VERSION ""

NS_ :

BS_:

BU_: TM

BO_ 475 HU_IC_Event_WarningAlert_Ack: 8 Vector__XXX
 SG_ HuIcAlertFeatureTypeAck : 5|2@0+ (1,0) [0|3] ""  TM
 SG_ HuIcAlertFeaturePresenceAck : 7|1@0+ (1,0) [0|1] ""  TM

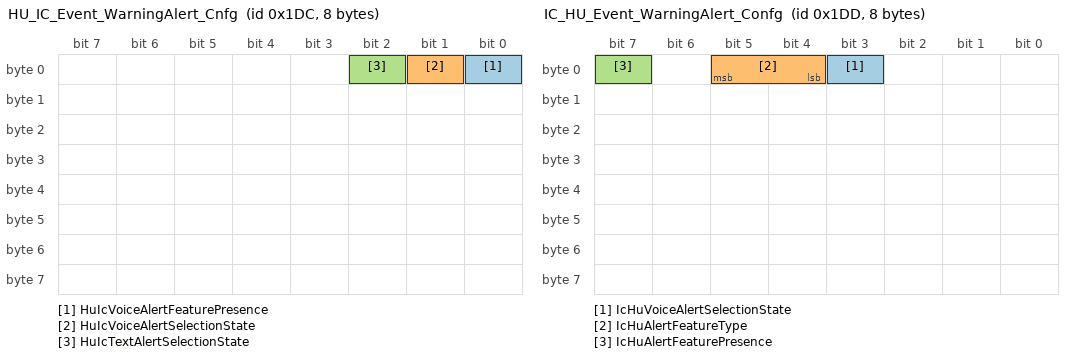
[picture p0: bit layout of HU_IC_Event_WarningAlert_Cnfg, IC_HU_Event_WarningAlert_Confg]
BO_ 476 HU_IC_Event_WarningAlert_Cnfg: 8 Vector__XXX
 SG_ HuIcVoiceAlertFeaturePresence : 0|1@0+ (1,0) [0|1] ""  TM
 SG_ HuIcVoiceAlertSelectionState : 1|1@0+ (1,0) [0|1] ""  TM
 SG_ HuIcTextAlertSelectionState : 2|1@0+ (1,0) [0|1] ""  TM

BO_ 477 IC_HU_Event_WarningAlert_Confg: 8 Vector__XXX
 SG_ IcHuVoiceAlertSelectionState : 3|1@0+ (1,0) [0|1] ""  TM
 SG_ IcHuAlertFeatureType : 5|2@0+ (1,0) [0|3] ""  TM
 SG_ IcHuAlertFeaturePresence : 7|1@0+ (1,0) [0|1] ""  TM

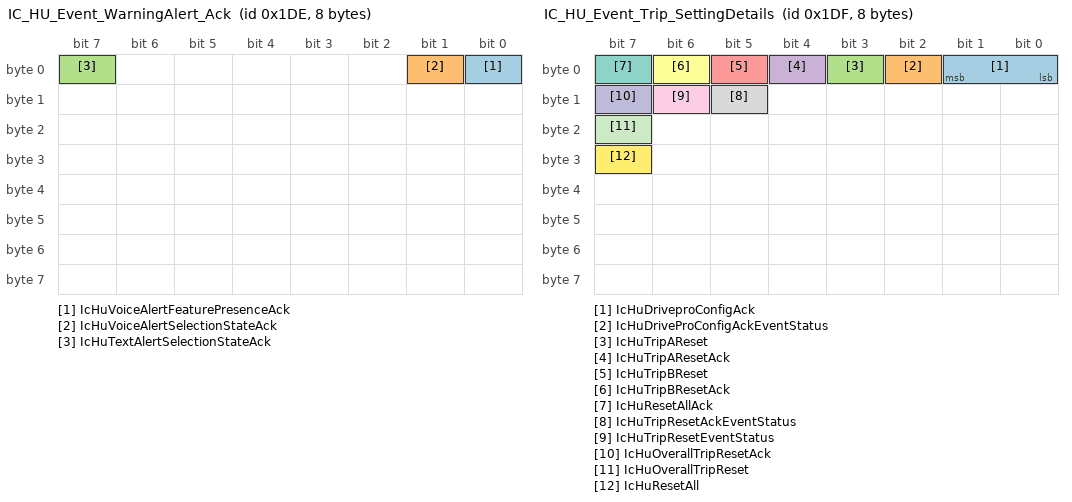
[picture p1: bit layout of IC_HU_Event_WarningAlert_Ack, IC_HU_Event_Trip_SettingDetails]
BO_ 478 IC_HU_Event_WarningAlert_Ack: 8 Vector__XXX
 SG_ IcHuVoiceAlertFeaturePresenceAck : 0|1@0+ (1,0) [0|1] ""  TM
 SG_ IcHuVoiceAlertSelectionStateAck : 1|1@0+ (1,0) [0|1] ""  TM
 SG_ IcHuTextAlertSelectionStateAck : 7|1@0+ (1,0) [0|1] ""  TM

BO_ 479 IC_HU_Event_Trip_SettingDetails: 8 Vector__XXX
 SG_ IcHuDriveproConfigAck : 1|2@0+ (1,0) [0|3] ""  TM
 SG_ IcHuDriveProConfigAckEventStatus : 2|1@0+ (1,0) [0|1] ""  TM
 SG_ IcHuTripAReset : 3|1@0+ (1,0) [0|1] ""  TM
 SG_ IcHuTripAResetAck : 4|1@0+ (1,0) [0|1] ""  TM
 SG_ IcHuTripBReset : 5|1@0+ (1,0) [0|1] ""  TM
 SG_ IcHuTripBResetAck : 6|1@0+ (1,0) [0|1] ""  TM
 SG_ IcHuResetAllAck : 7|1@0+ (1,0) [0|1] ""  TM
 SG_ IcHuTripResetAckEventStatus : 13|1@0+ (1,0) [0|1] ""  TM
 SG_ IcHuTripResetEventStatus : 14|1@0+ (1,0) [0|1] ""  TM
 SG_ IcHuOverallTripResetAck : 15|1@0+ (1,0) [0|1] ""  TM
 SG_ IcHuOverallTripReset : 23|1@0+ (1,0) [0|1] ""  TM
 SG_ IcHuResetAll : 31|1@0+ (1,0) [0|1] ""  TM

BO_ 480 BCM_PEPS_Event_UIDAuthState: 8 Vector__XXX
 SG_ UIDAuthState : 1|2@0+ (1,0) [0|3] ""  TM

BO_ 484 PEPSBCMEventMsg_RC: 8 Vector__XXX
 SG_ UnLockTailgageCommand : 0|1@0+ (1,0) [0|1] ""  TM
 SG_ UnLockAllDoorCommand : 1|1@0+ (1,0) [0|1] ""  TM
 SG_ UnLockDrDoorCommandStatus : 3|2@0+ (1,0) [0|3] ""  TM
 SG_ UnLockDrDoorCommand : 4|1@0+ (1,0) [0|1] ""  TM
 SG_ VehicleLockCommandStatus : 6|2@0+ (1,0) [0|3] ""  TM
 SG_ VehicleLockCommand : 7|1@0+ (1,0) [0|1] ""  TM
 SG_ ForcePanicCommand : 8|1@0+ (1,0) [0|1] ""  TM
 SG_ ApproachLighCommandStatus : 10|2@0+ (1,0) [0|3] ""  TM
 SG_ ApproachLighCommand : 11|1@0+ (1,0) [0|1] ""  TM
 SG_ UnLockTailgageCommandStatus : 13|2@0+ (1,0) [0|3] ""  TM
 SG_ UnLockAllDoorCommandStatus : 15|2@0+ (1,0) [0|3] ""  TM
 SG_ WindowUpCommandStatus : 17|2@0+ (1,0) [0|3] ""  TM
 SG_ WindowUpCommand : 18|1@0+ (1,0) [0|1] ""  TM
 SG_ WindowDownCommandStatus : 20|2@0+ (1,0) [0|3] ""  TM
 SG_ WindowDownCommand : 21|1@0+ (1,0) [0|1] ""  TM
 SG_ ForcePanicCommandStatus : 23|2@0+ (1,0) [0|3] ""  TM
 SG_ Reserved : 28|5@0+ (1,0) [0|31] ""  TM
 SG_ VehicleSeekCommandStatus : 30|2@0+ (1,0) [0|3] ""  TM
 SG_ VehicleSeekCommand : 31|1@0+ (1,0) [0|1] ""  TM
 SG_ RandomNumber0 : 39|8@0+ (1,0) [0|255] ""  TM
 SG_ RandomNumber1 : 47|8@0+ (1,0) [0|255] ""  TM
 SG_ RandomNumber2 : 55|8@0+ (1,0) [0|255] ""  TM
 SG_ RandomNumber3 : 63|8@0+ (1,0) [0|255] ""  TM

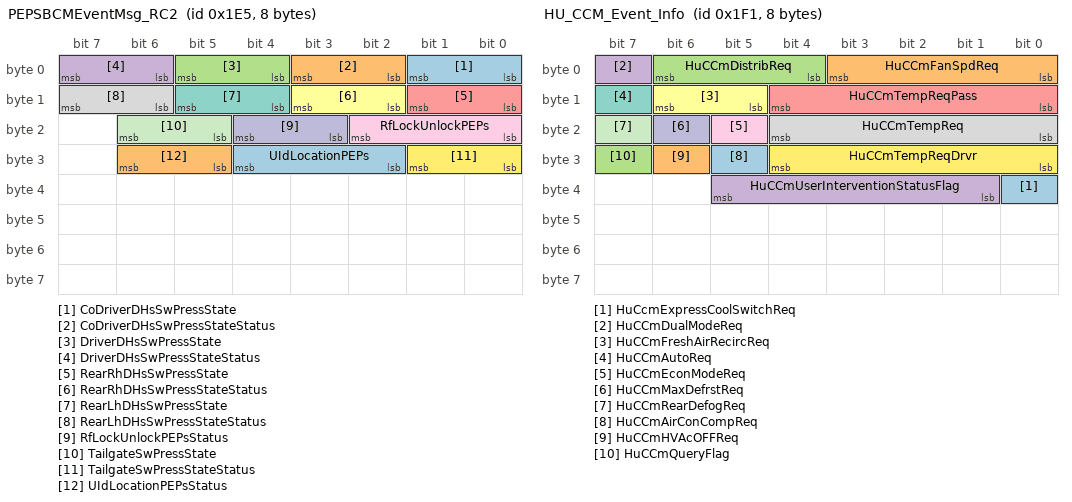
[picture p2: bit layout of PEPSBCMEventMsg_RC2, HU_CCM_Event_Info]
BO_ 485 PEPSBCMEventMsg_RC2: 8 Vector__XXX
 SG_ CoDriverDHsSwPressState : 1|2@0+ (1,0) [0|3] ""  TM
 SG_ CoDriverDHsSwPressStateStatus : 3|2@0+ (1,0) [0|3] ""  TM
 SG_ DriverDHsSwPressState : 5|2@0+ (1,0) [0|3] ""  TM
 SG_ DriverDHsSwPressStateStatus : 7|2@0+ (1,0) [0|3] ""  TM
 SG_ RearRhDHsSwPressState : 9|2@0+ (1,0) [0|3] ""  TM
 SG_ RearRhDHsSwPressStateStatus : 11|2@0+ (1,0) [0|3] ""  TM
 SG_ RearLhDHsSwPressState : 13|2@0+ (1,0) [0|3] ""  TM
 SG_ RearLhDHsSwPressStateStatus : 15|2@0+ (1,0) [0|3] ""  TM
 SG_ RfLockUnlockPEPs : 18|3@0+ (1,0) [0|7] ""  TM
 SG_ RfLockUnlockPEPsStatus : 20|2@0+ (1,0) [0|3] ""  TM
 SG_ TailgateSwPressState : 22|2@0+ (1,0) [0|3] ""  TM
 SG_ TailgateSwPressStateStatus : 25|2@0+ (1,0) [0|3] ""  TM
 SG_ UIdLocationPEPs : 28|3@0+ (1,0) [0|7] ""  TM
 SG_ UIdLocationPEPsStatus : 30|2@0+ (1,0) [0|3] ""  TM

BO_ 486 PEPSESCLAuthReq_RC: 8 Vector__XXX
 SG_ PEPsESClAuthReq : 7|64@0+ (1,0) [0|0] ""  TM

BO_ 488 ESCLPEPSAuthReq_RC: 8 Vector__XXX
 SG_ ESClPEPsAuthReq : 7|64@0+ (1,0) [0|0] ""  TM

BO_ 490 PEPSVIdeninfoEvent: 8 Vector__XXX
 SG_ VInInfoToIPC : 7|40@0+ (1,0) [0|0] ""  TM

BO_ 492 VehIdetNumIPCEvent: 8 Vector__XXX
 SG_ VehIdetNumIPC : 7|40@0+ (1,0) [0|0] ""  TM

BO_ 494 PEPSBCMEventMsgEncypt_RC: 8 Vector__XXX
 SG_ PEPsBCmAuthMsg2 : 7|64@0+ (1,0) [0|0] "ASCII"  TM

BO_ 497 HU_CCM_Event_Info: 8 Vector__XXX
 SG_ HuCcmExpressCoolSwitchReq : 32|1@0+ (1,0) [0|1] ""  TM
 SG_ HuCCmFanSpdReq : 3|4@0+ (1,0) [0|15] ""  TM
 SG_ HuCCmDistribReq : 6|3@0+ (1,0) [0|7] ""  TM
 SG_ HuCCmDualModeReq : 7|1@0+ (1,0) [0|1] ""  TM
 SG_ HuCCmTempReqPass : 12|5@0+ (0.5,0) [0|31] "Deg "  TM
 SG_ HuCCmFreshAirRecircReq : 14|2@0+ (1,0) [0|3] ""  TM
 SG_ HuCCmAutoReq : 15|1@0+ (1,0) [0|1] ""  TM
 SG_ HuCCmTempReq : 20|5@0+ (0.5,0) [0|31] "Deg "  TM
 SG_ HuCCmEconModeReq : 21|1@0+ (1,0) [0|1] ""  TM
 SG_ HuCCmMaxDefrstReq : 22|1@0+ (1,0) [0|1] ""  TM
 SG_ HuCCmRearDefogReq : 23|1@0+ (1,0) [0|1] ""  TM
 SG_ HuCCmTempReqDrvr : 28|5@0+ (0.5,0) [0|31] "Deg "  TM
 SG_ HuCCmAirConCompReq : 29|1@0+ (1,0) [0|1] ""  TM
 SG_ HuCCmHVAcOFFReq : 30|1@0+ (1,0) [0|1] ""  TM
 SG_ HuCCmQueryFlag : 31|1@0+ (1,0) [0|1] ""  TM
 SG_ HuCCmUserInterventionStatusFlag : 37|5@0+ (1,0) [0|31] ""  TM

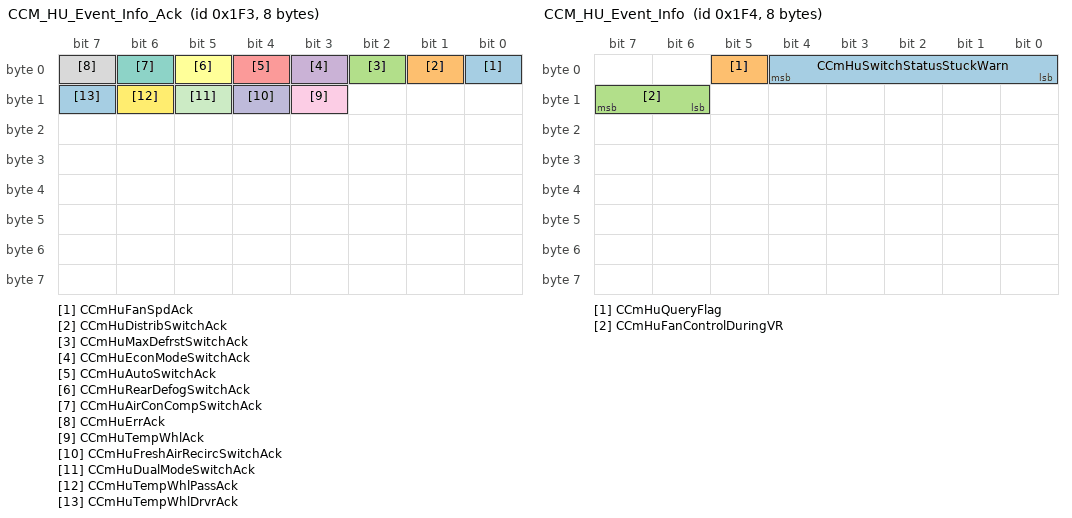
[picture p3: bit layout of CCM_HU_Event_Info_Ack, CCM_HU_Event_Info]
BO_ 499 CCM_HU_Event_Info_Ack: 8 Vector__XXX
 SG_ CCmHuFanSpdAck : 0|1@0+ (1,0) [0|1] ""  TM
 SG_ CCmHuDistribSwitchAck : 1|1@0+ (1,0) [0|1] ""  TM
 SG_ CCmHuMaxDefrstSwitchAck : 2|1@0+ (1,0) [0|1] ""  TM
 SG_ CCmHuEconModeSwitchAck : 3|1@0+ (1,0) [0|1] ""  TM
 SG_ CCmHuAutoSwitchAck : 4|1@0+ (1,0) [0|1] ""  TM
 SG_ CCmHuRearDefogSwitchAck : 5|1@0+ (1,0) [0|1] ""  TM
 SG_ CCmHuAirConCompSwitchAck : 6|1@0+ (1,0) [0|1] ""  TM
 SG_ CCmHuErrAck : 7|1@0+ (1,0) [0|1] ""  TM
 SG_ CCmHuTempWhlAck : 11|1@0+ (1,0) [0|1] ""  TM
 SG_ CCmHuFreshAirRecircSwitchAck : 12|1@0+ (1,0) [0|1] ""  TM
 SG_ CCmHuDualModeSwitchAck : 13|1@0+ (1,0) [0|1] ""  TM
 SG_ CCmHuTempWhlPassAck : 14|1@0+ (1,0) [0|1] ""  TM
 SG_ CCmHuTempWhlDrvrAck : 15|1@0+ (1,0) [0|1] ""  TM

BO_ 500 CCM_HU_Event_Info: 8 Vector__XXX
 SG_ CCmHuSwitchStatusStuckWarn : 4|5@0+ (1,0) [0|31] ""  TM
 SG_ CCmHuQueryFlag : 5|1@0+ (1,0) [0|1] ""  TM
 SG_ CCmHuFanControlDuringVR : 15|2@0+ (1,0) [0|3] ""  TM

BO_ 504 BCM_HU_Event_UCS_Feature: 8 Vector__XXX
 SG_ BCmAutoRelockActiveSignalVal : 0|1@0+ (1,0) [0|1] ""  TM
 SG_ BCmFMhActiveSignalVal : 2|2@0+ (1,0) [0|3] ""  TM
 SG_ BCmFMhSignalVal1 : 7|5@0+ (10,0) [0|310] "Sec"  TM
 SG_ BCmVehLockHornReqActiveSignalVal : 8|1@0+ (1,0) [0|1] ""  TM
 SG_ BCmApproachLampActiveSignalVal : 10|2@0+ (1,0) [0|3] ""  TM
 SG_ BCmFMhSignalVal2 : 15|5@0+ (10,0) [0|310] "Sec"  TM
 SG_ BCmDriveAwayLockingActiveSignalV : 16|1@0+ (1,0) [0|1] ""  TM
 SG_ BCmRKeUnlockState : 17|1@0+ (1,0) [0|1] ""  TM
 SG_ BCmPKeUnlockState : 18|1@0+ (1,0) [0|1] ""  TM
 SG_ BCmFMhSignalVal3 : 23|5@0+ (10,0) [0|310] "Sec"  TM
 SG_ BCmAutoRelockState : 24|1@0+ (1,0) [0|1] ""  TM
 SG_ BCmFMhState : 25|1@0+ (1,0) [0|1] ""  TM
 SG_ BCmUCsState : 26|1@0+ (1,0) [0|1] ""  TM
 SG_ BCmApproachLampSignalVal1 : 31|5@0+ (10,0) [0|310] "Sec"  TM
 SG_ BCmPKeUnlockActiveSignalVal : 32|1@0+ (1,0) [0|1] ""  TM
 SG_ BCmRKeUnlockActiveSignalVal : 33|1@0+ (1,0) [0|1] ""  TM
 SG_ BCmDriveAwayLockingState : 34|1@0+ (1,0) [0|1] ""  TM
 SG_ BCmApproachLampSignalVal2 : 39|5@0+ (10,0) [0|310] "Sec"  TM
 SG_ AmbLightModeIllumOnHu : 40|1@0+ (1,0) [0|1] ""  TM
 SG_ BCmApproachLampState : 41|1@0+ (1,0) [0|1] ""  TM
 SG_ BCmVehLockHornReqState : 42|1@0+ (1,0) [0|1] ""  TM
 SG_ BCmApproachLampSignalVal3 : 47|5@0+ (10,0) [0|310] "Sec"  TM
 SG_ BCmDRLActiveSignalVal : 51|1@0+ (1,0) [0|1] ""  TM
 SG_ BCmDRLState : 52|1@0+ (1,0) [0|1] ""  TM
 SG_ BCmMoodLightState : 53|1@0+ (1,0) [0|1] ""  TM
 SG_ BCmUcsData : 55|2@0+ (1,0) [0|3] ""  TM

BO_ 505 BCM_HU_Event_Mood_Light_Feature: 8 Vector__XXX
 SG_ BCmMoodLightAllAreaActiveValue : 0|1@0+ (1,0) [0|1] ""  TM
 SG_ BCmMoodLightIllumSelActiveVal : 3|3@0+ (1,0) [0|7] ""  TM
 SG_ BCmMoodLightActiveColour : 7|4@0+ (1,0) [0|15] ""  TM
 SG_ BCmMoodLightRearAreaActiveValue : 8|1@0+ (1,0) [0|1] ""  TM
 SG_ BCmMoodLightFrontRHAreaActiveVal : 9|1@0+ (1,0) [0|1] ""  TM
 SG_ BCmMoodLightFloorConsoleAreaActi : 10|1@0+ (1,0) [0|1] ""  TM
 SG_ BCmMoodLightData : 12|2@0+ (1,0) [0|3] ""  TM
 SG_ BCmMoodLightIllumPossibleLevels : 15|3@0+ (1,0) [0|7] ""  TM
 SG_ BCmMoodLightHotMagentaColorSelOn : 16|1@0+ (1,0) [0|1] ""  TM
 SG_ BCmMoodLightGoldYellowColorSelOn : 17|1@0+ (1,0) [0|1] ""  TM
 SG_ BCmMoodLightFrenchLimeColorSelOn : 18|1@0+ (1,0) [0|1] ""  TM
 SG_ BCmMoodLightFrontLHAreaActiveVal : 19|1@0+ (1,0) [0|1] ""  TM
 SG_ BCmMoodLightPossibleModes : 21|2@0+ (1,0) [0|3] ""  TM
 SG_ BCmMoodLightActiveModeValue : 23|2@0+ (1,0) [0|3] ""  TM
 SG_ BCmMoodLightPolarBrightWhiteColo : 24|1@0+ (1,0) [0|1] ""  TM
 SG_ BCmMoodLightAeroBlueColorSelOnHU : 25|1@0+ (1,0) [0|1] ""  TM
 SG_ BCmMoodLightPurpleColorSelOnHU : 26|1@0+ (1,0) [0|1] ""  TM
 SG_ BCmMoodLightFluorescentGreenColo : 27|1@0+ (1,0) [0|1] ""  TM
 SG_ BCmMoodLightCyanBlueColorSelOnHU : 28|1@0+ (1,0) [0|1] ""  TM
 SG_ BCmMoodLightCoolBlueColorSelOnHU : 29|1@0+ (1,0) [0|1] ""  TM
 SG_ BCmMoodLightIvoryOFFWhiteColorSe : 30|1@0+ (1,0) [0|1] ""  TM
 SG_ BCmMoodLightIceBlueColorSelOnHU : 31|1@0+ (1,0) [0|1] ""  TM
 SG_ BCmMoodLightTuscanRedColorSelOnH : 32|1@0+ (1,0) [0|1] ""  TM
 SG_ BCmMoodLightTealGreenColorSelOnH : 33|1@0+ (1,0) [0|1] ""  TM
 SG_ BCmMoodLightRubyRedColorSelOnHU : 34|1@0+ (1,0) [0|1] ""  TM
 SG_ BCmMoodLightOrangeColorSelOnHU : 35|1@0+ (1,0) [0|1] ""  TM
 SG_ BCmMoodLightPurpleTaupeColorSelO : 36|1@0+ (1,0) [0|1] ""  TM
 SG_ BCmMoodLightLocationSel : 37|1@0+ (1,0) [0|1] ""  TM
 SG_ BCmMoodLightAllAreaSelOnHU : 38|1@0+ (1,0) [0|1] ""  TM
 SG_ BCmMoodLightFrontLHAreaSelOnHU : 39|1@0+ (1,0) [0|1] ""  TM
 SG_ BCmMoodLightRearAreaSelOnHU : 40|1@0+ (1,0) [0|1] ""  TM
 SG_ BCmMoodLightFloorConsoleAreaSelO : 41|1@0+ (1,0) [0|1] ""  TM
 SG_ BCmMoodLightState : 42|1@0+ (1,0) [0|1] ""  TM
 SG_ BCmMoodLightFrontRHAreaSelOnHU : 43|1@0+ (1,0) [0|1] ""  TM

CM_ SG_ 475 HuIcAlertFeatureTypeAck "This signal is transmitted to IC to acknowledge after HMI settings";
CM_ SG_ 475 HuIcAlertFeaturePresenceAck "Ack from HU for Alert feature presence";
CM_ SG_ 476 HuIcVoiceAlertFeaturePresence "This signal is transmitted to IC to know voice alert feature presence in vehicle.";
CM_ SG_ 476 HuIcVoiceAlertSelectionState "This signal is transmitted to IC to know selection state of voice alert feature..";
CM_ SG_ 476 HuIcTextAlertSelectionState "Informs Text alert selection state";
CM_ SG_ 477 IcHuVoiceAlertSelectionState "HU shall update the Voice Alert HMI selection state";
CM_ SG_ 477 IcHuAlertFeatureType "Informs the type of alert configured in cluster";
CM_ SG_ 477 IcHuAlertFeaturePresence "Informes whether Alert feature is enabled or not";
CM_ SG_ 478 IcHuVoiceAlertFeaturePresenceAck "This signal is transmitted to HU to know voice alert feature presence in vehicle";
CM_ SG_ 478 IcHuVoiceAlertSelectionStateAck "This signal is transmitted to HU to know selection state of voice alert feature.";
CM_ SG_ 478 IcHuTextAlertSelectionStateAck "Informes ack state of Text alert selection state";
CM_ SG_ 479 IcHuDriveproConfigAck "IC shall send drive pro config Ack to HU";
CM_ SG_ 479 IcHuDriveProConfigAckEventStatus "IC shall send Trip Config Ack Event Status to HU";
CM_ SG_ 479 IcHuTripAReset "IC shall send Trip A Reset to HU";
CM_ SG_ 479 IcHuTripAResetAck "IC shall send Trip A Reset Ack to HU";
CM_ SG_ 479 IcHuTripBReset "IC shall send Trip B Reset to HU";
CM_ SG_ 479 IcHuTripBResetAck "IC shall send Trip B Reset Ack to HU";
CM_ SG_ 479 IcHuResetAllAck "IC shall send Reset All Ack to HU";
CM_ SG_ 479 IcHuTripResetAckEventStatus "IC shall send Trip Reset Ack Event Status to HU";
CM_ SG_ 479 IcHuTripResetEventStatus "IC shall send Trip Reset Event Status to HU";
CM_ SG_ 479 IcHuOverallTripResetAck "IC shall send Overall trip Reset Ack to HU";
CM_ SG_ 479 IcHuOverallTripReset "IC shall send overall Trip Reset to HU";
CM_ SG_ 479 IcHuResetAll "IC shall send Trip A, B and Overall Reset to HU";
CM_ SG_ 480 UIDAuthState "UID authentication  response to PEPS ECU from BCM";
CM_ SG_ 484 UnLockTailgageCommand "Unlock Tailgate Command signal";
CM_ SG_ 484 UnLockAllDoorCommand "Unlock All Door Command signal";
CM_ SG_ 484 UnLockDrDoorCommandStatus "Status of the UnLockDrDoorCommand signal";
CM_ SG_ 484 UnLockDrDoorCommand "Unlock Driver Door Command signa";
CM_ SG_ 484 VehicleLockCommandStatus "Status of the 'VehicleLockCommand' signal";
CM_ SG_ 484 VehicleLockCommand "Vehicle lock command signal";
CM_ SG_ 484 ForcePanicCommand "Force panic command signal";
CM_ SG_ 484 ApproachLighCommandStatus "Status of the UnLockTailgageCommand signal";
CM_ SG_ 484 ApproachLighCommand "Apporoach Light Command signal";
CM_ SG_ 484 UnLockTailgageCommandStatus "Status of the UnLockTailgageCommand signal";
CM_ SG_ 484 UnLockAllDoorCommandStatus "Status of the UnLockAllDoorCommand signal";
CM_ SG_ 484 WindowUpCommandStatus "Status of the WindowUpCommand signal";
CM_ SG_ 484 WindowUpCommand "Window Up Command signal";
CM_ SG_ 484 WindowDownCommandStatus "Status of the WindowDownCommand signal";
CM_ SG_ 484 WindowDownCommand "Window Down Command signal";
CM_ SG_ 484 ForcePanicCommandStatus "Status of the ForcePanicCommand signal";
CM_ SG_ 484 Reserved "Reserved Bits";
CM_ SG_ 484 VehicleSeekCommandStatus "Status of the VehicleSeekCommand signal";
CM_ SG_ 484 VehicleSeekCommand "Vehicle Seek Command signal";
CM_ SG_ 484 RandomNumber0 "Random Number0";
CM_ SG_ 484 RandomNumber1 "RandomNumber1";
CM_ SG_ 484 RandomNumber2 "RandomNumber2";
CM_ SG_ 484 RandomNumber3 "RandomNumber3";
CM_ SG_ 485 CoDriverDHsSwPressState "CAN Signals From PEPS to BCM for Individual Door Lock / Unlock - Co-Driver DHS Switch Press Status";
CM_ SG_ 485 CoDriverDHsSwPressStateStatus "Status of 'CoDriverDHsSwPressState' signal";
CM_ SG_ 485 DriverDHsSwPressState "CAN Signals From PEPS to BCM for Individual Door Lock / Unlock - Driver DHS Switch Press Status";
CM_ SG_ 485 DriverDHsSwPressStateStatus "Status of 'DriverDHsSwPressState' signal";
CM_ SG_ 485 RearRhDHsSwPressState "CAN Signals From PEPS to BCM for Individual Door Lock / Unlock - Rear RH DHs Switch Press Status";
CM_ SG_ 485 RearRhDHsSwPressStateStatus "Status of 'RearRhDHsSwPressState' signal";
CM_ SG_ 485 RearLhDHsSwPressState "CAN Signals From PEPS to BCM for Individual Door Lock / Unlock - Rear LH DHs Switch Press Status";
CM_ SG_ 485 RearLhDHsSwPressStateStatus "Status of 'RearLhDHsSwPressState' signal";
CM_ SG_ 485 RfLockUnlockPEPs "CAN Signals From PEPS to BCM for Individual Door Lock / Unlock - RF Lock Unlock Command From PEPS";
CM_ SG_ 485 RfLockUnlockPEPsStatus "Status of 'RfLockUnlockPEPs' signal";
CM_ SG_ 485 TailgateSwPressState "CAN Signals From PEPS to BCM for Individual Door Lock / Unlock - Tailgate Switch Press Status";
CM_ SG_ 485 TailgateSwPressStateStatus "Status of 'TailgateSwPressState' signal";
CM_ SG_ 485 UIdLocationPEPs "CAN Signals From PEPS to BCM for Individual Door Lock / Unlock - UID Location From PEPS";
CM_ SG_ 485 UIdLocationPEPsStatus "Status of 'UIdLocationPEPs' signal";
CM_ SG_ 486 PEPsESClAuthReq "ESCL. Immobilization signals from PEPS to ESCL while learning";
CM_ SG_ 488 ESClPEPsAuthReq " ESCL Immobilize to PEPS. Immobilization signals from ESCL to PEPS while learning";
CM_ SG_ 497 HuCcmExpressCoolSwitchReq "Request/Acknowledgement for Express Cooling feature ON or OFF";
CM_ SG_ 497 HuCCmFanSpdReq "Indicates the speed of the fan";
CM_ SG_ 497 HuCCmDistribReq "Indicates different value of distribution mode";
CM_ SG_ 497 HuCCmDualModeReq "Indicates whether the dual mode is ON or OFF";
CM_ SG_ 497 HuCCmTempReqPass "Indicates the left temperature value in Deg";
CM_ SG_ 497 HuCCmFreshAirRecircReq "Indicates the different values of fresh air recirculation mode";
CM_ SG_ 497 HuCCmAutoReq "Request for Auto mode ON or OFF";
CM_ SG_ 497 HuCCmTempReq "Indicates the temperature value in OC";
CM_ SG_ 497 HuCCmEconModeReq "Request to set the Economy mode to ON or OFF";
CM_ SG_ 497 HuCCmMaxDefrstReq "Request for maximum defrost control ON or OFF";
CM_ SG_ 497 HuCCmRearDefogReq "Request to change the  defog control to ON or OFF";
CM_ SG_ 497 HuCCmTempReqDrvr "Indicates the right temperature value OC";
CM_ SG_ 497 HuCCmAirConCompReq "request to set the AC to ON or OFF";
CM_ SG_ 497 HuCCmHVAcOFFReq "Request to turn ON or OFF the HVAC control panel";
CM_ SG_ 497 HuCCmQueryFlag "Query the CCM to send the missing Ack frame";
CM_ SG_ 497 HuCCmUserInterventionStatusFlag "Indicates which HVAC control user has operated";
CM_ SG_ 499 CCmHuFanSpdAck "Acknowledges the display update";
CM_ SG_ 499 CCmHuDistribSwitchAck "Acknowledges the display update";
CM_ SG_ 499 CCmHuMaxDefrstSwitchAck "Acknowledges the display update";
CM_ SG_ 499 CCmHuEconModeSwitchAck "Acknowledges the display update";
CM_ SG_ 499 CCmHuAutoSwitchAck "Acknowledges the display update";
CM_ SG_ 499 CCmHuRearDefogSwitchAck "Acknowledges the display update";
CM_ SG_ 499 CCmHuAirConCompSwitchAck "Acknowledges the display update";
CM_ SG_ 499 CCmHuErrAck "Acknowledges the display update";
CM_ SG_ 499 CCmHuTempWhlAck "Acknowledges the display update";
CM_ SG_ 499 CCmHuFreshAirRecircSwitchAck "Acknowledges the display update";
CM_ SG_ 499 CCmHuDualModeSwitchAck "Acknowledges the display update";
CM_ SG_ 499 CCmHuTempWhlPassAck "Acknowledges the display update";
CM_ SG_ 499 CCmHuTempWhlDrvrAck "Acknowledges the display update";
CM_ SG_ 500 CCmHuSwitchStatusStuckWarn "Indicates the button/s stuck status";
CM_ SG_ 500 CCmHuQueryFlag "Query the HU to send the missing frame";
CM_ SG_ 500 CCmHuFanControlDuringVR "To Control FAN speed during VR session";
CM_ SG_ 504 BCmAutoRelockActiveSignalVal "Active Value for Vehicle Auto Relock Feature";
CM_ SG_ 504 BCmFMhActiveSignalVal "Active value for Follow Me Home feature";
CM_ SG_ 504 BCmFMhSignalVal1 "1st Possible value for Follow Me Home Feature";
CM_ SG_ 504 BCmVehLockHornReqActiveSignalVal "Active Value for Vehicle Lock Horn Request feature";
CM_ SG_ 504 BCmApproachLampActiveSignalVal "Active value for Approach Lamp Active feature";
CM_ SG_ 504 BCmFMhSignalVal2 "2nd Possible value for Follow Me Home Feature";
CM_ SG_ 504 BCmDriveAwayLockingActiveSignalV "Active Value for Vehicle Drive Away Feature";
CM_ SG_ 504 BCmRKeUnlockState "Vehicle unlock with RKE Feature - Enable / Disable";
CM_ SG_ 504 BCmPKeUnlockState "Vehicle unlock with PKE Feature - Enable / Disable";
CM_ SG_ 504 BCmFMhSignalVal3 "3rd Possible value for Follow Me Home Feature";
CM_ SG_ 504 BCmAutoRelockState "Auto relock function Feature - Enable / Disable";
CM_ SG_ 504 BCmFMhState "Follow Me Home Feature - Enable / Disable";
CM_ SG_ 504 BCmUCsState "User customisation settings feature enable/disable parameter published by BCM";
CM_ SG_ 504 BCmApproachLampSignalVal1 "1st Possible value for Approach Lamp Feature";
CM_ SG_ 504 BCmPKeUnlockActiveSignalVal "Active Value for Vehicle Unlock with PKE Feature";
CM_ SG_ 504 BCmRKeUnlockActiveSignalVal "Active Value for Vehicle Unlock with RKE Feature";
CM_ SG_ 504 BCmDriveAwayLockingState "Drive away locking Feature - Enable / Disable";
CM_ SG_ 504 BCmApproachLampSignalVal2 "2nd Possible value for Approach Lamp Feature";
CM_ SG_ 504 AmbLightModeIllumOnHu "Mode and Illumination Display on HU send by BCM";
CM_ SG_ 504 BCmApproachLampState "Approach lamp Feature - Enable / Disable";
CM_ SG_ 504 BCmVehLockHornReqState "Horn request on vehicle lock Feature - Enable / Disable";
CM_ SG_ 504 BCmApproachLampSignalVal3 "3rd Possible value for Approach Lamp Feature";
CM_ SG_ 504 BCmDRLActiveSignalVal "Active Value for DRL Feature";
CM_ SG_ 504 BCmDRLState "DRL Feature - Enable / Disable";
CM_ SG_ 504 BCmMoodLightState "Current state of Mood Lighting from BCM to HU.";
CM_ SG_ 504 BCmUcsData "BCM sends UCS config data or give acknowledgement to HU.";
CM_ SG_ 505 BCmMoodLightAllAreaActiveValue "Current status of All area location selection from BCM to HU";
CM_ SG_ 505 BCmMoodLightIllumSelActiveVal "Current mood light illumination from BCM to HU";
CM_ SG_ 505 BCmMoodLightActiveColour "Mood light Active Colour from BCM to HU";
CM_ SG_ 505 BCmMoodLightRearAreaActiveValue "Current status of Rear area location selection from BCM to HU";
CM_ SG_ 505 BCmMoodLightFrontRHAreaActiveVal "Current status of driver area location selection from BCM to HU";
CM_ SG_ 505 BCmMoodLightFloorConsoleAreaActi "Current status of Floor area location selection from BCM to HU";
CM_ SG_ 505 BCmMoodLightData "BCM sends Mood light data frame or give acknowledgement to HU.";
CM_ SG_ 505 BCmMoodLightIllumPossibleLevels "Mood Light Number of illumination levels  to be displayed on HU send by BCM";
CM_ SG_ 505 BCmMoodLightHotMagentaColorSelOn "Mood light Hot Magenta colour selection on HU sent by BCM";
CM_ SG_ 505 BCmMoodLightGoldYellowColorSelOn "Mood light Gold Yellow colour selection on HU sent by BCM";
CM_ SG_ 505 BCmMoodLightFrenchLimeColorSelOn "Mood light French Lime colour selection on HU sent by BCM";
CM_ SG_ 505 BCmMoodLightFrontLHAreaActiveVal "Current status of co-driver area location selection from BCM to HU";
CM_ SG_ 505 BCmMoodLightPossibleModes "Mood light Possible Modes from BCM to HU";
CM_ SG_ 505 BCmMoodLightActiveModeValue "Mood light active mode from BCM to HU
";
CM_ SG_ 505 BCmMoodLightPolarBrightWhiteColo "Mood light polar colour selection on HU sent by BCM";
CM_ SG_ 505 BCmMoodLightAeroBlueColorSelOnHU "Mood light Aero Blue colour selection on HU sent by BCM";
CM_ SG_ 505 BCmMoodLightPurpleColorSelOnHU "Mood light purple colour selection on HU sent by BCM";
CM_ SG_ 505 BCmMoodLightFluorescentGreenColo "Mood lightFluroscent Green colour selection on HU sent by BCM";
CM_ SG_ 505 BCmMoodLightCyanBlueColorSelOnHU "Mood light Cyan Blue colour selection on HU sent by BCM";
CM_ SG_ 505 BCmMoodLightCoolBlueColorSelOnHU "Mood light Cool Blue color selection on HU sent by BCM";
CM_ SG_ 505 BCmMoodLightIvoryOFFWhiteColorSe "Mood light Ivory colour selection on HU sent by BCM";
CM_ SG_ 505 BCmMoodLightIceBlueColorSelOnHU "Mood light Ice Blue color selection on HU sent by BCM";
CM_ SG_ 505 BCmMoodLightTuscanRedColorSelOnH "Mood light Tuscan Red colour selection on HU sent by BCM";
CM_ SG_ 505 BCmMoodLightTealGreenColorSelOnH "Mood light Teal Green colour selection on HU sent by BCM";
CM_ SG_ 505 BCmMoodLightRubyRedColorSelOnHU "Mood light Ruby Red colour selection on HU sent by BCM";
CM_ SG_ 505 BCmMoodLightOrangeColorSelOnHU "Mood light Orange colour selection on HU sent by BCM";
CM_ SG_ 505 BCmMoodLightPurpleTaupeColorSelO "Mood light Purple Taupe colour selection on HU sent by BCM";
CM_ SG_ 505 BCmMoodLightLocationSel "Mood Lighting Location selection on HU";
CM_ SG_ 505 BCmMoodLightAllAreaSelOnHU "Mood Light All area location selection on HU send by BCM";
CM_ SG_ 505 BCmMoodLightFrontLHAreaSelOnHU "Mood Light co-driver area location selection on HU send by BCM";
CM_ SG_ 505 BCmMoodLightRearAreaSelOnHU "Mood Light Rear area location selection on HU send by BCM";
CM_ SG_ 505 BCmMoodLightFloorConsoleAreaSelO "Mood Light Floor Console area location selection on HU send by BCM";
CM_ SG_ 505 BCmMoodLightState "Current state of Mood Lighting from BCM to HU.";
CM_ SG_ 505 BCmMoodLightFrontRHAreaSelOnHU "Mood Light driver area location selection on HU send by BCM";
BA_DEF_ SG_  "Remarks" STRING ;
BA_DEF_ SG_  "NWM_WakeupAllowed" ENUM  "No","Yes";
BA_DEF_ SG_  "GenSigTimeoutTime_HU_Mid_X451" INT 0 65535;
BA_DEF_ SG_  "GenSigTimeoutTime_HU_High_X451" INT 0 65535;
BA_DEF_ SG_  "GenSigTimeoutTime_HU_B" INT 0 65535;
BA_DEF_ SG_  "GenSigTimeoutTime_HU_A" INT 0 65535;
BA_DEF_ SG_  "GenSigTimeoutTime_BCM_Mid" INT 0 65535;
BA_DEF_ SG_  "GenSigTimeoutMsg_HU_Mid_X451" INT 0 65535;
BA_DEF_ SG_  "GenSigTimeoutMsg_HU_High_X451" INT 0 65535;
BA_DEF_ SG_  "GenSigTimeoutMsg_HU_B" INT 0 65535;
BA_DEF_ SG_  "GenSigTimeoutMsg_HU_A" INT 0 65535;
BA_DEF_ SG_  "GenSigStartValue" INT 0 0;
BA_DEF_ SG_  "GenSigSendType" ENUM  "Cyclic","OnWrite","OnWriteWithRepetition","OnChange","OnChangeWithRepetition","IfActive","IfActiveWithRepetition","NoSigSendType","NotUsed","NotUsed","NotUsed","NotUsed","NotUsed";
BA_DEF_ SG_  "GenSigInactiveValue" INT 0 0;
BA_DEF_ SG_  "GenSigEnvVarType" ENUM  "int","float","undef";
BA_DEF_ SG_  "GenSigCycleTimeActive" INT 0 0;
BA_DEF_ SG_  "GenSigCycleTime" INT 0 0;
BA_DEF_ SG_  "GenSigTimeoutMsg_HU_High_X445" INT 0 65535;
BA_DEF_ SG_  "GenSigTimeoutMsg_HU_Mid_X445" INT 0 65535;
BA_DEF_ SG_  "GenSigTimeoutTime_HU_High_X445" INT 0 65535;
BA_DEF_ SG_  "GenSigTimeoutTime_HU_Mid_X445" INT 0 65535;
BA_DEF_ SG_  "GenSigTimeoutMsg_IVI" INT 0 65535;
BA_DEF_ SG_  "GenSigTimeoutTime_IVI" INT 0 65535;
BA_DEF_ BO_  "NmMessage" ENUM  "no","yes";
BA_DEF_ BO_  "NmAsrMessage" ENUM  "<n.a.>","No","Yes";
BA_DEF_ BO_  "MessageTimeout" INT 0 65535;
BA_DEF_ BO_  "Me" INT 0 0;
BA_DEF_ BO_  "GenMsgStartDelayTime" INT 0 0;
BA_DEF_ BO_  "GenMsgSendType" ENUM  "Cyclic","NotUsed","NotUsed","NotUsed","NotUsed","NotUsed","NotUsed","IfActive","NoMsgSendType","NotUsed";
BA_DEF_ BO_  "GenMsgNrOfRepetition" INT 0 0;
BA_DEF_ BO_  "GenMsgILSupport" ENUM  "No","Yes";
BA_DEF_ BO_  "GenMsgDelayTime" INT 0 0;
BA_DEF_ BO_  "GenMsgCycleTimeFast" INT 0 0;
BA_DEF_ BO_  "GenMsgCycleTime" INT 0 0;
BA_DEF_ BO_  "DiagUudtResponse" ENUM  "false","true";
BA_DEF_ BO_  "DiagUsdtResponse" ENUM  "false","true";
BA_DEF_ BO_  "DiagState" ENUM  "No","Yes";
BA_DEF_ BO_  "DiagResponse" ENUM  "No","Yes";
BA_DEF_ BO_  "DiagRequest" ENUM  "No","Yes";
BA_DEF_ BO_  "MsgType" ENUM  "Application","NM","NMH";
BA_DEF_ SG_  "SystemSignalLongSymbol" STRING ;
BA_DEF_DEF_  "Remarks" "null";
BA_DEF_DEF_  "NWM_WakeupAllowed" "No";
BA_DEF_DEF_  "GenSigTimeoutTime_HU_Mid_X451" 500;
BA_DEF_DEF_  "GenSigTimeoutTime_HU_High_X451" 500;
BA_DEF_DEF_  "GenSigTimeoutTime_HU_B" 500;
BA_DEF_DEF_  "GenSigTimeoutTime_HU_A" 500;
BA_DEF_DEF_  "GenSigTimeoutTime_BCM_Mid" 0;
BA_DEF_DEF_  "GenSigTimeoutMsg_HU_Mid_X451" 500;
BA_DEF_DEF_  "GenSigTimeoutMsg_HU_High_X451" 500;
BA_DEF_DEF_  "GenSigTimeoutMsg_HU_B" 500;
BA_DEF_DEF_  "GenSigTimeoutMsg_HU_A" 500;
BA_DEF_DEF_  "GenSigStartValue" 0;
BA_DEF_DEF_  "GenSigSendType" "Cyclic";
BA_DEF_DEF_  "GenSigInactiveValue" 0;
BA_DEF_DEF_  "GenSigEnvVarType" "undef";
BA_DEF_DEF_  "GenSigCycleTimeActive" 0;
BA_DEF_DEF_  "GenSigCycleTime" 0;
BA_DEF_DEF_  "GenSigTimeoutMsg_HU_High_X445" 500;
BA_DEF_DEF_  "GenSigTimeoutMsg_HU_Mid_X445" 500;
BA_DEF_DEF_  "GenSigTimeoutTime_HU_High_X445" 500;
BA_DEF_DEF_  "GenSigTimeoutTime_HU_Mid_X445" 500;
BA_DEF_DEF_  "GenSigTimeoutMsg_IVI" 500;
BA_DEF_DEF_  "GenSigTimeoutTime_IVI" 500;
BA_DEF_DEF_  "NmMessage" "no";
BA_DEF_DEF_  "NmAsrMessage" "<n.a.>";
BA_DEF_DEF_  "MessageTimeout" 500;
BA_DEF_DEF_  "Me" 0;
BA_DEF_DEF_  "GenMsgStartDelayTime" 0;
BA_DEF_DEF_  "GenMsgSendType" "Cyclic";
BA_DEF_DEF_  "GenMsgNrOfRepetition" 0;
BA_DEF_DEF_  "GenMsgILSupport" "Yes";
BA_DEF_DEF_  "GenMsgDelayTime" 0;
BA_DEF_DEF_  "GenMsgCycleTimeFast" 0;
BA_DEF_DEF_  "GenMsgCycleTime" 0;
BA_DEF_DEF_  "DiagUudtResponse" "false";
BA_DEF_DEF_  "DiagUsdtResponse" "false";
BA_DEF_DEF_  "DiagState" "No";
BA_DEF_DEF_  "DiagResponse" "No";
BA_DEF_DEF_  "DiagRequest" "No";
BA_DEF_DEF_  "MsgType" "Application";
BA_DEF_DEF_  "SystemSignalLongSymbol" "";
BA_ "MessageTimeout" BO_ 475 0;
BA_ "GenMsgSendType" BO_ 475 8;
BA_ "MessageTimeout" BO_ 476 0;
BA_ "GenMsgSendType" BO_ 476 8;
BA_ "MessageTimeout" BO_ 477 0;
BA_ "GenMsgSendType" BO_ 477 8;
BA_ "MessageTimeout" BO_ 478 0;
BA_ "GenMsgSendType" BO_ 478 8;
BA_ "MessageTimeout" BO_ 479 0;
BA_ "GenMsgSendType" BO_ 479 8;
BA_ "MessageTimeout" BO_ 480 0;
BA_ "MessageTimeout" BO_ 484 0;
BA_ "GenMsgSendType" BO_ 484 8;
BA_ "GenMsgNrOfRepetition" BO_ 484 3;
BA_ "GenMsgDelayTime" BO_ 484 100;
BA_ "GenMsgCycleTimeFast" BO_ 484 100;
BA_ "MessageTimeout" BO_ 485 0;
BA_ "GenMsgSendType" BO_ 485 8;
BA_ "GenMsgNrOfRepetition" BO_ 485 2;
BA_ "GenMsgDelayTime" BO_ 485 20;
BA_ "GenMsgCycleTimeFast" BO_ 485 20;
BA_ "MessageTimeout" BO_ 486 0;
BA_ "GenMsgSendType" BO_ 486 8;
BA_ "GenMsgNrOfRepetition" BO_ 486 1;
BA_ "MessageTimeout" BO_ 488 0;
BA_ "GenMsgSendType" BO_ 488 8;
BA_ "GenMsgNrOfRepetition" BO_ 488 1;
BA_ "MessageTimeout" BO_ 490 0;
BA_ "GenMsgSendType" BO_ 490 8;
BA_ "GenMsgNrOfRepetition" BO_ 490 1;
BA_ "MessageTimeout" BO_ 492 0;
BA_ "GenMsgSendType" BO_ 492 8;
BA_ "GenMsgNrOfRepetition" BO_ 492 3;
BA_ "GenMsgDelayTime" BO_ 492 100;
BA_ "MessageTimeout" BO_ 494 0;
BA_ "GenMsgSendType" BO_ 494 8;
BA_ "GenMsgNrOfRepetition" BO_ 494 3;
BA_ "GenMsgDelayTime" BO_ 494 100;
BA_ "GenMsgCycleTimeFast" BO_ 494 100;
BA_ "MessageTimeout" BO_ 497 0;
BA_ "GenMsgSendType" BO_ 497 8;
BA_ "MessageTimeout" BO_ 499 0;
BA_ "GenMsgSendType" BO_ 499 8;
BA_ "MessageTimeout" BO_ 500 0;
BA_ "GenMsgSendType" BO_ 500 8;
BA_ "MessageTimeout" BO_ 504 0;
BA_ "GenMsgSendType" BO_ 504 8;
BA_ "MessageTimeout" BO_ 505 0;
BA_ "GenMsgSendType" BO_ 505 8;
BA_ "GenSigTimeoutTime_HU_Mid_X451" SG_ 475 HuIcAlertFeatureTypeAck 0;
BA_ "GenSigTimeoutTime_HU_High_X451" SG_ 475 HuIcAlertFeatureTypeAck 0;
BA_ "GenSigTimeoutTime_HU_B" SG_ 475 HuIcAlertFeatureTypeAck 0;
BA_ "GenSigTimeoutTime_HU_A" SG_ 475 HuIcAlertFeatureTypeAck 0;
BA_ "GenSigTimeoutMsg_HU_Mid_X451" SG_ 475 HuIcAlertFeatureTypeAck 0;
BA_ "GenSigTimeoutMsg_HU_High_X451" SG_ 475 HuIcAlertFeatureTypeAck 0;
BA_ "GenSigTimeoutMsg_HU_B" SG_ 475 HuIcAlertFeatureTypeAck 0;
BA_ "GenSigTimeoutMsg_HU_A" SG_ 475 HuIcAlertFeatureTypeAck 0;
BA_ "GenSigSendType" SG_ 475 HuIcAlertFeatureTypeAck 1;
BA_ "GenSigTimeoutMsg_HU_High_X445" SG_ 475 HuIcAlertFeatureTypeAck 0;
BA_ "GenSigTimeoutMsg_HU_Mid_X445" SG_ 475 HuIcAlertFeatureTypeAck 0;
BA_ "GenSigTimeoutTime_HU_High_X445" SG_ 475 HuIcAlertFeatureTypeAck 0;
BA_ "GenSigTimeoutTime_HU_Mid_X445" SG_ 475 HuIcAlertFeatureTypeAck 0;
BA_ "GenSigTimeoutMsg_IVI" SG_ 475 HuIcAlertFeatureTypeAck 0;
BA_ "GenSigTimeoutTime_IVI" SG_ 475 HuIcAlertFeatureTypeAck 0;
BA_ "GenSigTimeoutTime_HU_Mid_X451" SG_ 475 HuIcAlertFeaturePresenceAck 0;
BA_ "GenSigTimeoutTime_HU_High_X451" SG_ 475 HuIcAlertFeaturePresenceAck 0;
BA_ "GenSigTimeoutTime_HU_B" SG_ 475 HuIcAlertFeaturePresenceAck 0;
BA_ "GenSigTimeoutTime_HU_A" SG_ 475 HuIcAlertFeaturePresenceAck 0;
BA_ "GenSigTimeoutMsg_HU_Mid_X451" SG_ 475 HuIcAlertFeaturePresenceAck 0;
BA_ "GenSigTimeoutMsg_HU_High_X451" SG_ 475 HuIcAlertFeaturePresenceAck 0;
BA_ "GenSigTimeoutMsg_HU_B" SG_ 475 HuIcAlertFeaturePresenceAck 0;
BA_ "GenSigTimeoutMsg_HU_A" SG_ 475 HuIcAlertFeaturePresenceAck 0;
BA_ "GenSigSendType" SG_ 475 HuIcAlertFeaturePresenceAck 1;
BA_ "GenSigTimeoutMsg_HU_High_X445" SG_ 475 HuIcAlertFeaturePresenceAck 0;
BA_ "GenSigTimeoutMsg_HU_Mid_X445" SG_ 475 HuIcAlertFeaturePresenceAck 0;
BA_ "GenSigTimeoutTime_HU_High_X445" SG_ 475 HuIcAlertFeaturePresenceAck 0;
BA_ "GenSigTimeoutTime_HU_Mid_X445" SG_ 475 HuIcAlertFeaturePresenceAck 0;
BA_ "GenSigTimeoutMsg_IVI" SG_ 475 HuIcAlertFeaturePresenceAck 0;
BA_ "GenSigTimeoutTime_IVI" SG_ 475 HuIcAlertFeaturePresenceAck 0;
BA_ "GenSigTimeoutTime_HU_Mid_X451" SG_ 476 HuIcVoiceAlertFeaturePresence 0;
BA_ "GenSigTimeoutTime_HU_High_X451" SG_ 476 HuIcVoiceAlertFeaturePresence 0;
BA_ "GenSigTimeoutTime_HU_B" SG_ 476 HuIcVoiceAlertFeaturePresence 0;
BA_ "GenSigTimeoutTime_HU_A" SG_ 476 HuIcVoiceAlertFeaturePresence 0;
BA_ "GenSigTimeoutMsg_HU_Mid_X451" SG_ 476 HuIcVoiceAlertFeaturePresence 0;
BA_ "GenSigTimeoutMsg_HU_High_X451" SG_ 476 HuIcVoiceAlertFeaturePresence 0;
BA_ "GenSigTimeoutMsg_HU_B" SG_ 476 HuIcVoiceAlertFeaturePresence 0;
BA_ "GenSigTimeoutMsg_HU_A" SG_ 476 HuIcVoiceAlertFeaturePresence 0;
BA_ "GenSigSendType" SG_ 476 HuIcVoiceAlertFeaturePresence 1;
BA_ "GenSigTimeoutMsg_HU_High_X445" SG_ 476 HuIcVoiceAlertFeaturePresence 0;
BA_ "GenSigTimeoutMsg_HU_Mid_X445" SG_ 476 HuIcVoiceAlertFeaturePresence 0;
BA_ "GenSigTimeoutTime_HU_High_X445" SG_ 476 HuIcVoiceAlertFeaturePresence 0;
BA_ "GenSigTimeoutTime_HU_Mid_X445" SG_ 476 HuIcVoiceAlertFeaturePresence 0;
BA_ "GenSigTimeoutMsg_IVI" SG_ 476 HuIcVoiceAlertFeaturePresence 0;
BA_ "GenSigTimeoutTime_IVI" SG_ 476 HuIcVoiceAlertFeaturePresence 0;
BA_ "GenSigTimeoutTime_HU_Mid_X451" SG_ 476 HuIcVoiceAlertSelectionState 0;
BA_ "GenSigTimeoutTime_HU_High_X451" SG_ 476 HuIcVoiceAlertSelectionState 0;
BA_ "GenSigTimeoutTime_HU_B" SG_ 476 HuIcVoiceAlertSelectionState 0;
BA_ "GenSigTimeoutTime_HU_A" SG_ 476 HuIcVoiceAlertSelectionState 0;
BA_ "GenSigTimeoutMsg_HU_Mid_X451" SG_ 476 HuIcVoiceAlertSelectionState 0;
BA_ "GenSigTimeoutMsg_HU_High_X451" SG_ 476 HuIcVoiceAlertSelectionState 0;
BA_ "GenSigTimeoutMsg_HU_B" SG_ 476 HuIcVoiceAlertSelectionState 0;
BA_ "GenSigTimeoutMsg_HU_A" SG_ 476 HuIcVoiceAlertSelectionState 0;
BA_ "GenSigSendType" SG_ 476 HuIcVoiceAlertSelectionState 1;
BA_ "GenSigTimeoutMsg_HU_High_X445" SG_ 476 HuIcVoiceAlertSelectionState 0;
BA_ "GenSigTimeoutMsg_HU_Mid_X445" SG_ 476 HuIcVoiceAlertSelectionState 0;
BA_ "GenSigTimeoutTime_HU_High_X445" SG_ 476 HuIcVoiceAlertSelectionState 0;
BA_ "GenSigTimeoutTime_HU_Mid_X445" SG_ 476 HuIcVoiceAlertSelectionState 0;
BA_ "GenSigTimeoutMsg_IVI" SG_ 476 HuIcVoiceAlertSelectionState 0;
BA_ "GenSigTimeoutTime_IVI" SG_ 476 HuIcVoiceAlertSelectionState 0;
BA_ "GenSigTimeoutTime_HU_Mid_X451" SG_ 476 HuIcTextAlertSelectionState 0;
BA_ "GenSigTimeoutTime_HU_High_X451" SG_ 476 HuIcTextAlertSelectionState 0;
BA_ "GenSigTimeoutTime_HU_B" SG_ 476 HuIcTextAlertSelectionState 0;
BA_ "GenSigTimeoutTime_HU_A" SG_ 476 HuIcTextAlertSelectionState 0;
BA_ "GenSigTimeoutMsg_HU_Mid_X451" SG_ 476 HuIcTextAlertSelectionState 0;
BA_ "GenSigTimeoutMsg_HU_High_X451" SG_ 476 HuIcTextAlertSelectionState 0;
BA_ "GenSigTimeoutMsg_HU_B" SG_ 476 HuIcTextAlertSelectionState 0;
BA_ "GenSigTimeoutMsg_HU_A" SG_ 476 HuIcTextAlertSelectionState 0;
BA_ "GenSigSendType" SG_ 476 HuIcTextAlertSelectionState 1;
BA_ "GenSigTimeoutMsg_HU_High_X445" SG_ 476 HuIcTextAlertSelectionState 0;
BA_ "GenSigTimeoutMsg_HU_Mid_X445" SG_ 476 HuIcTextAlertSelectionState 0;
BA_ "GenSigTimeoutTime_HU_High_X445" SG_ 476 HuIcTextAlertSelectionState 0;
BA_ "GenSigTimeoutTime_HU_Mid_X445" SG_ 476 HuIcTextAlertSelectionState 0;
BA_ "GenSigTimeoutMsg_IVI" SG_ 476 HuIcTextAlertSelectionState 0;
BA_ "GenSigTimeoutTime_IVI" SG_ 476 HuIcTextAlertSelectionState 0;
BA_ "GenSigTimeoutTime_HU_Mid_X451" SG_ 477 IcHuVoiceAlertSelectionState 0;
BA_ "GenSigTimeoutTime_HU_High_X451" SG_ 477 IcHuVoiceAlertSelectionState 0;
BA_ "GenSigTimeoutTime_HU_B" SG_ 477 IcHuVoiceAlertSelectionState 0;
BA_ "GenSigTimeoutTime_HU_A" SG_ 477 IcHuVoiceAlertSelectionState 0;
BA_ "GenSigTimeoutMsg_HU_Mid_X451" SG_ 477 IcHuVoiceAlertSelectionState 0;
BA_ "GenSigTimeoutMsg_HU_High_X451" SG_ 477 IcHuVoiceAlertSelectionState 0;
BA_ "GenSigTimeoutMsg_HU_B" SG_ 477 IcHuVoiceAlertSelectionState 0;
BA_ "GenSigTimeoutMsg_HU_A" SG_ 477 IcHuVoiceAlertSelectionState 0;
BA_ "GenSigSendType" SG_ 477 IcHuVoiceAlertSelectionState 1;
BA_ "GenSigTimeoutMsg_HU_High_X445" SG_ 477 IcHuVoiceAlertSelectionState 0;
BA_ "GenSigTimeoutMsg_HU_Mid_X445" SG_ 477 IcHuVoiceAlertSelectionState 0;
BA_ "GenSigTimeoutTime_HU_High_X445" SG_ 477 IcHuVoiceAlertSelectionState 0;
BA_ "GenSigTimeoutTime_HU_Mid_X445" SG_ 477 IcHuVoiceAlertSelectionState 0;
BA_ "GenSigTimeoutMsg_IVI" SG_ 477 IcHuVoiceAlertSelectionState 0;
BA_ "GenSigTimeoutTime_IVI" SG_ 477 IcHuVoiceAlertSelectionState 0;
BA_ "GenSigTimeoutTime_HU_Mid_X451" SG_ 477 IcHuAlertFeatureType 0;
BA_ "GenSigTimeoutTime_HU_High_X451" SG_ 477 IcHuAlertFeatureType 0;
BA_ "GenSigTimeoutTime_HU_B" SG_ 477 IcHuAlertFeatureType 0;
BA_ "GenSigTimeoutTime_HU_A" SG_ 477 IcHuAlertFeatureType 0;
BA_ "GenSigTimeoutMsg_HU_Mid_X451" SG_ 477 IcHuAlertFeatureType 0;
BA_ "GenSigTimeoutMsg_HU_High_X451" SG_ 477 IcHuAlertFeatureType 0;
BA_ "GenSigTimeoutMsg_HU_B" SG_ 477 IcHuAlertFeatureType 0;
BA_ "GenSigTimeoutMsg_HU_A" SG_ 477 IcHuAlertFeatureType 0;
BA_ "GenSigSendType" SG_ 477 IcHuAlertFeatureType 1;
BA_ "GenSigTimeoutMsg_HU_High_X445" SG_ 477 IcHuAlertFeatureType 0;
BA_ "GenSigTimeoutMsg_HU_Mid_X445" SG_ 477 IcHuAlertFeatureType 0;
BA_ "GenSigTimeoutTime_HU_High_X445" SG_ 477 IcHuAlertFeatureType 0;
BA_ "GenSigTimeoutTime_HU_Mid_X445" SG_ 477 IcHuAlertFeatureType 0;
BA_ "GenSigTimeoutMsg_IVI" SG_ 477 IcHuAlertFeatureType 0;
BA_ "GenSigTimeoutTime_IVI" SG_ 477 IcHuAlertFeatureType 0;
BA_ "GenSigTimeoutTime_HU_Mid_X451" SG_ 477 IcHuAlertFeaturePresence 0;
BA_ "GenSigTimeoutTime_HU_High_X451" SG_ 477 IcHuAlertFeaturePresence 0;
BA_ "GenSigTimeoutTime_HU_B" SG_ 477 IcHuAlertFeaturePresence 0;
BA_ "GenSigTimeoutTime_HU_A" SG_ 477 IcHuAlertFeaturePresence 0;
BA_ "GenSigTimeoutMsg_HU_Mid_X451" SG_ 477 IcHuAlertFeaturePresence 0;
BA_ "GenSigTimeoutMsg_HU_High_X451" SG_ 477 IcHuAlertFeaturePresence 0;
BA_ "GenSigTimeoutMsg_HU_B" SG_ 477 IcHuAlertFeaturePresence 0;
BA_ "GenSigTimeoutMsg_HU_A" SG_ 477 IcHuAlertFeaturePresence 0;
BA_ "GenSigSendType" SG_ 477 IcHuAlertFeaturePresence 1;
BA_ "GenSigTimeoutMsg_HU_High_X445" SG_ 477 IcHuAlertFeaturePresence 0;
BA_ "GenSigTimeoutMsg_HU_Mid_X445" SG_ 477 IcHuAlertFeaturePresence 0;
BA_ "GenSigTimeoutTime_HU_High_X445" SG_ 477 IcHuAlertFeaturePresence 0;
BA_ "GenSigTimeoutTime_HU_Mid_X445" SG_ 477 IcHuAlertFeaturePresence 0;
BA_ "GenSigTimeoutMsg_IVI" SG_ 477 IcHuAlertFeaturePresence 0;
BA_ "GenSigTimeoutTime_IVI" SG_ 477 IcHuAlertFeaturePresence 0;
BA_ "GenSigTimeoutTime_HU_Mid_X451" SG_ 478 IcHuVoiceAlertFeaturePresenceAck 0;
BA_ "GenSigTimeoutTime_HU_High_X451" SG_ 478 IcHuVoiceAlertFeaturePresenceAck 0;
BA_ "GenSigTimeoutTime_HU_B" SG_ 478 IcHuVoiceAlertFeaturePresenceAck 0;
BA_ "GenSigTimeoutTime_HU_A" SG_ 478 IcHuVoiceAlertFeaturePresenceAck 0;
BA_ "GenSigTimeoutMsg_HU_Mid_X451" SG_ 478 IcHuVoiceAlertFeaturePresenceAck 0;
BA_ "GenSigTimeoutMsg_HU_High_X451" SG_ 478 IcHuVoiceAlertFeaturePresenceAck 0;
BA_ "GenSigTimeoutMsg_HU_B" SG_ 478 IcHuVoiceAlertFeaturePresenceAck 0;
BA_ "GenSigTimeoutMsg_HU_A" SG_ 478 IcHuVoiceAlertFeaturePresenceAck 0;
BA_ "GenSigSendType" SG_ 478 IcHuVoiceAlertFeaturePresenceAck 1;
BA_ "GenSigTimeoutMsg_HU_High_X445" SG_ 478 IcHuVoiceAlertFeaturePresenceAck 0;
BA_ "GenSigTimeoutMsg_HU_Mid_X445" SG_ 478 IcHuVoiceAlertFeaturePresenceAck 0;
BA_ "GenSigTimeoutTime_HU_High_X445" SG_ 478 IcHuVoiceAlertFeaturePresenceAck 0;
BA_ "GenSigTimeoutTime_HU_Mid_X445" SG_ 478 IcHuVoiceAlertFeaturePresenceAck 0;
BA_ "GenSigTimeoutMsg_IVI" SG_ 478 IcHuVoiceAlertFeaturePresenceAck 0;
BA_ "GenSigTimeoutTime_IVI" SG_ 478 IcHuVoiceAlertFeaturePresenceAck 0;
BA_ "GenSigTimeoutTime_HU_Mid_X451" SG_ 478 IcHuVoiceAlertSelectionStateAck 0;
BA_ "GenSigTimeoutTime_HU_High_X451" SG_ 478 IcHuVoiceAlertSelectionStateAck 0;
BA_ "GenSigTimeoutTime_HU_B" SG_ 478 IcHuVoiceAlertSelectionStateAck 0;
BA_ "GenSigTimeoutTime_HU_A" SG_ 478 IcHuVoiceAlertSelectionStateAck 0;
BA_ "GenSigTimeoutMsg_HU_Mid_X451" SG_ 478 IcHuVoiceAlertSelectionStateAck 0;
BA_ "GenSigTimeoutMsg_HU_High_X451" SG_ 478 IcHuVoiceAlertSelectionStateAck 0;
BA_ "GenSigTimeoutMsg_HU_B" SG_ 478 IcHuVoiceAlertSelectionStateAck 0;
BA_ "GenSigTimeoutMsg_HU_A" SG_ 478 IcHuVoiceAlertSelectionStateAck 0;
BA_ "GenSigSendType" SG_ 478 IcHuVoiceAlertSelectionStateAck 1;
BA_ "GenSigTimeoutMsg_HU_High_X445" SG_ 478 IcHuVoiceAlertSelectionStateAck 0;
BA_ "GenSigTimeoutMsg_HU_Mid_X445" SG_ 478 IcHuVoiceAlertSelectionStateAck 0;
BA_ "GenSigTimeoutTime_HU_High_X445" SG_ 478 IcHuVoiceAlertSelectionStateAck 0;
BA_ "GenSigTimeoutTime_HU_Mid_X445" SG_ 478 IcHuVoiceAlertSelectionStateAck 0;
BA_ "GenSigTimeoutMsg_IVI" SG_ 478 IcHuVoiceAlertSelectionStateAck 0;
BA_ "GenSigTimeoutTime_IVI" SG_ 478 IcHuVoiceAlertSelectionStateAck 0;
BA_ "GenSigTimeoutTime_HU_Mid_X451" SG_ 478 IcHuTextAlertSelectionStateAck 0;
BA_ "GenSigTimeoutTime_HU_High_X451" SG_ 478 IcHuTextAlertSelectionStateAck 0;
BA_ "GenSigTimeoutTime_HU_B" SG_ 478 IcHuTextAlertSelectionStateAck 0;
BA_ "GenSigTimeoutTime_HU_A" SG_ 478 IcHuTextAlertSelectionStateAck 0;
BA_ "GenSigTimeoutMsg_HU_Mid_X451" SG_ 478 IcHuTextAlertSelectionStateAck 0;
BA_ "GenSigTimeoutMsg_HU_High_X451" SG_ 478 IcHuTextAlertSelectionStateAck 0;
BA_ "GenSigTimeoutMsg_HU_B" SG_ 478 IcHuTextAlertSelectionStateAck 0;
BA_ "GenSigTimeoutMsg_HU_A" SG_ 478 IcHuTextAlertSelectionStateAck 0;
BA_ "GenSigSendType" SG_ 478 IcHuTextAlertSelectionStateAck 1;
BA_ "GenSigTimeoutMsg_HU_High_X445" SG_ 478 IcHuTextAlertSelectionStateAck 0;
BA_ "GenSigTimeoutMsg_HU_Mid_X445" SG_ 478 IcHuTextAlertSelectionStateAck 0;
BA_ "GenSigTimeoutTime_HU_High_X445" SG_ 478 IcHuTextAlertSelectionStateAck 0;
BA_ "GenSigTimeoutTime_HU_Mid_X445" SG_ 478 IcHuTextAlertSelectionStateAck 0;
BA_ "GenSigTimeoutMsg_IVI" SG_ 478 IcHuTextAlertSelectionStateAck 0;
BA_ "GenSigTimeoutTime_IVI" SG_ 478 IcHuTextAlertSelectionStateAck 0;
BA_ "GenSigTimeoutTime_HU_Mid_X451" SG_ 479 IcHuDriveproConfigAck 0;
BA_ "GenSigTimeoutTime_HU_High_X451" SG_ 479 IcHuDriveproConfigAck 0;
BA_ "GenSigTimeoutTime_HU_B" SG_ 479 IcHuDriveproConfigAck 0;
BA_ "GenSigTimeoutTime_HU_A" SG_ 479 IcHuDriveproConfigAck 0;
BA_ "GenSigTimeoutMsg_HU_Mid_X451" SG_ 479 IcHuDriveproConfigAck 0;
BA_ "GenSigTimeoutMsg_HU_High_X451" SG_ 479 IcHuDriveproConfigAck 0;
BA_ "GenSigTimeoutMsg_HU_B" SG_ 479 IcHuDriveproConfigAck 0;
BA_ "GenSigTimeoutMsg_HU_A" SG_ 479 IcHuDriveproConfigAck 0;
BA_ "GenSigSendType" SG_ 479 IcHuDriveproConfigAck 1;
BA_ "GenSigTimeoutMsg_HU_High_X445" SG_ 479 IcHuDriveproConfigAck 0;
BA_ "GenSigTimeoutMsg_HU_Mid_X445" SG_ 479 IcHuDriveproConfigAck 0;
BA_ "GenSigTimeoutTime_HU_High_X445" SG_ 479 IcHuDriveproConfigAck 0;
BA_ "GenSigTimeoutTime_HU_Mid_X445" SG_ 479 IcHuDriveproConfigAck 0;
BA_ "GenSigTimeoutMsg_IVI" SG_ 479 IcHuDriveproConfigAck 0;
BA_ "GenSigTimeoutTime_IVI" SG_ 479 IcHuDriveproConfigAck 0;
BA_ "GenSigTimeoutTime_HU_Mid_X451" SG_ 479 IcHuDriveProConfigAckEventStatus 0;
BA_ "GenSigTimeoutTime_HU_High_X451" SG_ 479 IcHuDriveProConfigAckEventStatus 0;
BA_ "GenSigTimeoutTime_HU_B" SG_ 479 IcHuDriveProConfigAckEventStatus 0;
BA_ "GenSigTimeoutTime_HU_A" SG_ 479 IcHuDriveProConfigAckEventStatus 0;
BA_ "GenSigTimeoutMsg_HU_Mid_X451" SG_ 479 IcHuDriveProConfigAckEventStatus 0;
BA_ "GenSigTimeoutMsg_HU_High_X451" SG_ 479 IcHuDriveProConfigAckEventStatus 0;
BA_ "GenSigTimeoutMsg_HU_B" SG_ 479 IcHuDriveProConfigAckEventStatus 0;
BA_ "GenSigTimeoutMsg_HU_A" SG_ 479 IcHuDriveProConfigAckEventStatus 0;
BA_ "GenSigSendType" SG_ 479 IcHuDriveProConfigAckEventStatus 1;
BA_ "GenSigTimeoutMsg_HU_High_X445" SG_ 479 IcHuDriveProConfigAckEventStatus 0;
BA_ "GenSigTimeoutMsg_HU_Mid_X445" SG_ 479 IcHuDriveProConfigAckEventStatus 0;
BA_ "GenSigTimeoutTime_HU_High_X445" SG_ 479 IcHuDriveProConfigAckEventStatus 0;
BA_ "GenSigTimeoutTime_HU_Mid_X445" SG_ 479 IcHuDriveProConfigAckEventStatus 0;
BA_ "GenSigTimeoutMsg_IVI" SG_ 479 IcHuDriveProConfigAckEventStatus 0;
BA_ "GenSigTimeoutTime_IVI" SG_ 479 IcHuDriveProConfigAckEventStatus 0;
BA_ "GenSigTimeoutTime_HU_Mid_X451" SG_ 479 IcHuTripAReset 0;
BA_ "GenSigTimeoutTime_HU_High_X451" SG_ 479 IcHuTripAReset 0;
BA_ "GenSigTimeoutTime_HU_B" SG_ 479 IcHuTripAReset 0;
BA_ "GenSigTimeoutTime_HU_A" SG_ 479 IcHuTripAReset 0;
BA_ "GenSigTimeoutMsg_HU_Mid_X451" SG_ 479 IcHuTripAReset 0;
BA_ "GenSigTimeoutMsg_HU_High_X451" SG_ 479 IcHuTripAReset 0;
BA_ "GenSigTimeoutMsg_HU_B" SG_ 479 IcHuTripAReset 0;
BA_ "GenSigTimeoutMsg_HU_A" SG_ 479 IcHuTripAReset 0;
BA_ "GenSigSendType" SG_ 479 IcHuTripAReset 1;
BA_ "GenSigTimeoutMsg_HU_High_X445" SG_ 479 IcHuTripAReset 0;
BA_ "GenSigTimeoutMsg_HU_Mid_X445" SG_ 479 IcHuTripAReset 0;
BA_ "GenSigTimeoutTime_HU_High_X445" SG_ 479 IcHuTripAReset 0;
BA_ "GenSigTimeoutTime_HU_Mid_X445" SG_ 479 IcHuTripAReset 0;
BA_ "GenSigTimeoutMsg_IVI" SG_ 479 IcHuTripAReset 0;
BA_ "GenSigTimeoutTime_IVI" SG_ 479 IcHuTripAReset 0;
BA_ "GenSigTimeoutTime_HU_Mid_X451" SG_ 479 IcHuTripAResetAck 0;
BA_ "GenSigTimeoutTime_HU_High_X451" SG_ 479 IcHuTripAResetAck 0;
BA_ "GenSigTimeoutTime_HU_B" SG_ 479 IcHuTripAResetAck 0;
BA_ "GenSigTimeoutTime_HU_A" SG_ 479 IcHuTripAResetAck 0;
BA_ "GenSigTimeoutMsg_HU_Mid_X451" SG_ 479 IcHuTripAResetAck 0;
BA_ "GenSigTimeoutMsg_HU_High_X451" SG_ 479 IcHuTripAResetAck 0;
BA_ "GenSigTimeoutMsg_HU_B" SG_ 479 IcHuTripAResetAck 0;
BA_ "GenSigTimeoutMsg_HU_A" SG_ 479 IcHuTripAResetAck 0;
BA_ "GenSigSendType" SG_ 479 IcHuTripAResetAck 1;
BA_ "GenSigTimeoutMsg_HU_High_X445" SG_ 479 IcHuTripAResetAck 0;
BA_ "GenSigTimeoutMsg_HU_Mid_X445" SG_ 479 IcHuTripAResetAck 0;
BA_ "GenSigTimeoutTime_HU_High_X445" SG_ 479 IcHuTripAResetAck 0;
BA_ "GenSigTimeoutTime_HU_Mid_X445" SG_ 479 IcHuTripAResetAck 0;
BA_ "GenSigTimeoutMsg_IVI" SG_ 479 IcHuTripAResetAck 0;
BA_ "GenSigTimeoutTime_IVI" SG_ 479 IcHuTripAResetAck 0;
BA_ "GenSigTimeoutTime_HU_Mid_X451" SG_ 479 IcHuTripBReset 0;
BA_ "GenSigTimeoutTime_HU_High_X451" SG_ 479 IcHuTripBReset 0;
BA_ "GenSigTimeoutTime_HU_B" SG_ 479 IcHuTripBReset 0;
BA_ "GenSigTimeoutTime_HU_A" SG_ 479 IcHuTripBReset 0;
BA_ "GenSigTimeoutMsg_HU_Mid_X451" SG_ 479 IcHuTripBReset 0;
BA_ "GenSigTimeoutMsg_HU_High_X451" SG_ 479 IcHuTripBReset 0;
BA_ "GenSigTimeoutMsg_HU_B" SG_ 479 IcHuTripBReset 0;
BA_ "GenSigTimeoutMsg_HU_A" SG_ 479 IcHuTripBReset 0;
BA_ "GenSigSendType" SG_ 479 IcHuTripBReset 1;
BA_ "GenSigTimeoutMsg_HU_High_X445" SG_ 479 IcHuTripBReset 0;
BA_ "GenSigTimeoutMsg_HU_Mid_X445" SG_ 479 IcHuTripBReset 0;
BA_ "GenSigTimeoutTime_HU_High_X445" SG_ 479 IcHuTripBReset 0;
BA_ "GenSigTimeoutTime_HU_Mid_X445" SG_ 479 IcHuTripBReset 0;
BA_ "GenSigTimeoutMsg_IVI" SG_ 479 IcHuTripBReset 0;
BA_ "GenSigTimeoutTime_IVI" SG_ 479 IcHuTripBReset 0;
BA_ "GenSigTimeoutTime_HU_Mid_X451" SG_ 479 IcHuTripBResetAck 0;
BA_ "GenSigTimeoutTime_HU_High_X451" SG_ 479 IcHuTripBResetAck 0;
BA_ "GenSigTimeoutTime_HU_B" SG_ 479 IcHuTripBResetAck 0;
BA_ "GenSigTimeoutTime_HU_A" SG_ 479 IcHuTripBResetAck 0;
BA_ "GenSigTimeoutMsg_HU_Mid_X451" SG_ 479 IcHuTripBResetAck 0;
BA_ "GenSigTimeoutMsg_HU_High_X451" SG_ 479 IcHuTripBResetAck 0;
BA_ "GenSigTimeoutMsg_HU_B" SG_ 479 IcHuTripBResetAck 0;
BA_ "GenSigTimeoutMsg_HU_A" SG_ 479 IcHuTripBResetAck 0;
BA_ "GenSigSendType" SG_ 479 IcHuTripBResetAck 1;
BA_ "GenSigTimeoutMsg_HU_High_X445" SG_ 479 IcHuTripBResetAck 0;
BA_ "GenSigTimeoutMsg_HU_Mid_X445" SG_ 479 IcHuTripBResetAck 0;
BA_ "GenSigTimeoutTime_HU_High_X445" SG_ 479 IcHuTripBResetAck 0;
BA_ "GenSigTimeoutTime_HU_Mid_X445" SG_ 479 IcHuTripBResetAck 0;
BA_ "GenSigTimeoutMsg_IVI" SG_ 479 IcHuTripBResetAck 0;
BA_ "GenSigTimeoutTime_IVI" SG_ 479 IcHuTripBResetAck 0;
BA_ "GenSigTimeoutTime_HU_Mid_X451" SG_ 479 IcHuResetAllAck 0;
BA_ "GenSigTimeoutTime_HU_High_X451" SG_ 479 IcHuResetAllAck 0;
BA_ "GenSigTimeoutTime_HU_B" SG_ 479 IcHuResetAllAck 0;
BA_ "GenSigTimeoutTime_HU_A" SG_ 479 IcHuResetAllAck 0;
BA_ "GenSigTimeoutMsg_HU_Mid_X451" SG_ 479 IcHuResetAllAck 0;
BA_ "GenSigTimeoutMsg_HU_High_X451" SG_ 479 IcHuResetAllAck 0;
BA_ "GenSigTimeoutMsg_HU_B" SG_ 479 IcHuResetAllAck 0;
BA_ "GenSigTimeoutMsg_HU_A" SG_ 479 IcHuResetAllAck 0;
BA_ "GenSigSendType" SG_ 479 IcHuResetAllAck 1;
BA_ "GenSigTimeoutMsg_HU_High_X445" SG_ 479 IcHuResetAllAck 0;
BA_ "GenSigTimeoutMsg_HU_Mid_X445" SG_ 479 IcHuResetAllAck 0;
BA_ "GenSigTimeoutTime_HU_High_X445" SG_ 479 IcHuResetAllAck 0;
BA_ "GenSigTimeoutTime_HU_Mid_X445" SG_ 479 IcHuResetAllAck 0;
BA_ "GenSigTimeoutMsg_IVI" SG_ 479 IcHuResetAllAck 0;
BA_ "GenSigTimeoutTime_IVI" SG_ 479 IcHuResetAllAck 0;
BA_ "GenSigTimeoutTime_HU_Mid_X451" SG_ 479 IcHuTripResetAckEventStatus 0;
BA_ "GenSigTimeoutTime_HU_High_X451" SG_ 479 IcHuTripResetAckEventStatus 0;
BA_ "GenSigTimeoutTime_HU_B" SG_ 479 IcHuTripResetAckEventStatus 0;
BA_ "GenSigTimeoutTime_HU_A" SG_ 479 IcHuTripResetAckEventStatus 0;
BA_ "GenSigTimeoutMsg_HU_Mid_X451" SG_ 479 IcHuTripResetAckEventStatus 0;
BA_ "GenSigTimeoutMsg_HU_High_X451" SG_ 479 IcHuTripResetAckEventStatus 0;
BA_ "GenSigTimeoutMsg_HU_B" SG_ 479 IcHuTripResetAckEventStatus 0;
BA_ "GenSigTimeoutMsg_HU_A" SG_ 479 IcHuTripResetAckEventStatus 0;
BA_ "GenSigSendType" SG_ 479 IcHuTripResetAckEventStatus 1;
BA_ "GenSigTimeoutMsg_HU_High_X445" SG_ 479 IcHuTripResetAckEventStatus 0;
BA_ "GenSigTimeoutMsg_HU_Mid_X445" SG_ 479 IcHuTripResetAckEventStatus 0;
BA_ "GenSigTimeoutTime_HU_High_X445" SG_ 479 IcHuTripResetAckEventStatus 0;
BA_ "GenSigTimeoutTime_HU_Mid_X445" SG_ 479 IcHuTripResetAckEventStatus 0;
BA_ "GenSigTimeoutMsg_IVI" SG_ 479 IcHuTripResetAckEventStatus 0;
BA_ "GenSigTimeoutTime_IVI" SG_ 479 IcHuTripResetAckEventStatus 0;
BA_ "GenSigTimeoutTime_HU_Mid_X451" SG_ 479 IcHuTripResetEventStatus 0;
BA_ "GenSigTimeoutTime_HU_High_X451" SG_ 479 IcHuTripResetEventStatus 0;
BA_ "GenSigTimeoutTime_HU_B" SG_ 479 IcHuTripResetEventStatus 0;
BA_ "GenSigTimeoutTime_HU_A" SG_ 479 IcHuTripResetEventStatus 0;
BA_ "GenSigTimeoutMsg_HU_Mid_X451" SG_ 479 IcHuTripResetEventStatus 0;
BA_ "GenSigTimeoutMsg_HU_High_X451" SG_ 479 IcHuTripResetEventStatus 0;
BA_ "GenSigTimeoutMsg_HU_B" SG_ 479 IcHuTripResetEventStatus 0;
BA_ "GenSigTimeoutMsg_HU_A" SG_ 479 IcHuTripResetEventStatus 0;
BA_ "GenSigSendType" SG_ 479 IcHuTripResetEventStatus 1;
BA_ "GenSigTimeoutMsg_HU_High_X445" SG_ 479 IcHuTripResetEventStatus 0;
BA_ "GenSigTimeoutMsg_HU_Mid_X445" SG_ 479 IcHuTripResetEventStatus 0;
BA_ "GenSigTimeoutTime_HU_High_X445" SG_ 479 IcHuTripResetEventStatus 0;
BA_ "GenSigTimeoutTime_HU_Mid_X445" SG_ 479 IcHuTripResetEventStatus 0;
BA_ "GenSigTimeoutMsg_IVI" SG_ 479 IcHuTripResetEventStatus 0;
BA_ "GenSigTimeoutTime_IVI" SG_ 479 IcHuTripResetEventStatus 0;
BA_ "GenSigTimeoutTime_HU_Mid_X451" SG_ 479 IcHuOverallTripResetAck 0;
BA_ "GenSigTimeoutTime_HU_High_X451" SG_ 479 IcHuOverallTripResetAck 0;
BA_ "GenSigTimeoutTime_HU_B" SG_ 479 IcHuOverallTripResetAck 0;
BA_ "GenSigTimeoutTime_HU_A" SG_ 479 IcHuOverallTripResetAck 0;
BA_ "GenSigTimeoutMsg_HU_Mid_X451" SG_ 479 IcHuOverallTripResetAck 0;
BA_ "GenSigTimeoutMsg_HU_High_X451" SG_ 479 IcHuOverallTripResetAck 0;
BA_ "GenSigTimeoutMsg_HU_B" SG_ 479 IcHuOverallTripResetAck 0;
BA_ "GenSigTimeoutMsg_HU_A" SG_ 479 IcHuOverallTripResetAck 0;
BA_ "GenSigSendType" SG_ 479 IcHuOverallTripResetAck 1;
BA_ "GenSigTimeoutMsg_HU_High_X445" SG_ 479 IcHuOverallTripResetAck 0;
BA_ "GenSigTimeoutMsg_HU_Mid_X445" SG_ 479 IcHuOverallTripResetAck 0;
BA_ "GenSigTimeoutTime_HU_High_X445" SG_ 479 IcHuOverallTripResetAck 0;
BA_ "GenSigTimeoutTime_HU_Mid_X445" SG_ 479 IcHuOverallTripResetAck 0;
BA_ "GenSigTimeoutMsg_IVI" SG_ 479 IcHuOverallTripResetAck 0;
BA_ "GenSigTimeoutTime_IVI" SG_ 479 IcHuOverallTripResetAck 0;
BA_ "GenSigTimeoutTime_HU_Mid_X451" SG_ 479 IcHuOverallTripReset 0;
BA_ "GenSigTimeoutTime_HU_High_X451" SG_ 479 IcHuOverallTripReset 0;
BA_ "GenSigTimeoutTime_HU_B" SG_ 479 IcHuOverallTripReset 0;
BA_ "GenSigTimeoutTime_HU_A" SG_ 479 IcHuOverallTripReset 0;
BA_ "GenSigTimeoutMsg_HU_Mid_X451" SG_ 479 IcHuOverallTripReset 0;
BA_ "GenSigTimeoutMsg_HU_High_X451" SG_ 479 IcHuOverallTripReset 0;
BA_ "GenSigTimeoutMsg_HU_B" SG_ 479 IcHuOverallTripReset 0;
BA_ "GenSigTimeoutMsg_HU_A" SG_ 479 IcHuOverallTripReset 0;
BA_ "GenSigSendType" SG_ 479 IcHuOverallTripReset 1;
BA_ "GenSigTimeoutMsg_HU_High_X445" SG_ 479 IcHuOverallTripReset 0;
BA_ "GenSigTimeoutMsg_HU_Mid_X445" SG_ 479 IcHuOverallTripReset 0;
BA_ "GenSigTimeoutTime_HU_High_X445" SG_ 479 IcHuOverallTripReset 0;
BA_ "GenSigTimeoutTime_HU_Mid_X445" SG_ 479 IcHuOverallTripReset 0;
BA_ "GenSigTimeoutMsg_IVI" SG_ 479 IcHuOverallTripReset 0;
BA_ "GenSigTimeoutTime_IVI" SG_ 479 IcHuOverallTripReset 0;
BA_ "GenSigTimeoutTime_HU_Mid_X451" SG_ 479 IcHuResetAll 0;
BA_ "GenSigTimeoutTime_HU_High_X451" SG_ 479 IcHuResetAll 0;
BA_ "GenSigTimeoutTime_HU_B" SG_ 479 IcHuResetAll 0;
BA_ "GenSigTimeoutTime_HU_A" SG_ 479 IcHuResetAll 0;
BA_ "GenSigTimeoutMsg_HU_Mid_X451" SG_ 479 IcHuResetAll 0;
BA_ "GenSigTimeoutMsg_HU_High_X451" SG_ 479 IcHuResetAll 0;
BA_ "GenSigTimeoutMsg_HU_B" SG_ 479 IcHuResetAll 0;
BA_ "GenSigTimeoutMsg_HU_A" SG_ 479 IcHuResetAll 0;
BA_ "GenSigSendType" SG_ 479 IcHuResetAll 1;
BA_ "GenSigTimeoutMsg_HU_High_X445" SG_ 479 IcHuResetAll 0;
BA_ "GenSigTimeoutMsg_HU_Mid_X445" SG_ 479 IcHuResetAll 0;
BA_ "GenSigTimeoutTime_HU_High_X445" SG_ 479 IcHuResetAll 0;
BA_ "GenSigTimeoutTime_HU_Mid_X445" SG_ 479 IcHuResetAll 0;
BA_ "GenSigTimeoutMsg_IVI" SG_ 479 IcHuResetAll 0;
BA_ "GenSigTimeoutTime_IVI" SG_ 479 IcHuResetAll 0;
BA_ "GenSigTimeoutTime_HU_B" SG_ 480 UIDAuthState 0;
BA_ "GenSigTimeoutTime_HU_A" SG_ 480 UIDAuthState 0;
BA_ "GenSigTimeoutMsg_HU_B" SG_ 480 UIDAuthState 0;
BA_ "GenSigTimeoutMsg_HU_A" SG_ 480 UIDAuthState 0;
BA_ "GenSigSendType" SG_ 480 UIDAuthState 1;
BA_ "GenSigTimeoutTime_HU_B" SG_ 484 UnLockTailgageCommand 0;
BA_ "GenSigTimeoutTime_HU_A" SG_ 484 UnLockTailgageCommand 0;
BA_ "GenSigTimeoutMsg_HU_B" SG_ 484 UnLockTailgageCommand 0;
BA_ "GenSigTimeoutMsg_HU_A" SG_ 484 UnLockTailgageCommand 0;
BA_ "GenSigSendType" SG_ 484 UnLockTailgageCommand 2;
BA_ "GenSigTimeoutTime_HU_B" SG_ 484 UnLockAllDoorCommand 0;
BA_ "GenSigTimeoutTime_HU_A" SG_ 484 UnLockAllDoorCommand 0;
BA_ "GenSigTimeoutMsg_HU_B" SG_ 484 UnLockAllDoorCommand 0;
BA_ "GenSigTimeoutMsg_HU_A" SG_ 484 UnLockAllDoorCommand 0;
BA_ "GenSigSendType" SG_ 484 UnLockAllDoorCommand 2;
BA_ "GenSigTimeoutTime_HU_B" SG_ 484 UnLockDrDoorCommandStatus 0;
BA_ "GenSigTimeoutTime_HU_A" SG_ 484 UnLockDrDoorCommandStatus 0;
BA_ "GenSigTimeoutMsg_HU_B" SG_ 484 UnLockDrDoorCommandStatus 0;
BA_ "GenSigTimeoutMsg_HU_A" SG_ 484 UnLockDrDoorCommandStatus 0;
BA_ "GenSigSendType" SG_ 484 UnLockDrDoorCommandStatus 2;
BA_ "GenSigTimeoutTime_HU_B" SG_ 484 UnLockDrDoorCommand 0;
BA_ "GenSigTimeoutTime_HU_A" SG_ 484 UnLockDrDoorCommand 0;
BA_ "GenSigTimeoutMsg_HU_B" SG_ 484 UnLockDrDoorCommand 0;
BA_ "GenSigTimeoutMsg_HU_A" SG_ 484 UnLockDrDoorCommand 0;
BA_ "GenSigSendType" SG_ 484 UnLockDrDoorCommand 2;
BA_ "GenSigTimeoutTime_HU_B" SG_ 484 VehicleLockCommandStatus 0;
BA_ "GenSigTimeoutTime_HU_A" SG_ 484 VehicleLockCommandStatus 0;
BA_ "GenSigTimeoutMsg_HU_B" SG_ 484 VehicleLockCommandStatus 0;
BA_ "GenSigTimeoutMsg_HU_A" SG_ 484 VehicleLockCommandStatus 0;
BA_ "GenSigSendType" SG_ 484 VehicleLockCommandStatus 2;
BA_ "GenSigTimeoutTime_HU_B" SG_ 484 VehicleLockCommand 0;
BA_ "GenSigTimeoutTime_HU_A" SG_ 484 VehicleLockCommand 0;
BA_ "GenSigTimeoutMsg_HU_B" SG_ 484 VehicleLockCommand 0;
BA_ "GenSigTimeoutMsg_HU_A" SG_ 484 VehicleLockCommand 0;
BA_ "GenSigSendType" SG_ 484 VehicleLockCommand 2;
BA_ "GenSigTimeoutTime_HU_B" SG_ 484 ForcePanicCommand 0;
BA_ "GenSigTimeoutTime_HU_A" SG_ 484 ForcePanicCommand 0;
BA_ "GenSigTimeoutMsg_HU_B" SG_ 484 ForcePanicCommand 0;
BA_ "GenSigTimeoutMsg_HU_A" SG_ 484 ForcePanicCommand 0;
BA_ "GenSigSendType" SG_ 484 ForcePanicCommand 2;
BA_ "GenSigTimeoutTime_HU_B" SG_ 484 ApproachLighCommandStatus 0;
BA_ "GenSigTimeoutTime_HU_A" SG_ 484 ApproachLighCommandStatus 0;
BA_ "GenSigTimeoutMsg_HU_B" SG_ 484 ApproachLighCommandStatus 0;
BA_ "GenSigTimeoutMsg_HU_A" SG_ 484 ApproachLighCommandStatus 0;
BA_ "GenSigSendType" SG_ 484 ApproachLighCommandStatus 2;
BA_ "GenSigTimeoutTime_HU_B" SG_ 484 ApproachLighCommand 0;
BA_ "GenSigTimeoutTime_HU_A" SG_ 484 ApproachLighCommand 0;
BA_ "GenSigTimeoutMsg_HU_B" SG_ 484 ApproachLighCommand 0;
BA_ "GenSigTimeoutMsg_HU_A" SG_ 484 ApproachLighCommand 0;
BA_ "GenSigSendType" SG_ 484 ApproachLighCommand 2;
BA_ "GenSigTimeoutTime_HU_B" SG_ 484 UnLockTailgageCommandStatus 0;
BA_ "GenSigTimeoutTime_HU_A" SG_ 484 UnLockTailgageCommandStatus 0;
BA_ "GenSigTimeoutMsg_HU_B" SG_ 484 UnLockTailgageCommandStatus 0;
BA_ "GenSigTimeoutMsg_HU_A" SG_ 484 UnLockTailgageCommandStatus 0;
BA_ "GenSigSendType" SG_ 484 UnLockTailgageCommandStatus 2;
BA_ "GenSigTimeoutTime_HU_B" SG_ 484 UnLockAllDoorCommandStatus 0;
BA_ "GenSigTimeoutTime_HU_A" SG_ 484 UnLockAllDoorCommandStatus 0;
BA_ "GenSigTimeoutMsg_HU_B" SG_ 484 UnLockAllDoorCommandStatus 0;
BA_ "GenSigTimeoutMsg_HU_A" SG_ 484 UnLockAllDoorCommandStatus 0;
BA_ "GenSigSendType" SG_ 484 UnLockAllDoorCommandStatus 2;
BA_ "GenSigTimeoutTime_HU_B" SG_ 484 WindowUpCommandStatus 0;
BA_ "GenSigTimeoutTime_HU_A" SG_ 484 WindowUpCommandStatus 0;
BA_ "GenSigTimeoutMsg_HU_B" SG_ 484 WindowUpCommandStatus 0;
BA_ "GenSigTimeoutMsg_HU_A" SG_ 484 WindowUpCommandStatus 0;
BA_ "GenSigSendType" SG_ 484 WindowUpCommandStatus 2;
BA_ "GenSigTimeoutTime_HU_B" SG_ 484 WindowUpCommand 0;
BA_ "GenSigTimeoutTime_HU_A" SG_ 484 WindowUpCommand 0;
BA_ "GenSigTimeoutMsg_HU_B" SG_ 484 WindowUpCommand 0;
BA_ "GenSigTimeoutMsg_HU_A" SG_ 484 WindowUpCommand 0;
BA_ "GenSigSendType" SG_ 484 WindowUpCommand 2;
BA_ "GenSigTimeoutTime_HU_B" SG_ 484 WindowDownCommandStatus 0;
BA_ "GenSigTimeoutTime_HU_A" SG_ 484 WindowDownCommandStatus 0;
BA_ "GenSigTimeoutMsg_HU_B" SG_ 484 WindowDownCommandStatus 0;
BA_ "GenSigTimeoutMsg_HU_A" SG_ 484 WindowDownCommandStatus 0;
BA_ "GenSigSendType" SG_ 484 WindowDownCommandStatus 2;
BA_ "GenSigTimeoutTime_HU_B" SG_ 484 WindowDownCommand 0;
BA_ "GenSigTimeoutTime_HU_A" SG_ 484 WindowDownCommand 0;
BA_ "GenSigTimeoutMsg_HU_B" SG_ 484 WindowDownCommand 0;
BA_ "GenSigTimeoutMsg_HU_A" SG_ 484 WindowDownCommand 0;
BA_ "GenSigSendType" SG_ 484 WindowDownCommand 2;
BA_ "GenSigTimeoutTime_HU_B" SG_ 484 ForcePanicCommandStatus 0;
BA_ "GenSigTimeoutTime_HU_A" SG_ 484 ForcePanicCommandStatus 0;
BA_ "GenSigTimeoutMsg_HU_B" SG_ 484 ForcePanicCommandStatus 0;
BA_ "GenSigTimeoutMsg_HU_A" SG_ 484 ForcePanicCommandStatus 0;
BA_ "GenSigSendType" SG_ 484 ForcePanicCommandStatus 2;
BA_ "GenSigTimeoutTime_HU_B" SG_ 484 Reserved 0;
BA_ "GenSigTimeoutTime_HU_A" SG_ 484 Reserved 0;
BA_ "GenSigTimeoutMsg_HU_B" SG_ 484 Reserved 0;
BA_ "GenSigTimeoutMsg_HU_A" SG_ 484 Reserved 0;
BA_ "GenSigSendType" SG_ 484 Reserved 2;
BA_ "GenSigTimeoutTime_HU_B" SG_ 484 VehicleSeekCommandStatus 0;
BA_ "GenSigTimeoutTime_HU_A" SG_ 484 VehicleSeekCommandStatus 0;
BA_ "GenSigTimeoutMsg_HU_B" SG_ 484 VehicleSeekCommandStatus 0;
BA_ "GenSigTimeoutMsg_HU_A" SG_ 484 VehicleSeekCommandStatus 0;
BA_ "GenSigSendType" SG_ 484 VehicleSeekCommandStatus 2;
BA_ "GenSigTimeoutTime_HU_B" SG_ 484 VehicleSeekCommand 0;
BA_ "GenSigTimeoutTime_HU_A" SG_ 484 VehicleSeekCommand 0;
BA_ "GenSigTimeoutMsg_HU_B" SG_ 484 VehicleSeekCommand 0;
BA_ "GenSigTimeoutMsg_HU_A" SG_ 484 VehicleSeekCommand 0;
BA_ "GenSigSendType" SG_ 484 VehicleSeekCommand 2;
BA_ "GenSigTimeoutTime_HU_B" SG_ 484 RandomNumber0 0;
BA_ "GenSigTimeoutTime_HU_A" SG_ 484 RandomNumber0 0;
BA_ "GenSigTimeoutMsg_HU_B" SG_ 484 RandomNumber0 0;
BA_ "GenSigTimeoutMsg_HU_A" SG_ 484 RandomNumber0 0;
BA_ "GenSigSendType" SG_ 484 RandomNumber0 2;
BA_ "GenSigTimeoutTime_HU_B" SG_ 484 RandomNumber1 0;
BA_ "GenSigTimeoutTime_HU_A" SG_ 484 RandomNumber1 0;
BA_ "GenSigTimeoutMsg_HU_B" SG_ 484 RandomNumber1 0;
BA_ "GenSigTimeoutMsg_HU_A" SG_ 484 RandomNumber1 0;
BA_ "GenSigSendType" SG_ 484 RandomNumber1 2;
BA_ "GenSigTimeoutTime_HU_B" SG_ 484 RandomNumber2 0;
BA_ "GenSigTimeoutTime_HU_A" SG_ 484 RandomNumber2 0;
BA_ "GenSigTimeoutMsg_HU_B" SG_ 484 RandomNumber2 0;
BA_ "GenSigTimeoutMsg_HU_A" SG_ 484 RandomNumber2 0;
BA_ "GenSigSendType" SG_ 484 RandomNumber2 2;
BA_ "GenSigTimeoutTime_HU_B" SG_ 484 RandomNumber3 0;
BA_ "GenSigTimeoutTime_HU_A" SG_ 484 RandomNumber3 0;
BA_ "GenSigTimeoutMsg_HU_B" SG_ 484 RandomNumber3 0;
BA_ "GenSigTimeoutMsg_HU_A" SG_ 484 RandomNumber3 0;
BA_ "GenSigSendType" SG_ 484 RandomNumber3 2;
BA_ "GenSigTimeoutTime_HU_B" SG_ 485 CoDriverDHsSwPressState 0;
BA_ "GenSigTimeoutTime_HU_A" SG_ 485 CoDriverDHsSwPressState 0;
BA_ "GenSigTimeoutMsg_HU_B" SG_ 485 CoDriverDHsSwPressState 0;
BA_ "GenSigTimeoutMsg_HU_A" SG_ 485 CoDriverDHsSwPressState 0;
BA_ "GenSigSendType" SG_ 485 CoDriverDHsSwPressState 2;
BA_ "GenSigTimeoutTime_HU_B" SG_ 485 CoDriverDHsSwPressStateStatus 0;
BA_ "GenSigTimeoutTime_HU_A" SG_ 485 CoDriverDHsSwPressStateStatus 0;
BA_ "GenSigTimeoutMsg_HU_B" SG_ 485 CoDriverDHsSwPressStateStatus 0;
BA_ "GenSigTimeoutMsg_HU_A" SG_ 485 CoDriverDHsSwPressStateStatus 0;
BA_ "GenSigSendType" SG_ 485 CoDriverDHsSwPressStateStatus 2;
BA_ "GenSigTimeoutTime_HU_B" SG_ 485 DriverDHsSwPressState 0;
BA_ "GenSigTimeoutTime_HU_A" SG_ 485 DriverDHsSwPressState 0;
BA_ "GenSigTimeoutMsg_HU_B" SG_ 485 DriverDHsSwPressState 0;
BA_ "GenSigTimeoutMsg_HU_A" SG_ 485 DriverDHsSwPressState 0;
BA_ "GenSigSendType" SG_ 485 DriverDHsSwPressState 2;
BA_ "GenSigTimeoutTime_HU_B" SG_ 485 DriverDHsSwPressStateStatus 0;
BA_ "GenSigTimeoutTime_HU_A" SG_ 485 DriverDHsSwPressStateStatus 0;
BA_ "GenSigTimeoutMsg_HU_B" SG_ 485 DriverDHsSwPressStateStatus 0;
BA_ "GenSigTimeoutMsg_HU_A" SG_ 485 DriverDHsSwPressStateStatus 0;
BA_ "GenSigSendType" SG_ 485 DriverDHsSwPressStateStatus 2;
BA_ "GenSigTimeoutTime_HU_B" SG_ 485 RearRhDHsSwPressState 0;
BA_ "GenSigTimeoutTime_HU_A" SG_ 485 RearRhDHsSwPressState 0;
BA_ "GenSigTimeoutMsg_HU_B" SG_ 485 RearRhDHsSwPressState 0;
BA_ "GenSigTimeoutMsg_HU_A" SG_ 485 RearRhDHsSwPressState 0;
BA_ "GenSigSendType" SG_ 485 RearRhDHsSwPressState 2;
BA_ "GenSigTimeoutTime_HU_B" SG_ 485 RearRhDHsSwPressStateStatus 0;
BA_ "GenSigTimeoutTime_HU_A" SG_ 485 RearRhDHsSwPressStateStatus 0;
BA_ "GenSigTimeoutMsg_HU_B" SG_ 485 RearRhDHsSwPressStateStatus 0;
BA_ "GenSigTimeoutMsg_HU_A" SG_ 485 RearRhDHsSwPressStateStatus 0;
BA_ "GenSigSendType" SG_ 485 RearRhDHsSwPressStateStatus 2;
BA_ "GenSigTimeoutTime_HU_B" SG_ 485 RearLhDHsSwPressState 0;
BA_ "GenSigTimeoutTime_HU_A" SG_ 485 RearLhDHsSwPressState 0;
BA_ "GenSigTimeoutMsg_HU_B" SG_ 485 RearLhDHsSwPressState 0;
BA_ "GenSigTimeoutMsg_HU_A" SG_ 485 RearLhDHsSwPressState 0;
BA_ "GenSigSendType" SG_ 485 RearLhDHsSwPressState 2;
BA_ "GenSigTimeoutTime_HU_B" SG_ 485 RearLhDHsSwPressStateStatus 0;
BA_ "GenSigTimeoutTime_HU_A" SG_ 485 RearLhDHsSwPressStateStatus 0;
BA_ "GenSigTimeoutMsg_HU_B" SG_ 485 RearLhDHsSwPressStateStatus 0;
BA_ "GenSigTimeoutMsg_HU_A" SG_ 485 RearLhDHsSwPressStateStatus 0;
BA_ "GenSigSendType" SG_ 485 RearLhDHsSwPressStateStatus 2;
BA_ "GenSigTimeoutTime_HU_B" SG_ 485 RfLockUnlockPEPs 0;
BA_ "GenSigTimeoutTime_HU_A" SG_ 485 RfLockUnlockPEPs 0;
BA_ "GenSigTimeoutMsg_HU_B" SG_ 485 RfLockUnlockPEPs 0;
BA_ "GenSigTimeoutMsg_HU_A" SG_ 485 RfLockUnlockPEPs 0;
BA_ "GenSigSendType" SG_ 485 RfLockUnlockPEPs 2;
BA_ "GenSigTimeoutTime_HU_B" SG_ 485 RfLockUnlockPEPsStatus 0;
BA_ "GenSigTimeoutTime_HU_A" SG_ 485 RfLockUnlockPEPsStatus 0;
BA_ "GenSigTimeoutMsg_HU_B" SG_ 485 RfLockUnlockPEPsStatus 0;
BA_ "GenSigTimeoutMsg_HU_A" SG_ 485 RfLockUnlockPEPsStatus 0;
BA_ "GenSigSendType" SG_ 485 RfLockUnlockPEPsStatus 2;
BA_ "GenSigTimeoutTime_HU_B" SG_ 485 TailgateSwPressState 0;
BA_ "GenSigTimeoutTime_HU_A" SG_ 485 TailgateSwPressState 0;
BA_ "GenSigTimeoutMsg_HU_B" SG_ 485 TailgateSwPressState 0;
BA_ "GenSigTimeoutMsg_HU_A" SG_ 485 TailgateSwPressState 0;
BA_ "GenSigSendType" SG_ 485 TailgateSwPressState 2;
BA_ "GenSigTimeoutTime_HU_B" SG_ 485 TailgateSwPressStateStatus 0;
BA_ "GenSigTimeoutTime_HU_A" SG_ 485 TailgateSwPressStateStatus 0;
BA_ "GenSigTimeoutMsg_HU_B" SG_ 485 TailgateSwPressStateStatus 0;
BA_ "GenSigTimeoutMsg_HU_A" SG_ 485 TailgateSwPressStateStatus 0;
BA_ "GenSigSendType" SG_ 485 TailgateSwPressStateStatus 2;
BA_ "GenSigTimeoutTime_HU_B" SG_ 485 UIdLocationPEPs 0;
BA_ "GenSigTimeoutTime_HU_A" SG_ 485 UIdLocationPEPs 0;
BA_ "GenSigTimeoutMsg_HU_B" SG_ 485 UIdLocationPEPs 0;
BA_ "GenSigTimeoutMsg_HU_A" SG_ 485 UIdLocationPEPs 0;
BA_ "GenSigSendType" SG_ 485 UIdLocationPEPs 2;
BA_ "GenSigTimeoutTime_HU_B" SG_ 485 UIdLocationPEPsStatus 0;
BA_ "GenSigTimeoutTime_HU_A" SG_ 485 UIdLocationPEPsStatus 0;
BA_ "GenSigTimeoutMsg_HU_B" SG_ 485 UIdLocationPEPsStatus 0;
BA_ "GenSigTimeoutMsg_HU_A" SG_ 485 UIdLocationPEPsStatus 0;
BA_ "GenSigSendType" SG_ 485 UIdLocationPEPsStatus 2;
BA_ "GenSigTimeoutTime_HU_B" SG_ 486 PEPsESClAuthReq 0;
BA_ "GenSigTimeoutTime_HU_A" SG_ 486 PEPsESClAuthReq 0;
BA_ "GenSigTimeoutMsg_HU_B" SG_ 486 PEPsESClAuthReq 0;
BA_ "GenSigTimeoutMsg_HU_A" SG_ 486 PEPsESClAuthReq 0;
BA_ "GenSigSendType" SG_ 486 PEPsESClAuthReq 1;
BA_ "GenSigTimeoutTime_HU_B" SG_ 488 ESClPEPsAuthReq 0;
BA_ "GenSigTimeoutTime_HU_A" SG_ 488 ESClPEPsAuthReq 0;
BA_ "GenSigTimeoutMsg_HU_B" SG_ 488 ESClPEPsAuthReq 0;
BA_ "GenSigTimeoutMsg_HU_A" SG_ 488 ESClPEPsAuthReq 0;
BA_ "GenSigSendType" SG_ 488 ESClPEPsAuthReq 1;
BA_ "GenSigTimeoutTime_HU_Mid_X451" SG_ 490 VInInfoToIPC 0;
BA_ "GenSigTimeoutTime_HU_High_X451" SG_ 490 VInInfoToIPC 0;
BA_ "GenSigTimeoutTime_HU_B" SG_ 490 VInInfoToIPC 0;
BA_ "GenSigTimeoutTime_HU_A" SG_ 490 VInInfoToIPC 0;
BA_ "GenSigTimeoutMsg_HU_Mid_X451" SG_ 490 VInInfoToIPC 0;
BA_ "GenSigTimeoutMsg_HU_High_X451" SG_ 490 VInInfoToIPC 0;
BA_ "GenSigTimeoutMsg_HU_B" SG_ 490 VInInfoToIPC 0;
BA_ "GenSigTimeoutMsg_HU_A" SG_ 490 VInInfoToIPC 0;
BA_ "GenSigSendType" SG_ 490 VInInfoToIPC 2;
BA_ "GenSigTimeoutMsg_HU_High_X445" SG_ 490 VInInfoToIPC 0;
BA_ "GenSigTimeoutMsg_HU_Mid_X445" SG_ 490 VInInfoToIPC 0;
BA_ "GenSigTimeoutTime_HU_High_X445" SG_ 490 VInInfoToIPC 0;
BA_ "GenSigTimeoutTime_HU_Mid_X445" SG_ 490 VInInfoToIPC 0;
BA_ "GenSigTimeoutMsg_IVI" SG_ 490 VInInfoToIPC 0;
BA_ "GenSigTimeoutTime_IVI" SG_ 490 VInInfoToIPC 0;
BA_ "GenSigTimeoutTime_HU_Mid_X451" SG_ 492 VehIdetNumIPC 0;
BA_ "GenSigTimeoutTime_HU_High_X451" SG_ 492 VehIdetNumIPC 0;
BA_ "GenSigTimeoutTime_HU_B" SG_ 492 VehIdetNumIPC 0;
BA_ "GenSigTimeoutTime_HU_A" SG_ 492 VehIdetNumIPC 0;
BA_ "GenSigTimeoutMsg_HU_Mid_X451" SG_ 492 VehIdetNumIPC 0;
BA_ "GenSigTimeoutMsg_HU_High_X451" SG_ 492 VehIdetNumIPC 0;
BA_ "GenSigTimeoutMsg_HU_B" SG_ 492 VehIdetNumIPC 0;
BA_ "GenSigTimeoutMsg_HU_A" SG_ 492 VehIdetNumIPC 0;
BA_ "GenSigSendType" SG_ 492 VehIdetNumIPC 1;
BA_ "GenSigTimeoutMsg_HU_High_X445" SG_ 492 VehIdetNumIPC 0;
BA_ "GenSigTimeoutMsg_HU_Mid_X445" SG_ 492 VehIdetNumIPC 0;
BA_ "GenSigTimeoutTime_HU_High_X445" SG_ 492 VehIdetNumIPC 0;
BA_ "GenSigTimeoutTime_HU_Mid_X445" SG_ 492 VehIdetNumIPC 0;
BA_ "GenSigTimeoutMsg_IVI" SG_ 492 VehIdetNumIPC 0;
BA_ "GenSigTimeoutTime_IVI" SG_ 492 VehIdetNumIPC 0;
BA_ "GenSigTimeoutTime_HU_B" SG_ 494 PEPsBCmAuthMsg2 0;
BA_ "GenSigTimeoutTime_HU_A" SG_ 494 PEPsBCmAuthMsg2 0;
BA_ "GenSigTimeoutMsg_HU_B" SG_ 494 PEPsBCmAuthMsg2 0;
BA_ "GenSigTimeoutMsg_HU_A" SG_ 494 PEPsBCmAuthMsg2 0;
BA_ "GenSigSendType" SG_ 494 PEPsBCmAuthMsg2 2;
BA_ "GenSigTimeoutTime_HU_Mid_X451" SG_ 497 HuCcmExpressCoolSwitchReq 0;
BA_ "GenSigTimeoutTime_HU_High_X451" SG_ 497 HuCcmExpressCoolSwitchReq 0;
BA_ "GenSigTimeoutTime_HU_B" SG_ 497 HuCcmExpressCoolSwitchReq 0;
BA_ "GenSigTimeoutTime_HU_A" SG_ 497 HuCcmExpressCoolSwitchReq 0;
BA_ "GenSigTimeoutMsg_HU_Mid_X451" SG_ 497 HuCcmExpressCoolSwitchReq 0;
BA_ "GenSigTimeoutMsg_HU_High_X451" SG_ 497 HuCcmExpressCoolSwitchReq 0;
BA_ "GenSigTimeoutMsg_HU_B" SG_ 497 HuCcmExpressCoolSwitchReq 0;
BA_ "GenSigTimeoutMsg_HU_A" SG_ 497 HuCcmExpressCoolSwitchReq 0;
BA_ "GenSigSendType" SG_ 497 HuCcmExpressCoolSwitchReq 1;
BA_ "GenSigTimeoutMsg_HU_High_X445" SG_ 497 HuCcmExpressCoolSwitchReq 0;
BA_ "GenSigTimeoutMsg_HU_Mid_X445" SG_ 497 HuCcmExpressCoolSwitchReq 0;
BA_ "GenSigTimeoutTime_HU_High_X445" SG_ 497 HuCcmExpressCoolSwitchReq 0;
BA_ "GenSigTimeoutTime_HU_Mid_X445" SG_ 497 HuCcmExpressCoolSwitchReq 0;
BA_ "GenSigTimeoutMsg_IVI" SG_ 497 HuCcmExpressCoolSwitchReq 0;
BA_ "GenSigTimeoutTime_IVI" SG_ 497 HuCcmExpressCoolSwitchReq 0;
BA_ "GenSigTimeoutTime_HU_Mid_X451" SG_ 497 HuCCmFanSpdReq 0;
BA_ "GenSigTimeoutTime_HU_High_X451" SG_ 497 HuCCmFanSpdReq 0;
BA_ "GenSigTimeoutTime_HU_B" SG_ 497 HuCCmFanSpdReq 0;
BA_ "GenSigTimeoutTime_HU_A" SG_ 497 HuCCmFanSpdReq 0;
BA_ "GenSigTimeoutMsg_HU_Mid_X451" SG_ 497 HuCCmFanSpdReq 0;
BA_ "GenSigTimeoutMsg_HU_High_X451" SG_ 497 HuCCmFanSpdReq 0;
BA_ "GenSigTimeoutMsg_HU_B" SG_ 497 HuCCmFanSpdReq 0;
BA_ "GenSigTimeoutMsg_HU_A" SG_ 497 HuCCmFanSpdReq 0;
BA_ "GenSigSendType" SG_ 497 HuCCmFanSpdReq 1;
BA_ "GenSigTimeoutMsg_HU_High_X445" SG_ 497 HuCCmFanSpdReq 0;
BA_ "GenSigTimeoutMsg_HU_Mid_X445" SG_ 497 HuCCmFanSpdReq 0;
BA_ "GenSigTimeoutTime_HU_High_X445" SG_ 497 HuCCmFanSpdReq 0;
BA_ "GenSigTimeoutTime_HU_Mid_X445" SG_ 497 HuCCmFanSpdReq 0;
BA_ "GenSigTimeoutMsg_IVI" SG_ 497 HuCCmFanSpdReq 0;
BA_ "GenSigTimeoutTime_IVI" SG_ 497 HuCCmFanSpdReq 0;
BA_ "GenSigTimeoutTime_HU_Mid_X451" SG_ 497 HuCCmDistribReq 0;
BA_ "GenSigTimeoutTime_HU_High_X451" SG_ 497 HuCCmDistribReq 0;
BA_ "GenSigTimeoutTime_HU_B" SG_ 497 HuCCmDistribReq 0;
BA_ "GenSigTimeoutTime_HU_A" SG_ 497 HuCCmDistribReq 0;
BA_ "GenSigTimeoutMsg_HU_Mid_X451" SG_ 497 HuCCmDistribReq 0;
BA_ "GenSigTimeoutMsg_HU_High_X451" SG_ 497 HuCCmDistribReq 0;
BA_ "GenSigTimeoutMsg_HU_B" SG_ 497 HuCCmDistribReq 0;
BA_ "GenSigTimeoutMsg_HU_A" SG_ 497 HuCCmDistribReq 0;
BA_ "GenSigSendType" SG_ 497 HuCCmDistribReq 1;
BA_ "GenSigTimeoutMsg_HU_High_X445" SG_ 497 HuCCmDistribReq 0;
BA_ "GenSigTimeoutMsg_HU_Mid_X445" SG_ 497 HuCCmDistribReq 0;
BA_ "GenSigTimeoutTime_HU_High_X445" SG_ 497 HuCCmDistribReq 0;
BA_ "GenSigTimeoutTime_HU_Mid_X445" SG_ 497 HuCCmDistribReq 0;
BA_ "GenSigTimeoutMsg_IVI" SG_ 497 HuCCmDistribReq 0;
BA_ "GenSigTimeoutTime_IVI" SG_ 497 HuCCmDistribReq 0;
BA_ "GenSigTimeoutTime_HU_Mid_X451" SG_ 497 HuCCmDualModeReq 0;
BA_ "GenSigTimeoutTime_HU_High_X451" SG_ 497 HuCCmDualModeReq 0;
BA_ "GenSigTimeoutTime_HU_B" SG_ 497 HuCCmDualModeReq 0;
BA_ "GenSigTimeoutTime_HU_A" SG_ 497 HuCCmDualModeReq 0;
BA_ "GenSigTimeoutMsg_HU_Mid_X451" SG_ 497 HuCCmDualModeReq 0;
BA_ "GenSigTimeoutMsg_HU_High_X451" SG_ 497 HuCCmDualModeReq 0;
BA_ "GenSigTimeoutMsg_HU_B" SG_ 497 HuCCmDualModeReq 0;
BA_ "GenSigTimeoutMsg_HU_A" SG_ 497 HuCCmDualModeReq 0;
BA_ "GenSigSendType" SG_ 497 HuCCmDualModeReq 1;
BA_ "GenSigTimeoutMsg_HU_High_X445" SG_ 497 HuCCmDualModeReq 0;
BA_ "GenSigTimeoutMsg_HU_Mid_X445" SG_ 497 HuCCmDualModeReq 0;
BA_ "GenSigTimeoutTime_HU_High_X445" SG_ 497 HuCCmDualModeReq 0;
BA_ "GenSigTimeoutTime_HU_Mid_X445" SG_ 497 HuCCmDualModeReq 0;
BA_ "GenSigTimeoutMsg_IVI" SG_ 497 HuCCmDualModeReq 0;
BA_ "GenSigTimeoutTime_IVI" SG_ 497 HuCCmDualModeReq 0;
BA_ "GenSigTimeoutTime_HU_Mid_X451" SG_ 497 HuCCmTempReqPass 0;
BA_ "GenSigTimeoutTime_HU_High_X451" SG_ 497 HuCCmTempReqPass 0;
BA_ "GenSigTimeoutTime_HU_B" SG_ 497 HuCCmTempReqPass 0;
BA_ "GenSigTimeoutTime_HU_A" SG_ 497 HuCCmTempReqPass 0;
BA_ "GenSigTimeoutMsg_HU_Mid_X451" SG_ 497 HuCCmTempReqPass 0;
BA_ "GenSigTimeoutMsg_HU_High_X451" SG_ 497 HuCCmTempReqPass 0;
BA_ "GenSigTimeoutMsg_HU_B" SG_ 497 HuCCmTempReqPass 0;
BA_ "GenSigTimeoutMsg_HU_A" SG_ 497 HuCCmTempReqPass 0;
BA_ "GenSigSendType" SG_ 497 HuCCmTempReqPass 1;
BA_ "GenSigTimeoutMsg_HU_High_X445" SG_ 497 HuCCmTempReqPass 0;
BA_ "GenSigTimeoutMsg_HU_Mid_X445" SG_ 497 HuCCmTempReqPass 0;
BA_ "GenSigTimeoutTime_HU_High_X445" SG_ 497 HuCCmTempReqPass 0;
BA_ "GenSigTimeoutTime_HU_Mid_X445" SG_ 497 HuCCmTempReqPass 0;
BA_ "GenSigTimeoutMsg_IVI" SG_ 497 HuCCmTempReqPass 0;
BA_ "GenSigTimeoutTime_IVI" SG_ 497 HuCCmTempReqPass 0;
BA_ "GenSigTimeoutTime_HU_Mid_X451" SG_ 497 HuCCmFreshAirRecircReq 0;
BA_ "GenSigTimeoutTime_HU_High_X451" SG_ 497 HuCCmFreshAirRecircReq 0;
BA_ "GenSigTimeoutTime_HU_B" SG_ 497 HuCCmFreshAirRecircReq 0;
BA_ "GenSigTimeoutTime_HU_A" SG_ 497 HuCCmFreshAirRecircReq 0;
BA_ "GenSigTimeoutMsg_HU_Mid_X451" SG_ 497 HuCCmFreshAirRecircReq 0;
BA_ "GenSigTimeoutMsg_HU_High_X451" SG_ 497 HuCCmFreshAirRecircReq 0;
BA_ "GenSigTimeoutMsg_HU_B" SG_ 497 HuCCmFreshAirRecircReq 0;
BA_ "GenSigTimeoutMsg_HU_A" SG_ 497 HuCCmFreshAirRecircReq 0;
BA_ "GenSigSendType" SG_ 497 HuCCmFreshAirRecircReq 1;
BA_ "GenSigTimeoutMsg_HU_High_X445" SG_ 497 HuCCmFreshAirRecircReq 0;
BA_ "GenSigTimeoutMsg_HU_Mid_X445" SG_ 497 HuCCmFreshAirRecircReq 0;
BA_ "GenSigTimeoutTime_HU_High_X445" SG_ 497 HuCCmFreshAirRecircReq 0;
BA_ "GenSigTimeoutTime_HU_Mid_X445" SG_ 497 HuCCmFreshAirRecircReq 0;
BA_ "GenSigTimeoutMsg_IVI" SG_ 497 HuCCmFreshAirRecircReq 0;
BA_ "GenSigTimeoutTime_IVI" SG_ 497 HuCCmFreshAirRecircReq 0;
BA_ "GenSigTimeoutTime_HU_Mid_X451" SG_ 497 HuCCmAutoReq 0;
BA_ "GenSigTimeoutTime_HU_High_X451" SG_ 497 HuCCmAutoReq 0;
BA_ "GenSigTimeoutTime_HU_B" SG_ 497 HuCCmAutoReq 0;
BA_ "GenSigTimeoutTime_HU_A" SG_ 497 HuCCmAutoReq 0;
BA_ "GenSigTimeoutMsg_HU_Mid_X451" SG_ 497 HuCCmAutoReq 0;
BA_ "GenSigTimeoutMsg_HU_High_X451" SG_ 497 HuCCmAutoReq 0;
BA_ "GenSigTimeoutMsg_HU_B" SG_ 497 HuCCmAutoReq 0;
BA_ "GenSigTimeoutMsg_HU_A" SG_ 497 HuCCmAutoReq 0;
BA_ "GenSigSendType" SG_ 497 HuCCmAutoReq 1;
BA_ "GenSigTimeoutMsg_HU_High_X445" SG_ 497 HuCCmAutoReq 0;
BA_ "GenSigTimeoutMsg_HU_Mid_X445" SG_ 497 HuCCmAutoReq 0;
BA_ "GenSigTimeoutTime_HU_High_X445" SG_ 497 HuCCmAutoReq 0;
BA_ "GenSigTimeoutTime_HU_Mid_X445" SG_ 497 HuCCmAutoReq 0;
BA_ "GenSigTimeoutMsg_IVI" SG_ 497 HuCCmAutoReq 0;
BA_ "GenSigTimeoutTime_IVI" SG_ 497 HuCCmAutoReq 0;
BA_ "GenSigTimeoutTime_HU_Mid_X451" SG_ 497 HuCCmTempReq 0;
BA_ "GenSigTimeoutTime_HU_High_X451" SG_ 497 HuCCmTempReq 0;
BA_ "GenSigTimeoutTime_HU_B" SG_ 497 HuCCmTempReq 0;
BA_ "GenSigTimeoutTime_HU_A" SG_ 497 HuCCmTempReq 0;
BA_ "GenSigTimeoutMsg_HU_Mid_X451" SG_ 497 HuCCmTempReq 0;
BA_ "GenSigTimeoutMsg_HU_High_X451" SG_ 497 HuCCmTempReq 0;
BA_ "GenSigTimeoutMsg_HU_B" SG_ 497 HuCCmTempReq 0;
BA_ "GenSigTimeoutMsg_HU_A" SG_ 497 HuCCmTempReq 0;
BA_ "GenSigSendType" SG_ 497 HuCCmTempReq 1;
BA_ "GenSigTimeoutMsg_HU_High_X445" SG_ 497 HuCCmTempReq 0;
BA_ "GenSigTimeoutMsg_HU_Mid_X445" SG_ 497 HuCCmTempReq 0;
BA_ "GenSigTimeoutTime_HU_High_X445" SG_ 497 HuCCmTempReq 0;
BA_ "GenSigTimeoutTime_HU_Mid_X445" SG_ 497 HuCCmTempReq 0;
BA_ "GenSigTimeoutMsg_IVI" SG_ 497 HuCCmTempReq 0;
BA_ "GenSigTimeoutTime_IVI" SG_ 497 HuCCmTempReq 0;
BA_ "GenSigTimeoutTime_HU_Mid_X451" SG_ 497 HuCCmEconModeReq 0;
BA_ "GenSigTimeoutTime_HU_High_X451" SG_ 497 HuCCmEconModeReq 0;
BA_ "GenSigTimeoutTime_HU_B" SG_ 497 HuCCmEconModeReq 0;
BA_ "GenSigTimeoutTime_HU_A" SG_ 497 HuCCmEconModeReq 0;
BA_ "GenSigTimeoutMsg_HU_Mid_X451" SG_ 497 HuCCmEconModeReq 0;
BA_ "GenSigTimeoutMsg_HU_High_X451" SG_ 497 HuCCmEconModeReq 0;
BA_ "GenSigTimeoutMsg_HU_B" SG_ 497 HuCCmEconModeReq 0;
BA_ "GenSigTimeoutMsg_HU_A" SG_ 497 HuCCmEconModeReq 0;
BA_ "GenSigSendType" SG_ 497 HuCCmEconModeReq 1;
BA_ "GenSigTimeoutMsg_HU_High_X445" SG_ 497 HuCCmEconModeReq 0;
BA_ "GenSigTimeoutMsg_HU_Mid_X445" SG_ 497 HuCCmEconModeReq 0;
BA_ "GenSigTimeoutTime_HU_High_X445" SG_ 497 HuCCmEconModeReq 0;
BA_ "GenSigTimeoutTime_HU_Mid_X445" SG_ 497 HuCCmEconModeReq 0;
BA_ "GenSigTimeoutMsg_IVI" SG_ 497 HuCCmEconModeReq 0;
BA_ "GenSigTimeoutTime_IVI" SG_ 497 HuCCmEconModeReq 0;
BA_ "GenSigTimeoutTime_HU_Mid_X451" SG_ 497 HuCCmMaxDefrstReq 0;
BA_ "GenSigTimeoutTime_HU_High_X451" SG_ 497 HuCCmMaxDefrstReq 0;
BA_ "GenSigTimeoutTime_HU_B" SG_ 497 HuCCmMaxDefrstReq 0;
BA_ "GenSigTimeoutTime_HU_A" SG_ 497 HuCCmMaxDefrstReq 0;
BA_ "GenSigTimeoutMsg_HU_Mid_X451" SG_ 497 HuCCmMaxDefrstReq 0;
BA_ "GenSigTimeoutMsg_HU_High_X451" SG_ 497 HuCCmMaxDefrstReq 0;
BA_ "GenSigTimeoutMsg_HU_B" SG_ 497 HuCCmMaxDefrstReq 0;
BA_ "GenSigTimeoutMsg_HU_A" SG_ 497 HuCCmMaxDefrstReq 0;
BA_ "GenSigSendType" SG_ 497 HuCCmMaxDefrstReq 1;
BA_ "GenSigTimeoutMsg_HU_High_X445" SG_ 497 HuCCmMaxDefrstReq 0;
BA_ "GenSigTimeoutMsg_HU_Mid_X445" SG_ 497 HuCCmMaxDefrstReq 0;
BA_ "GenSigTimeoutTime_HU_High_X445" SG_ 497 HuCCmMaxDefrstReq 0;
BA_ "GenSigTimeoutTime_HU_Mid_X445" SG_ 497 HuCCmMaxDefrstReq 0;
BA_ "GenSigTimeoutMsg_IVI" SG_ 497 HuCCmMaxDefrstReq 0;
BA_ "GenSigTimeoutTime_IVI" SG_ 497 HuCCmMaxDefrstReq 0;
BA_ "GenSigTimeoutTime_HU_Mid_X451" SG_ 497 HuCCmRearDefogReq 0;
BA_ "GenSigTimeoutTime_HU_High_X451" SG_ 497 HuCCmRearDefogReq 0;
BA_ "GenSigTimeoutTime_HU_B" SG_ 497 HuCCmRearDefogReq 0;
BA_ "GenSigTimeoutTime_HU_A" SG_ 497 HuCCmRearDefogReq 0;
BA_ "GenSigTimeoutMsg_HU_Mid_X451" SG_ 497 HuCCmRearDefogReq 0;
BA_ "GenSigTimeoutMsg_HU_High_X451" SG_ 497 HuCCmRearDefogReq 0;
BA_ "GenSigTimeoutMsg_HU_B" SG_ 497 HuCCmRearDefogReq 0;
BA_ "GenSigTimeoutMsg_HU_A" SG_ 497 HuCCmRearDefogReq 0;
BA_ "GenSigSendType" SG_ 497 HuCCmRearDefogReq 1;
BA_ "GenSigTimeoutMsg_HU_High_X445" SG_ 497 HuCCmRearDefogReq 0;
BA_ "GenSigTimeoutMsg_HU_Mid_X445" SG_ 497 HuCCmRearDefogReq 0;
BA_ "GenSigTimeoutTime_HU_High_X445" SG_ 497 HuCCmRearDefogReq 0;
BA_ "GenSigTimeoutTime_HU_Mid_X445" SG_ 497 HuCCmRearDefogReq 0;
BA_ "GenSigTimeoutMsg_IVI" SG_ 497 HuCCmRearDefogReq 0;
BA_ "GenSigTimeoutTime_IVI" SG_ 497 HuCCmRearDefogReq 0;
BA_ "GenSigTimeoutTime_HU_Mid_X451" SG_ 497 HuCCmTempReqDrvr 0;
BA_ "GenSigTimeoutTime_HU_High_X451" SG_ 497 HuCCmTempReqDrvr 0;
BA_ "GenSigTimeoutTime_HU_B" SG_ 497 HuCCmTempReqDrvr 0;
BA_ "GenSigTimeoutTime_HU_A" SG_ 497 HuCCmTempReqDrvr 0;
BA_ "GenSigTimeoutMsg_HU_Mid_X451" SG_ 497 HuCCmTempReqDrvr 0;
BA_ "GenSigTimeoutMsg_HU_High_X451" SG_ 497 HuCCmTempReqDrvr 0;
BA_ "GenSigTimeoutMsg_HU_B" SG_ 497 HuCCmTempReqDrvr 0;
BA_ "GenSigTimeoutMsg_HU_A" SG_ 497 HuCCmTempReqDrvr 0;
BA_ "GenSigSendType" SG_ 497 HuCCmTempReqDrvr 1;
BA_ "GenSigTimeoutMsg_HU_High_X445" SG_ 497 HuCCmTempReqDrvr 0;
BA_ "GenSigTimeoutMsg_HU_Mid_X445" SG_ 497 HuCCmTempReqDrvr 0;
BA_ "GenSigTimeoutTime_HU_High_X445" SG_ 497 HuCCmTempReqDrvr 0;
BA_ "GenSigTimeoutTime_HU_Mid_X445" SG_ 497 HuCCmTempReqDrvr 0;
BA_ "GenSigTimeoutMsg_IVI" SG_ 497 HuCCmTempReqDrvr 0;
BA_ "GenSigTimeoutTime_IVI" SG_ 497 HuCCmTempReqDrvr 0;
BA_ "GenSigTimeoutTime_HU_Mid_X451" SG_ 497 HuCCmAirConCompReq 0;
BA_ "GenSigTimeoutTime_HU_High_X451" SG_ 497 HuCCmAirConCompReq 0;
BA_ "GenSigTimeoutTime_HU_B" SG_ 497 HuCCmAirConCompReq 0;
BA_ "GenSigTimeoutTime_HU_A" SG_ 497 HuCCmAirConCompReq 0;
BA_ "GenSigTimeoutMsg_HU_Mid_X451" SG_ 497 HuCCmAirConCompReq 0;
BA_ "GenSigTimeoutMsg_HU_High_X451" SG_ 497 HuCCmAirConCompReq 0;
BA_ "GenSigTimeoutMsg_HU_B" SG_ 497 HuCCmAirConCompReq 0;
BA_ "GenSigTimeoutMsg_HU_A" SG_ 497 HuCCmAirConCompReq 0;
BA_ "GenSigSendType" SG_ 497 HuCCmAirConCompReq 1;
BA_ "GenSigTimeoutMsg_HU_High_X445" SG_ 497 HuCCmAirConCompReq 0;
BA_ "GenSigTimeoutMsg_HU_Mid_X445" SG_ 497 HuCCmAirConCompReq 0;
BA_ "GenSigTimeoutTime_HU_High_X445" SG_ 497 HuCCmAirConCompReq 0;
BA_ "GenSigTimeoutTime_HU_Mid_X445" SG_ 497 HuCCmAirConCompReq 0;
BA_ "GenSigTimeoutMsg_IVI" SG_ 497 HuCCmAirConCompReq 0;
BA_ "GenSigTimeoutTime_IVI" SG_ 497 HuCCmAirConCompReq 0;
BA_ "GenSigTimeoutTime_HU_Mid_X451" SG_ 497 HuCCmHVAcOFFReq 0;
BA_ "GenSigTimeoutTime_HU_High_X451" SG_ 497 HuCCmHVAcOFFReq 0;
BA_ "GenSigTimeoutTime_HU_B" SG_ 497 HuCCmHVAcOFFReq 0;
BA_ "GenSigTimeoutTime_HU_A" SG_ 497 HuCCmHVAcOFFReq 0;
BA_ "GenSigTimeoutMsg_HU_Mid_X451" SG_ 497 HuCCmHVAcOFFReq 0;
BA_ "GenSigTimeoutMsg_HU_High_X451" SG_ 497 HuCCmHVAcOFFReq 0;
BA_ "GenSigTimeoutMsg_HU_B" SG_ 497 HuCCmHVAcOFFReq 0;
BA_ "GenSigTimeoutMsg_HU_A" SG_ 497 HuCCmHVAcOFFReq 0;
BA_ "GenSigSendType" SG_ 497 HuCCmHVAcOFFReq 1;
BA_ "GenSigTimeoutMsg_HU_High_X445" SG_ 497 HuCCmHVAcOFFReq 0;
BA_ "GenSigTimeoutMsg_HU_Mid_X445" SG_ 497 HuCCmHVAcOFFReq 0;
BA_ "GenSigTimeoutTime_HU_High_X445" SG_ 497 HuCCmHVAcOFFReq 0;
BA_ "GenSigTimeoutTime_HU_Mid_X445" SG_ 497 HuCCmHVAcOFFReq 0;
BA_ "GenSigTimeoutMsg_IVI" SG_ 497 HuCCmHVAcOFFReq 0;
BA_ "GenSigTimeoutTime_IVI" SG_ 497 HuCCmHVAcOFFReq 0;
BA_ "GenSigTimeoutTime_HU_Mid_X451" SG_ 497 HuCCmQueryFlag 0;
BA_ "GenSigTimeoutTime_HU_High_X451" SG_ 497 HuCCmQueryFlag 0;
BA_ "GenSigTimeoutTime_HU_B" SG_ 497 HuCCmQueryFlag 0;
BA_ "GenSigTimeoutTime_HU_A" SG_ 497 HuCCmQueryFlag 0;
BA_ "GenSigTimeoutMsg_HU_Mid_X451" SG_ 497 HuCCmQueryFlag 0;
BA_ "GenSigTimeoutMsg_HU_High_X451" SG_ 497 HuCCmQueryFlag 0;
BA_ "GenSigTimeoutMsg_HU_B" SG_ 497 HuCCmQueryFlag 0;
BA_ "GenSigTimeoutMsg_HU_A" SG_ 497 HuCCmQueryFlag 0;
BA_ "GenSigSendType" SG_ 497 HuCCmQueryFlag 1;
BA_ "GenSigTimeoutMsg_HU_High_X445" SG_ 497 HuCCmQueryFlag 0;
BA_ "GenSigTimeoutMsg_HU_Mid_X445" SG_ 497 HuCCmQueryFlag 0;
BA_ "GenSigTimeoutTime_HU_High_X445" SG_ 497 HuCCmQueryFlag 0;
BA_ "GenSigTimeoutTime_HU_Mid_X445" SG_ 497 HuCCmQueryFlag 0;
BA_ "GenSigTimeoutMsg_IVI" SG_ 497 HuCCmQueryFlag 0;
BA_ "GenSigTimeoutTime_IVI" SG_ 497 HuCCmQueryFlag 0;
BA_ "GenSigTimeoutTime_HU_Mid_X451" SG_ 497 HuCCmUserInterventionStatusFlag 0;
BA_ "GenSigTimeoutTime_HU_High_X451" SG_ 497 HuCCmUserInterventionStatusFlag 0;
BA_ "GenSigTimeoutTime_HU_B" SG_ 497 HuCCmUserInterventionStatusFlag 0;
BA_ "GenSigTimeoutTime_HU_A" SG_ 497 HuCCmUserInterventionStatusFlag 0;
BA_ "GenSigTimeoutMsg_HU_Mid_X451" SG_ 497 HuCCmUserInterventionStatusFlag 0;
BA_ "GenSigTimeoutMsg_HU_High_X451" SG_ 497 HuCCmUserInterventionStatusFlag 0;
BA_ "GenSigTimeoutMsg_HU_B" SG_ 497 HuCCmUserInterventionStatusFlag 0;
BA_ "GenSigTimeoutMsg_HU_A" SG_ 497 HuCCmUserInterventionStatusFlag 0;
BA_ "GenSigSendType" SG_ 497 HuCCmUserInterventionStatusFlag 1;
BA_ "GenSigTimeoutMsg_HU_High_X445" SG_ 497 HuCCmUserInterventionStatusFlag 0;
BA_ "GenSigTimeoutMsg_HU_Mid_X445" SG_ 497 HuCCmUserInterventionStatusFlag 0;
BA_ "GenSigTimeoutTime_HU_High_X445" SG_ 497 HuCCmUserInterventionStatusFlag 0;
BA_ "GenSigTimeoutTime_HU_Mid_X445" SG_ 497 HuCCmUserInterventionStatusFlag 0;
BA_ "GenSigTimeoutMsg_IVI" SG_ 497 HuCCmUserInterventionStatusFlag 0;
BA_ "GenSigTimeoutTime_IVI" SG_ 497 HuCCmUserInterventionStatusFlag 0;
BA_ "GenSigTimeoutTime_HU_Mid_X451" SG_ 499 CCmHuFanSpdAck 0;
BA_ "GenSigTimeoutTime_HU_High_X451" SG_ 499 CCmHuFanSpdAck 0;
BA_ "GenSigTimeoutTime_HU_B" SG_ 499 CCmHuFanSpdAck 0;
BA_ "GenSigTimeoutTime_HU_A" SG_ 499 CCmHuFanSpdAck 0;
BA_ "GenSigTimeoutMsg_HU_Mid_X451" SG_ 499 CCmHuFanSpdAck 0;
BA_ "GenSigTimeoutMsg_HU_High_X451" SG_ 499 CCmHuFanSpdAck 0;
BA_ "GenSigTimeoutMsg_HU_B" SG_ 499 CCmHuFanSpdAck 0;
BA_ "GenSigTimeoutMsg_HU_A" SG_ 499 CCmHuFanSpdAck 0;
BA_ "GenSigSendType" SG_ 499 CCmHuFanSpdAck 1;
BA_ "GenSigTimeoutMsg_HU_High_X445" SG_ 499 CCmHuFanSpdAck 0;
BA_ "GenSigTimeoutMsg_HU_Mid_X445" SG_ 499 CCmHuFanSpdAck 0;
BA_ "GenSigTimeoutTime_HU_High_X445" SG_ 499 CCmHuFanSpdAck 0;
BA_ "GenSigTimeoutTime_HU_Mid_X445" SG_ 499 CCmHuFanSpdAck 0;
BA_ "GenSigTimeoutMsg_IVI" SG_ 499 CCmHuFanSpdAck 0;
BA_ "GenSigTimeoutTime_IVI" SG_ 499 CCmHuFanSpdAck 0;
BA_ "GenSigTimeoutTime_HU_Mid_X451" SG_ 499 CCmHuDistribSwitchAck 0;
BA_ "GenSigTimeoutTime_HU_High_X451" SG_ 499 CCmHuDistribSwitchAck 0;
BA_ "GenSigTimeoutTime_HU_B" SG_ 499 CCmHuDistribSwitchAck 0;
BA_ "GenSigTimeoutTime_HU_A" SG_ 499 CCmHuDistribSwitchAck 0;
BA_ "GenSigTimeoutMsg_HU_Mid_X451" SG_ 499 CCmHuDistribSwitchAck 0;
BA_ "GenSigTimeoutMsg_HU_High_X451" SG_ 499 CCmHuDistribSwitchAck 0;
BA_ "GenSigTimeoutMsg_HU_B" SG_ 499 CCmHuDistribSwitchAck 0;
BA_ "GenSigTimeoutMsg_HU_A" SG_ 499 CCmHuDistribSwitchAck 0;
BA_ "GenSigSendType" SG_ 499 CCmHuDistribSwitchAck 1;
BA_ "GenSigTimeoutMsg_HU_High_X445" SG_ 499 CCmHuDistribSwitchAck 0;
BA_ "GenSigTimeoutMsg_HU_Mid_X445" SG_ 499 CCmHuDistribSwitchAck 0;
BA_ "GenSigTimeoutTime_HU_High_X445" SG_ 499 CCmHuDistribSwitchAck 0;
BA_ "GenSigTimeoutTime_HU_Mid_X445" SG_ 499 CCmHuDistribSwitchAck 0;
BA_ "GenSigTimeoutMsg_IVI" SG_ 499 CCmHuDistribSwitchAck 0;
BA_ "GenSigTimeoutTime_IVI" SG_ 499 CCmHuDistribSwitchAck 0;
BA_ "GenSigTimeoutTime_HU_Mid_X451" SG_ 499 CCmHuMaxDefrstSwitchAck 0;
BA_ "GenSigTimeoutTime_HU_High_X451" SG_ 499 CCmHuMaxDefrstSwitchAck 0;
BA_ "GenSigTimeoutTime_HU_B" SG_ 499 CCmHuMaxDefrstSwitchAck 0;
BA_ "GenSigTimeoutTime_HU_A" SG_ 499 CCmHuMaxDefrstSwitchAck 0;
BA_ "GenSigTimeoutMsg_HU_Mid_X451" SG_ 499 CCmHuMaxDefrstSwitchAck 0;
BA_ "GenSigTimeoutMsg_HU_High_X451" SG_ 499 CCmHuMaxDefrstSwitchAck 0;
BA_ "GenSigTimeoutMsg_HU_B" SG_ 499 CCmHuMaxDefrstSwitchAck 0;
BA_ "GenSigTimeoutMsg_HU_A" SG_ 499 CCmHuMaxDefrstSwitchAck 0;
BA_ "GenSigSendType" SG_ 499 CCmHuMaxDefrstSwitchAck 1;
BA_ "GenSigTimeoutMsg_HU_High_X445" SG_ 499 CCmHuMaxDefrstSwitchAck 0;
BA_ "GenSigTimeoutMsg_HU_Mid_X445" SG_ 499 CCmHuMaxDefrstSwitchAck 0;
BA_ "GenSigTimeoutTime_HU_High_X445" SG_ 499 CCmHuMaxDefrstSwitchAck 0;
BA_ "GenSigTimeoutTime_HU_Mid_X445" SG_ 499 CCmHuMaxDefrstSwitchAck 0;
BA_ "GenSigTimeoutMsg_IVI" SG_ 499 CCmHuMaxDefrstSwitchAck 0;
BA_ "GenSigTimeoutTime_IVI" SG_ 499 CCmHuMaxDefrstSwitchAck 0;
BA_ "GenSigTimeoutTime_HU_Mid_X451" SG_ 499 CCmHuEconModeSwitchAck 0;
BA_ "GenSigTimeoutTime_HU_High_X451" SG_ 499 CCmHuEconModeSwitchAck 0;
BA_ "GenSigTimeoutTime_HU_B" SG_ 499 CCmHuEconModeSwitchAck 0;
BA_ "GenSigTimeoutTime_HU_A" SG_ 499 CCmHuEconModeSwitchAck 0;
BA_ "GenSigTimeoutMsg_HU_Mid_X451" SG_ 499 CCmHuEconModeSwitchAck 0;
BA_ "GenSigTimeoutMsg_HU_High_X451" SG_ 499 CCmHuEconModeSwitchAck 0;
BA_ "GenSigTimeoutMsg_HU_B" SG_ 499 CCmHuEconModeSwitchAck 0;
BA_ "GenSigTimeoutMsg_HU_A" SG_ 499 CCmHuEconModeSwitchAck 0;
BA_ "GenSigSendType" SG_ 499 CCmHuEconModeSwitchAck 1;
BA_ "GenSigTimeoutMsg_HU_High_X445" SG_ 499 CCmHuEconModeSwitchAck 0;
BA_ "GenSigTimeoutMsg_HU_Mid_X445" SG_ 499 CCmHuEconModeSwitchAck 0;
BA_ "GenSigTimeoutTime_HU_High_X445" SG_ 499 CCmHuEconModeSwitchAck 0;
BA_ "GenSigTimeoutTime_HU_Mid_X445" SG_ 499 CCmHuEconModeSwitchAck 0;
BA_ "GenSigTimeoutMsg_IVI" SG_ 499 CCmHuEconModeSwitchAck 0;
BA_ "GenSigTimeoutTime_IVI" SG_ 499 CCmHuEconModeSwitchAck 0;
BA_ "GenSigTimeoutTime_HU_Mid_X451" SG_ 499 CCmHuAutoSwitchAck 0;
BA_ "GenSigTimeoutTime_HU_High_X451" SG_ 499 CCmHuAutoSwitchAck 0;
BA_ "GenSigTimeoutTime_HU_B" SG_ 499 CCmHuAutoSwitchAck 0;
BA_ "GenSigTimeoutTime_HU_A" SG_ 499 CCmHuAutoSwitchAck 0;
BA_ "GenSigTimeoutMsg_HU_Mid_X451" SG_ 499 CCmHuAutoSwitchAck 0;
BA_ "GenSigTimeoutMsg_HU_High_X451" SG_ 499 CCmHuAutoSwitchAck 0;
BA_ "GenSigTimeoutMsg_HU_B" SG_ 499 CCmHuAutoSwitchAck 0;
BA_ "GenSigTimeoutMsg_HU_A" SG_ 499 CCmHuAutoSwitchAck 0;
BA_ "GenSigSendType" SG_ 499 CCmHuAutoSwitchAck 1;
BA_ "GenSigTimeoutMsg_HU_High_X445" SG_ 499 CCmHuAutoSwitchAck 0;
BA_ "GenSigTimeoutMsg_HU_Mid_X445" SG_ 499 CCmHuAutoSwitchAck 0;
BA_ "GenSigTimeoutTime_HU_High_X445" SG_ 499 CCmHuAutoSwitchAck 0;
BA_ "GenSigTimeoutTime_HU_Mid_X445" SG_ 499 CCmHuAutoSwitchAck 0;
BA_ "GenSigTimeoutMsg_IVI" SG_ 499 CCmHuAutoSwitchAck 0;
BA_ "GenSigTimeoutTime_IVI" SG_ 499 CCmHuAutoSwitchAck 0;
BA_ "GenSigTimeoutTime_HU_Mid_X451" SG_ 499 CCmHuRearDefogSwitchAck 0;
BA_ "GenSigTimeoutTime_HU_High_X451" SG_ 499 CCmHuRearDefogSwitchAck 0;
BA_ "GenSigTimeoutTime_HU_B" SG_ 499 CCmHuRearDefogSwitchAck 0;
BA_ "GenSigTimeoutTime_HU_A" SG_ 499 CCmHuRearDefogSwitchAck 0;
BA_ "GenSigTimeoutMsg_HU_Mid_X451" SG_ 499 CCmHuRearDefogSwitchAck 0;
BA_ "GenSigTimeoutMsg_HU_High_X451" SG_ 499 CCmHuRearDefogSwitchAck 0;
BA_ "GenSigTimeoutMsg_HU_B" SG_ 499 CCmHuRearDefogSwitchAck 0;
BA_ "GenSigTimeoutMsg_HU_A" SG_ 499 CCmHuRearDefogSwitchAck 0;
BA_ "GenSigSendType" SG_ 499 CCmHuRearDefogSwitchAck 1;
BA_ "GenSigTimeoutMsg_HU_High_X445" SG_ 499 CCmHuRearDefogSwitchAck 0;
BA_ "GenSigTimeoutMsg_HU_Mid_X445" SG_ 499 CCmHuRearDefogSwitchAck 0;
BA_ "GenSigTimeoutTime_HU_High_X445" SG_ 499 CCmHuRearDefogSwitchAck 0;
BA_ "GenSigTimeoutTime_HU_Mid_X445" SG_ 499 CCmHuRearDefogSwitchAck 0;
BA_ "GenSigTimeoutMsg_IVI" SG_ 499 CCmHuRearDefogSwitchAck 0;
BA_ "GenSigTimeoutTime_IVI" SG_ 499 CCmHuRearDefogSwitchAck 0;
BA_ "GenSigTimeoutTime_HU_Mid_X451" SG_ 499 CCmHuAirConCompSwitchAck 0;
BA_ "GenSigTimeoutTime_HU_High_X451" SG_ 499 CCmHuAirConCompSwitchAck 0;
BA_ "GenSigTimeoutTime_HU_B" SG_ 499 CCmHuAirConCompSwitchAck 0;
BA_ "GenSigTimeoutTime_HU_A" SG_ 499 CCmHuAirConCompSwitchAck 0;
BA_ "GenSigTimeoutMsg_HU_Mid_X451" SG_ 499 CCmHuAirConCompSwitchAck 0;
BA_ "GenSigTimeoutMsg_HU_High_X451" SG_ 499 CCmHuAirConCompSwitchAck 0;
BA_ "GenSigTimeoutMsg_HU_B" SG_ 499 CCmHuAirConCompSwitchAck 0;
BA_ "GenSigTimeoutMsg_HU_A" SG_ 499 CCmHuAirConCompSwitchAck 0;
BA_ "GenSigSendType" SG_ 499 CCmHuAirConCompSwitchAck 1;
BA_ "GenSigTimeoutMsg_HU_High_X445" SG_ 499 CCmHuAirConCompSwitchAck 0;
BA_ "GenSigTimeoutMsg_HU_Mid_X445" SG_ 499 CCmHuAirConCompSwitchAck 0;
BA_ "GenSigTimeoutTime_HU_High_X445" SG_ 499 CCmHuAirConCompSwitchAck 0;
BA_ "GenSigTimeoutTime_HU_Mid_X445" SG_ 499 CCmHuAirConCompSwitchAck 0;
BA_ "GenSigTimeoutMsg_IVI" SG_ 499 CCmHuAirConCompSwitchAck 0;
BA_ "GenSigTimeoutTime_IVI" SG_ 499 CCmHuAirConCompSwitchAck 0;
BA_ "GenSigTimeoutTime_HU_Mid_X451" SG_ 499 CCmHuErrAck 0;
BA_ "GenSigTimeoutTime_HU_High_X451" SG_ 499 CCmHuErrAck 0;
BA_ "GenSigTimeoutTime_HU_B" SG_ 499 CCmHuErrAck 0;
BA_ "GenSigTimeoutTime_HU_A" SG_ 499 CCmHuErrAck 0;
BA_ "GenSigTimeoutMsg_HU_Mid_X451" SG_ 499 CCmHuErrAck 0;
BA_ "GenSigTimeoutMsg_HU_High_X451" SG_ 499 CCmHuErrAck 0;
BA_ "GenSigTimeoutMsg_HU_B" SG_ 499 CCmHuErrAck 0;
BA_ "GenSigTimeoutMsg_HU_A" SG_ 499 CCmHuErrAck 0;
BA_ "GenSigSendType" SG_ 499 CCmHuErrAck 1;
BA_ "GenSigTimeoutMsg_HU_High_X445" SG_ 499 CCmHuErrAck 0;
BA_ "GenSigTimeoutMsg_HU_Mid_X445" SG_ 499 CCmHuErrAck 0;
BA_ "GenSigTimeoutTime_HU_High_X445" SG_ 499 CCmHuErrAck 0;
BA_ "GenSigTimeoutTime_HU_Mid_X445" SG_ 499 CCmHuErrAck 0;
BA_ "GenSigTimeoutMsg_IVI" SG_ 499 CCmHuErrAck 0;
BA_ "GenSigTimeoutTime_IVI" SG_ 499 CCmHuErrAck 0;
BA_ "GenSigTimeoutTime_HU_Mid_X451" SG_ 499 CCmHuTempWhlAck 0;
BA_ "GenSigTimeoutTime_HU_High_X451" SG_ 499 CCmHuTempWhlAck 0;
BA_ "GenSigTimeoutTime_HU_B" SG_ 499 CCmHuTempWhlAck 0;
BA_ "GenSigTimeoutTime_HU_A" SG_ 499 CCmHuTempWhlAck 0;
BA_ "GenSigTimeoutMsg_HU_Mid_X451" SG_ 499 CCmHuTempWhlAck 0;
BA_ "GenSigTimeoutMsg_HU_High_X451" SG_ 499 CCmHuTempWhlAck 0;
BA_ "GenSigTimeoutMsg_HU_B" SG_ 499 CCmHuTempWhlAck 0;
BA_ "GenSigTimeoutMsg_HU_A" SG_ 499 CCmHuTempWhlAck 0;
BA_ "GenSigSendType" SG_ 499 CCmHuTempWhlAck 1;
BA_ "GenSigTimeoutMsg_HU_High_X445" SG_ 499 CCmHuTempWhlAck 0;
BA_ "GenSigTimeoutMsg_HU_Mid_X445" SG_ 499 CCmHuTempWhlAck 0;
BA_ "GenSigTimeoutTime_HU_High_X445" SG_ 499 CCmHuTempWhlAck 0;
BA_ "GenSigTimeoutTime_HU_Mid_X445" SG_ 499 CCmHuTempWhlAck 0;
BA_ "GenSigTimeoutMsg_IVI" SG_ 499 CCmHuTempWhlAck 0;
BA_ "GenSigTimeoutTime_IVI" SG_ 499 CCmHuTempWhlAck 0;
BA_ "GenSigTimeoutTime_HU_Mid_X451" SG_ 499 CCmHuFreshAirRecircSwitchAck 0;
BA_ "GenSigTimeoutTime_HU_High_X451" SG_ 499 CCmHuFreshAirRecircSwitchAck 0;
BA_ "GenSigTimeoutTime_HU_B" SG_ 499 CCmHuFreshAirRecircSwitchAck 0;
BA_ "GenSigTimeoutTime_HU_A" SG_ 499 CCmHuFreshAirRecircSwitchAck 0;
BA_ "GenSigTimeoutMsg_HU_Mid_X451" SG_ 499 CCmHuFreshAirRecircSwitchAck 0;
BA_ "GenSigTimeoutMsg_HU_High_X451" SG_ 499 CCmHuFreshAirRecircSwitchAck 0;
BA_ "GenSigTimeoutMsg_HU_B" SG_ 499 CCmHuFreshAirRecircSwitchAck 0;
BA_ "GenSigTimeoutMsg_HU_A" SG_ 499 CCmHuFreshAirRecircSwitchAck 0;
BA_ "GenSigSendType" SG_ 499 CCmHuFreshAirRecircSwitchAck 1;
BA_ "GenSigTimeoutMsg_HU_High_X445" SG_ 499 CCmHuFreshAirRecircSwitchAck 0;
BA_ "GenSigTimeoutMsg_HU_Mid_X445" SG_ 499 CCmHuFreshAirRecircSwitchAck 0;
BA_ "GenSigTimeoutTime_HU_High_X445" SG_ 499 CCmHuFreshAirRecircSwitchAck 0;
BA_ "GenSigTimeoutTime_HU_Mid_X445" SG_ 499 CCmHuFreshAirRecircSwitchAck 0;
BA_ "GenSigTimeoutMsg_IVI" SG_ 499 CCmHuFreshAirRecircSwitchAck 0;
BA_ "GenSigTimeoutTime_IVI" SG_ 499 CCmHuFreshAirRecircSwitchAck 0;
BA_ "GenSigTimeoutTime_HU_Mid_X451" SG_ 499 CCmHuDualModeSwitchAck 0;
BA_ "GenSigTimeoutTime_HU_High_X451" SG_ 499 CCmHuDualModeSwitchAck 0;
BA_ "GenSigTimeoutTime_HU_B" SG_ 499 CCmHuDualModeSwitchAck 0;
BA_ "GenSigTimeoutTime_HU_A" SG_ 499 CCmHuDualModeSwitchAck 0;
BA_ "GenSigTimeoutMsg_HU_Mid_X451" SG_ 499 CCmHuDualModeSwitchAck 0;
BA_ "GenSigTimeoutMsg_HU_High_X451" SG_ 499 CCmHuDualModeSwitchAck 0;
BA_ "GenSigTimeoutMsg_HU_B" SG_ 499 CCmHuDualModeSwitchAck 0;
BA_ "GenSigTimeoutMsg_HU_A" SG_ 499 CCmHuDualModeSwitchAck 0;
BA_ "GenSigSendType" SG_ 499 CCmHuDualModeSwitchAck 1;
BA_ "GenSigTimeoutMsg_HU_High_X445" SG_ 499 CCmHuDualModeSwitchAck 0;
BA_ "GenSigTimeoutMsg_HU_Mid_X445" SG_ 499 CCmHuDualModeSwitchAck 0;
BA_ "GenSigTimeoutTime_HU_High_X445" SG_ 499 CCmHuDualModeSwitchAck 0;
BA_ "GenSigTimeoutTime_HU_Mid_X445" SG_ 499 CCmHuDualModeSwitchAck 0;
BA_ "GenSigTimeoutMsg_IVI" SG_ 499 CCmHuDualModeSwitchAck 0;
BA_ "GenSigTimeoutTime_IVI" SG_ 499 CCmHuDualModeSwitchAck 0;
BA_ "GenSigTimeoutTime_HU_Mid_X451" SG_ 499 CCmHuTempWhlPassAck 0;
BA_ "GenSigTimeoutTime_HU_High_X451" SG_ 499 CCmHuTempWhlPassAck 0;
BA_ "GenSigTimeoutTime_HU_B" SG_ 499 CCmHuTempWhlPassAck 0;
BA_ "GenSigTimeoutTime_HU_A" SG_ 499 CCmHuTempWhlPassAck 0;
BA_ "GenSigTimeoutMsg_HU_Mid_X451" SG_ 499 CCmHuTempWhlPassAck 0;
BA_ "GenSigTimeoutMsg_HU_High_X451" SG_ 499 CCmHuTempWhlPassAck 0;
BA_ "GenSigTimeoutMsg_HU_B" SG_ 499 CCmHuTempWhlPassAck 0;
BA_ "GenSigTimeoutMsg_HU_A" SG_ 499 CCmHuTempWhlPassAck 0;
BA_ "GenSigSendType" SG_ 499 CCmHuTempWhlPassAck 1;
BA_ "GenSigTimeoutMsg_HU_High_X445" SG_ 499 CCmHuTempWhlPassAck 0;
BA_ "GenSigTimeoutMsg_HU_Mid_X445" SG_ 499 CCmHuTempWhlPassAck 0;
BA_ "GenSigTimeoutTime_HU_High_X445" SG_ 499 CCmHuTempWhlPassAck 0;
BA_ "GenSigTimeoutTime_HU_Mid_X445" SG_ 499 CCmHuTempWhlPassAck 0;
BA_ "GenSigTimeoutMsg_IVI" SG_ 499 CCmHuTempWhlPassAck 0;
BA_ "GenSigTimeoutTime_IVI" SG_ 499 CCmHuTempWhlPassAck 0;
BA_ "GenSigTimeoutTime_HU_Mid_X451" SG_ 499 CCmHuTempWhlDrvrAck 0;
BA_ "GenSigTimeoutTime_HU_High_X451" SG_ 499 CCmHuTempWhlDrvrAck 0;
BA_ "GenSigTimeoutTime_HU_B" SG_ 499 CCmHuTempWhlDrvrAck 0;
BA_ "GenSigTimeoutTime_HU_A" SG_ 499 CCmHuTempWhlDrvrAck 0;
BA_ "GenSigTimeoutMsg_HU_Mid_X451" SG_ 499 CCmHuTempWhlDrvrAck 0;
BA_ "GenSigTimeoutMsg_HU_High_X451" SG_ 499 CCmHuTempWhlDrvrAck 0;
BA_ "GenSigTimeoutMsg_HU_B" SG_ 499 CCmHuTempWhlDrvrAck 0;
BA_ "GenSigTimeoutMsg_HU_A" SG_ 499 CCmHuTempWhlDrvrAck 0;
BA_ "GenSigSendType" SG_ 499 CCmHuTempWhlDrvrAck 1;
BA_ "GenSigTimeoutMsg_HU_High_X445" SG_ 499 CCmHuTempWhlDrvrAck 0;
BA_ "GenSigTimeoutMsg_HU_Mid_X445" SG_ 499 CCmHuTempWhlDrvrAck 0;
BA_ "GenSigTimeoutTime_HU_High_X445" SG_ 499 CCmHuTempWhlDrvrAck 0;
BA_ "GenSigTimeoutTime_HU_Mid_X445" SG_ 499 CCmHuTempWhlDrvrAck 0;
BA_ "GenSigTimeoutMsg_IVI" SG_ 499 CCmHuTempWhlDrvrAck 0;
BA_ "GenSigTimeoutTime_IVI" SG_ 499 CCmHuTempWhlDrvrAck 0;
BA_ "GenSigTimeoutTime_HU_Mid_X451" SG_ 500 CCmHuSwitchStatusStuckWarn 0;
BA_ "GenSigTimeoutTime_HU_High_X451" SG_ 500 CCmHuSwitchStatusStuckWarn 0;
BA_ "GenSigTimeoutTime_HU_B" SG_ 500 CCmHuSwitchStatusStuckWarn 0;
BA_ "GenSigTimeoutTime_HU_A" SG_ 500 CCmHuSwitchStatusStuckWarn 0;
BA_ "GenSigTimeoutMsg_HU_Mid_X451" SG_ 500 CCmHuSwitchStatusStuckWarn 0;
BA_ "GenSigTimeoutMsg_HU_High_X451" SG_ 500 CCmHuSwitchStatusStuckWarn 0;
BA_ "GenSigTimeoutMsg_HU_B" SG_ 500 CCmHuSwitchStatusStuckWarn 0;
BA_ "GenSigTimeoutMsg_HU_A" SG_ 500 CCmHuSwitchStatusStuckWarn 0;
BA_ "GenSigSendType" SG_ 500 CCmHuSwitchStatusStuckWarn 1;
BA_ "GenSigTimeoutMsg_HU_High_X445" SG_ 500 CCmHuSwitchStatusStuckWarn 0;
BA_ "GenSigTimeoutMsg_HU_Mid_X445" SG_ 500 CCmHuSwitchStatusStuckWarn 0;
BA_ "GenSigTimeoutTime_HU_High_X445" SG_ 500 CCmHuSwitchStatusStuckWarn 0;
BA_ "GenSigTimeoutTime_HU_Mid_X445" SG_ 500 CCmHuSwitchStatusStuckWarn 0;
BA_ "GenSigTimeoutMsg_IVI" SG_ 500 CCmHuSwitchStatusStuckWarn 0;
BA_ "GenSigTimeoutTime_IVI" SG_ 500 CCmHuSwitchStatusStuckWarn 0;
BA_ "GenSigTimeoutTime_HU_Mid_X451" SG_ 500 CCmHuQueryFlag 0;
BA_ "GenSigTimeoutTime_HU_High_X451" SG_ 500 CCmHuQueryFlag 0;
BA_ "GenSigTimeoutTime_HU_B" SG_ 500 CCmHuQueryFlag 0;
BA_ "GenSigTimeoutTime_HU_A" SG_ 500 CCmHuQueryFlag 0;
BA_ "GenSigTimeoutMsg_HU_Mid_X451" SG_ 500 CCmHuQueryFlag 0;
BA_ "GenSigTimeoutMsg_HU_High_X451" SG_ 500 CCmHuQueryFlag 0;
BA_ "GenSigTimeoutMsg_HU_B" SG_ 500 CCmHuQueryFlag 0;
BA_ "GenSigTimeoutMsg_HU_A" SG_ 500 CCmHuQueryFlag 0;
BA_ "GenSigSendType" SG_ 500 CCmHuQueryFlag 1;
BA_ "GenSigTimeoutMsg_HU_High_X445" SG_ 500 CCmHuQueryFlag 0;
BA_ "GenSigTimeoutMsg_HU_Mid_X445" SG_ 500 CCmHuQueryFlag 0;
BA_ "GenSigTimeoutTime_HU_High_X445" SG_ 500 CCmHuQueryFlag 0;
BA_ "GenSigTimeoutTime_HU_Mid_X445" SG_ 500 CCmHuQueryFlag 0;
BA_ "GenSigTimeoutMsg_IVI" SG_ 500 CCmHuQueryFlag 0;
BA_ "GenSigTimeoutTime_IVI" SG_ 500 CCmHuQueryFlag 0;
BA_ "GenSigTimeoutTime_HU_Mid_X451" SG_ 500 CCmHuFanControlDuringVR 0;
BA_ "GenSigTimeoutTime_HU_High_X451" SG_ 500 CCmHuFanControlDuringVR 0;
BA_ "GenSigTimeoutTime_HU_B" SG_ 500 CCmHuFanControlDuringVR 0;
BA_ "GenSigTimeoutTime_HU_A" SG_ 500 CCmHuFanControlDuringVR 0;
BA_ "GenSigTimeoutMsg_HU_Mid_X451" SG_ 500 CCmHuFanControlDuringVR 0;
BA_ "GenSigTimeoutMsg_HU_High_X451" SG_ 500 CCmHuFanControlDuringVR 0;
BA_ "GenSigTimeoutMsg_HU_B" SG_ 500 CCmHuFanControlDuringVR 0;
BA_ "GenSigTimeoutMsg_HU_A" SG_ 500 CCmHuFanControlDuringVR 0;
BA_ "GenSigStartValue" SG_ 500 CCmHuFanControlDuringVR 1;
BA_ "GenSigSendType" SG_ 500 CCmHuFanControlDuringVR 1;
BA_ "GenSigTimeoutMsg_HU_High_X445" SG_ 500 CCmHuFanControlDuringVR 0;
BA_ "GenSigTimeoutMsg_HU_Mid_X445" SG_ 500 CCmHuFanControlDuringVR 0;
BA_ "GenSigTimeoutTime_HU_High_X445" SG_ 500 CCmHuFanControlDuringVR 0;
BA_ "GenSigTimeoutTime_HU_Mid_X445" SG_ 500 CCmHuFanControlDuringVR 0;
BA_ "GenSigTimeoutMsg_IVI" SG_ 500 CCmHuFanControlDuringVR 0;
BA_ "GenSigTimeoutTime_IVI" SG_ 500 CCmHuFanControlDuringVR 0;
BA_ "GenSigTimeoutTime_HU_Mid_X451" SG_ 504 BCmAutoRelockActiveSignalVal 0;
BA_ "GenSigTimeoutTime_HU_High_X451" SG_ 504 BCmAutoRelockActiveSignalVal 0;
BA_ "GenSigTimeoutTime_HU_B" SG_ 504 BCmAutoRelockActiveSignalVal 0;
BA_ "GenSigTimeoutTime_HU_A" SG_ 504 BCmAutoRelockActiveSignalVal 0;
BA_ "GenSigTimeoutMsg_HU_Mid_X451" SG_ 504 BCmAutoRelockActiveSignalVal 0;
BA_ "GenSigTimeoutMsg_HU_High_X451" SG_ 504 BCmAutoRelockActiveSignalVal 0;
BA_ "GenSigTimeoutMsg_HU_B" SG_ 504 BCmAutoRelockActiveSignalVal 0;
BA_ "GenSigTimeoutMsg_HU_A" SG_ 504 BCmAutoRelockActiveSignalVal 0;
BA_ "GenSigSendType" SG_ 504 BCmAutoRelockActiveSignalVal 1;
BA_ "GenSigTimeoutMsg_HU_High_X445" SG_ 504 BCmAutoRelockActiveSignalVal 0;
BA_ "GenSigTimeoutMsg_HU_Mid_X445" SG_ 504 BCmAutoRelockActiveSignalVal 0;
BA_ "GenSigTimeoutTime_HU_High_X445" SG_ 504 BCmAutoRelockActiveSignalVal 0;
BA_ "GenSigTimeoutTime_HU_Mid_X445" SG_ 504 BCmAutoRelockActiveSignalVal 0;
BA_ "GenSigTimeoutMsg_IVI" SG_ 504 BCmAutoRelockActiveSignalVal 0;
BA_ "GenSigTimeoutTime_IVI" SG_ 504 BCmAutoRelockActiveSignalVal 0;
BA_ "GenSigTimeoutTime_HU_Mid_X451" SG_ 504 BCmFMhActiveSignalVal 0;
BA_ "GenSigTimeoutTime_HU_High_X451" SG_ 504 BCmFMhActiveSignalVal 0;
BA_ "GenSigTimeoutTime_HU_B" SG_ 504 BCmFMhActiveSignalVal 0;
BA_ "GenSigTimeoutTime_HU_A" SG_ 504 BCmFMhActiveSignalVal 0;
BA_ "GenSigTimeoutMsg_HU_Mid_X451" SG_ 504 BCmFMhActiveSignalVal 0;
BA_ "GenSigTimeoutMsg_HU_High_X451" SG_ 504 BCmFMhActiveSignalVal 0;
BA_ "GenSigTimeoutMsg_HU_B" SG_ 504 BCmFMhActiveSignalVal 0;
BA_ "GenSigTimeoutMsg_HU_A" SG_ 504 BCmFMhActiveSignalVal 0;
BA_ "GenSigStartValue" SG_ 504 BCmFMhActiveSignalVal 1;
BA_ "GenSigSendType" SG_ 504 BCmFMhActiveSignalVal 1;
BA_ "GenSigTimeoutMsg_HU_High_X445" SG_ 504 BCmFMhActiveSignalVal 0;
BA_ "GenSigTimeoutMsg_HU_Mid_X445" SG_ 504 BCmFMhActiveSignalVal 0;
BA_ "GenSigTimeoutTime_HU_High_X445" SG_ 504 BCmFMhActiveSignalVal 0;
BA_ "GenSigTimeoutTime_HU_Mid_X445" SG_ 504 BCmFMhActiveSignalVal 0;
BA_ "GenSigTimeoutMsg_IVI" SG_ 504 BCmFMhActiveSignalVal 0;
BA_ "GenSigTimeoutTime_IVI" SG_ 504 BCmFMhActiveSignalVal 0;
BA_ "GenSigTimeoutTime_HU_Mid_X451" SG_ 504 BCmFMhSignalVal1 0;
BA_ "GenSigTimeoutTime_HU_High_X451" SG_ 504 BCmFMhSignalVal1 0;
BA_ "GenSigTimeoutTime_HU_B" SG_ 504 BCmFMhSignalVal1 0;
BA_ "GenSigTimeoutTime_HU_A" SG_ 504 BCmFMhSignalVal1 0;
BA_ "GenSigTimeoutMsg_HU_Mid_X451" SG_ 504 BCmFMhSignalVal1 0;
BA_ "GenSigTimeoutMsg_HU_High_X451" SG_ 504 BCmFMhSignalVal1 0;
BA_ "GenSigTimeoutMsg_HU_B" SG_ 504 BCmFMhSignalVal1 0;
BA_ "GenSigTimeoutMsg_HU_A" SG_ 504 BCmFMhSignalVal1 0;
BA_ "GenSigStartValue" SG_ 504 BCmFMhSignalVal1 3;
BA_ "GenSigSendType" SG_ 504 BCmFMhSignalVal1 1;
BA_ "GenSigTimeoutMsg_HU_High_X445" SG_ 504 BCmFMhSignalVal1 0;
BA_ "GenSigTimeoutMsg_HU_Mid_X445" SG_ 504 BCmFMhSignalVal1 0;
BA_ "GenSigTimeoutTime_HU_High_X445" SG_ 504 BCmFMhSignalVal1 0;
BA_ "GenSigTimeoutTime_HU_Mid_X445" SG_ 504 BCmFMhSignalVal1 0;
BA_ "GenSigTimeoutMsg_IVI" SG_ 504 BCmFMhSignalVal1 0;
BA_ "GenSigTimeoutTime_IVI" SG_ 504 BCmFMhSignalVal1 0;
BA_ "GenSigTimeoutTime_HU_Mid_X451" SG_ 504 BCmVehLockHornReqActiveSignalVal 0;
BA_ "GenSigTimeoutTime_HU_High_X451" SG_ 504 BCmVehLockHornReqActiveSignalVal 0;
BA_ "GenSigTimeoutTime_HU_B" SG_ 504 BCmVehLockHornReqActiveSignalVal 0;
BA_ "GenSigTimeoutTime_HU_A" SG_ 504 BCmVehLockHornReqActiveSignalVal 0;
BA_ "GenSigTimeoutMsg_HU_Mid_X451" SG_ 504 BCmVehLockHornReqActiveSignalVal 0;
BA_ "GenSigTimeoutMsg_HU_High_X451" SG_ 504 BCmVehLockHornReqActiveSignalVal 0;
BA_ "GenSigTimeoutMsg_HU_B" SG_ 504 BCmVehLockHornReqActiveSignalVal 0;
BA_ "GenSigTimeoutMsg_HU_A" SG_ 504 BCmVehLockHornReqActiveSignalVal 0;
BA_ "GenSigSendType" SG_ 504 BCmVehLockHornReqActiveSignalVal 1;
BA_ "GenSigTimeoutMsg_HU_High_X445" SG_ 504 BCmVehLockHornReqActiveSignalVal 0;
BA_ "GenSigTimeoutMsg_HU_Mid_X445" SG_ 504 BCmVehLockHornReqActiveSignalVal 0;
BA_ "GenSigTimeoutTime_HU_High_X445" SG_ 504 BCmVehLockHornReqActiveSignalVal 0;
BA_ "GenSigTimeoutTime_HU_Mid_X445" SG_ 504 BCmVehLockHornReqActiveSignalVal 0;
BA_ "GenSigTimeoutMsg_IVI" SG_ 504 BCmVehLockHornReqActiveSignalVal 0;
BA_ "GenSigTimeoutTime_IVI" SG_ 504 BCmVehLockHornReqActiveSignalVal 0;
BA_ "GenSigTimeoutTime_HU_Mid_X451" SG_ 504 BCmApproachLampActiveSignalVal 0;
BA_ "GenSigTimeoutTime_HU_High_X451" SG_ 504 BCmApproachLampActiveSignalVal 0;
BA_ "GenSigTimeoutTime_HU_B" SG_ 504 BCmApproachLampActiveSignalVal 0;
BA_ "GenSigTimeoutTime_HU_A" SG_ 504 BCmApproachLampActiveSignalVal 0;
BA_ "GenSigTimeoutMsg_HU_Mid_X451" SG_ 504 BCmApproachLampActiveSignalVal 0;
BA_ "GenSigTimeoutMsg_HU_High_X451" SG_ 504 BCmApproachLampActiveSignalVal 0;
BA_ "GenSigTimeoutMsg_HU_B" SG_ 504 BCmApproachLampActiveSignalVal 0;
BA_ "GenSigTimeoutMsg_HU_A" SG_ 504 BCmApproachLampActiveSignalVal 0;
BA_ "GenSigStartValue" SG_ 504 BCmApproachLampActiveSignalVal 1;
BA_ "GenSigSendType" SG_ 504 BCmApproachLampActiveSignalVal 1;
BA_ "GenSigTimeoutMsg_HU_High_X445" SG_ 504 BCmApproachLampActiveSignalVal 0;
BA_ "GenSigTimeoutMsg_HU_Mid_X445" SG_ 504 BCmApproachLampActiveSignalVal 0;
BA_ "GenSigTimeoutTime_HU_High_X445" SG_ 504 BCmApproachLampActiveSignalVal 0;
BA_ "GenSigTimeoutTime_HU_Mid_X445" SG_ 504 BCmApproachLampActiveSignalVal 0;
BA_ "GenSigTimeoutMsg_IVI" SG_ 504 BCmApproachLampActiveSignalVal 0;
BA_ "GenSigTimeoutTime_IVI" SG_ 504 BCmApproachLampActiveSignalVal 0;
BA_ "GenSigTimeoutTime_HU_Mid_X451" SG_ 504 BCmFMhSignalVal2 0;
BA_ "GenSigTimeoutTime_HU_High_X451" SG_ 504 BCmFMhSignalVal2 0;
BA_ "GenSigTimeoutTime_HU_B" SG_ 504 BCmFMhSignalVal2 0;
BA_ "GenSigTimeoutTime_HU_A" SG_ 504 BCmFMhSignalVal2 0;
BA_ "GenSigTimeoutMsg_HU_Mid_X451" SG_ 504 BCmFMhSignalVal2 0;
BA_ "GenSigTimeoutMsg_HU_High_X451" SG_ 504 BCmFMhSignalVal2 0;
BA_ "GenSigTimeoutMsg_HU_B" SG_ 504 BCmFMhSignalVal2 0;
BA_ "GenSigTimeoutMsg_HU_A" SG_ 504 BCmFMhSignalVal2 0;
BA_ "GenSigStartValue" SG_ 504 BCmFMhSignalVal2 6;
BA_ "GenSigSendType" SG_ 504 BCmFMhSignalVal2 1;
BA_ "GenSigTimeoutMsg_HU_High_X445" SG_ 504 BCmFMhSignalVal2 0;
BA_ "GenSigTimeoutMsg_HU_Mid_X445" SG_ 504 BCmFMhSignalVal2 0;
BA_ "GenSigTimeoutTime_HU_High_X445" SG_ 504 BCmFMhSignalVal2 0;
BA_ "GenSigTimeoutTime_HU_Mid_X445" SG_ 504 BCmFMhSignalVal2 0;
BA_ "GenSigTimeoutMsg_IVI" SG_ 504 BCmFMhSignalVal2 0;
BA_ "GenSigTimeoutTime_IVI" SG_ 504 BCmFMhSignalVal2 0;
BA_ "GenSigTimeoutTime_HU_Mid_X451" SG_ 504 BCmDriveAwayLockingActiveSignalV 0;
BA_ "GenSigTimeoutTime_HU_High_X451" SG_ 504 BCmDriveAwayLockingActiveSignalV 0;
BA_ "GenSigTimeoutTime_HU_B" SG_ 504 BCmDriveAwayLockingActiveSignalV 0;
BA_ "GenSigTimeoutTime_HU_A" SG_ 504 BCmDriveAwayLockingActiveSignalV 0;
BA_ "GenSigTimeoutMsg_HU_Mid_X451" SG_ 504 BCmDriveAwayLockingActiveSignalV 0;
BA_ "GenSigTimeoutMsg_HU_High_X451" SG_ 504 BCmDriveAwayLockingActiveSignalV 0;
BA_ "GenSigTimeoutMsg_HU_B" SG_ 504 BCmDriveAwayLockingActiveSignalV 0;
BA_ "GenSigTimeoutMsg_HU_A" SG_ 504 BCmDriveAwayLockingActiveSignalV 0;
BA_ "GenSigSendType" SG_ 504 BCmDriveAwayLockingActiveSignalV 1;
BA_ "GenSigTimeoutMsg_HU_High_X445" SG_ 504 BCmDriveAwayLockingActiveSignalV 0;
BA_ "GenSigTimeoutMsg_HU_Mid_X445" SG_ 504 BCmDriveAwayLockingActiveSignalV 0;
BA_ "GenSigTimeoutTime_HU_High_X445" SG_ 504 BCmDriveAwayLockingActiveSignalV 0;
BA_ "GenSigTimeoutTime_HU_Mid_X445" SG_ 504 BCmDriveAwayLockingActiveSignalV 0;
BA_ "GenSigTimeoutMsg_IVI" SG_ 504 BCmDriveAwayLockingActiveSignalV 0;
BA_ "GenSigTimeoutTime_IVI" SG_ 504 BCmDriveAwayLockingActiveSignalV 0;
BA_ "SystemSignalLongSymbol" SG_ 504 BCmDriveAwayLockingActiveSignalV "BCmDriveAwayLockingActiveSignalVal";
BA_ "GenSigTimeoutTime_HU_Mid_X451" SG_ 504 BCmRKeUnlockState 0;
BA_ "GenSigTimeoutTime_HU_High_X451" SG_ 504 BCmRKeUnlockState 0;
BA_ "GenSigTimeoutTime_HU_B" SG_ 504 BCmRKeUnlockState 0;
BA_ "GenSigTimeoutTime_HU_A" SG_ 504 BCmRKeUnlockState 0;
BA_ "GenSigTimeoutMsg_HU_Mid_X451" SG_ 504 BCmRKeUnlockState 0;
BA_ "GenSigTimeoutMsg_HU_High_X451" SG_ 504 BCmRKeUnlockState 0;
BA_ "GenSigTimeoutMsg_HU_B" SG_ 504 BCmRKeUnlockState 0;
BA_ "GenSigTimeoutMsg_HU_A" SG_ 504 BCmRKeUnlockState 0;
BA_ "GenSigSendType" SG_ 504 BCmRKeUnlockState 1;
BA_ "GenSigTimeoutMsg_HU_High_X445" SG_ 504 BCmRKeUnlockState 0;
BA_ "GenSigTimeoutMsg_HU_Mid_X445" SG_ 504 BCmRKeUnlockState 0;
BA_ "GenSigTimeoutTime_HU_High_X445" SG_ 504 BCmRKeUnlockState 0;
BA_ "GenSigTimeoutTime_HU_Mid_X445" SG_ 504 BCmRKeUnlockState 0;
BA_ "GenSigTimeoutMsg_IVI" SG_ 504 BCmRKeUnlockState 0;
BA_ "GenSigTimeoutTime_IVI" SG_ 504 BCmRKeUnlockState 0;
BA_ "GenSigTimeoutTime_HU_Mid_X451" SG_ 504 BCmPKeUnlockState 0;
BA_ "GenSigTimeoutTime_HU_High_X451" SG_ 504 BCmPKeUnlockState 0;
BA_ "GenSigTimeoutTime_HU_B" SG_ 504 BCmPKeUnlockState 0;
BA_ "GenSigTimeoutTime_HU_A" SG_ 504 BCmPKeUnlockState 0;
BA_ "GenSigTimeoutMsg_HU_Mid_X451" SG_ 504 BCmPKeUnlockState 0;
BA_ "GenSigTimeoutMsg_HU_High_X451" SG_ 504 BCmPKeUnlockState 0;
BA_ "GenSigTimeoutMsg_HU_B" SG_ 504 BCmPKeUnlockState 0;
BA_ "GenSigTimeoutMsg_HU_A" SG_ 504 BCmPKeUnlockState 0;
BA_ "GenSigSendType" SG_ 504 BCmPKeUnlockState 1;
BA_ "GenSigTimeoutMsg_HU_High_X445" SG_ 504 BCmPKeUnlockState 0;
BA_ "GenSigTimeoutMsg_HU_Mid_X445" SG_ 504 BCmPKeUnlockState 0;
BA_ "GenSigTimeoutTime_HU_High_X445" SG_ 504 BCmPKeUnlockState 0;
BA_ "GenSigTimeoutTime_HU_Mid_X445" SG_ 504 BCmPKeUnlockState 0;
BA_ "GenSigTimeoutMsg_IVI" SG_ 504 BCmPKeUnlockState 0;
BA_ "GenSigTimeoutTime_IVI" SG_ 504 BCmPKeUnlockState 0;
BA_ "GenSigTimeoutTime_HU_Mid_X451" SG_ 504 BCmFMhSignalVal3 0;
BA_ "GenSigTimeoutTime_HU_High_X451" SG_ 504 BCmFMhSignalVal3 0;
BA_ "GenSigTimeoutTime_HU_B" SG_ 504 BCmFMhSignalVal3 0;
BA_ "GenSigTimeoutTime_HU_A" SG_ 504 BCmFMhSignalVal3 0;
BA_ "GenSigTimeoutMsg_HU_Mid_X451" SG_ 504 BCmFMhSignalVal3 0;
BA_ "GenSigTimeoutMsg_HU_High_X451" SG_ 504 BCmFMhSignalVal3 0;
BA_ "GenSigTimeoutMsg_HU_B" SG_ 504 BCmFMhSignalVal3 0;
BA_ "GenSigTimeoutMsg_HU_A" SG_ 504 BCmFMhSignalVal3 0;
BA_ "GenSigStartValue" SG_ 504 BCmFMhSignalVal3 12;
BA_ "GenSigSendType" SG_ 504 BCmFMhSignalVal3 1;
BA_ "GenSigTimeoutMsg_HU_High_X445" SG_ 504 BCmFMhSignalVal3 0;
BA_ "GenSigTimeoutMsg_HU_Mid_X445" SG_ 504 BCmFMhSignalVal3 0;
BA_ "GenSigTimeoutTime_HU_High_X445" SG_ 504 BCmFMhSignalVal3 0;
BA_ "GenSigTimeoutTime_HU_Mid_X445" SG_ 504 BCmFMhSignalVal3 0;
BA_ "GenSigTimeoutMsg_IVI" SG_ 504 BCmFMhSignalVal3 0;
BA_ "GenSigTimeoutTime_IVI" SG_ 504 BCmFMhSignalVal3 0;
BA_ "GenSigTimeoutTime_HU_Mid_X451" SG_ 504 BCmAutoRelockState 0;
BA_ "GenSigTimeoutTime_HU_High_X451" SG_ 504 BCmAutoRelockState 0;
BA_ "GenSigTimeoutTime_HU_B" SG_ 504 BCmAutoRelockState 0;
BA_ "GenSigTimeoutTime_HU_A" SG_ 504 BCmAutoRelockState 0;
BA_ "GenSigTimeoutMsg_HU_Mid_X451" SG_ 504 BCmAutoRelockState 0;
BA_ "GenSigTimeoutMsg_HU_High_X451" SG_ 504 BCmAutoRelockState 0;
BA_ "GenSigTimeoutMsg_HU_B" SG_ 504 BCmAutoRelockState 0;
BA_ "GenSigTimeoutMsg_HU_A" SG_ 504 BCmAutoRelockState 0;
BA_ "GenSigSendType" SG_ 504 BCmAutoRelockState 1;
BA_ "GenSigTimeoutMsg_HU_High_X445" SG_ 504 BCmAutoRelockState 0;
BA_ "GenSigTimeoutMsg_HU_Mid_X445" SG_ 504 BCmAutoRelockState 0;
BA_ "GenSigTimeoutTime_HU_High_X445" SG_ 504 BCmAutoRelockState 0;
BA_ "GenSigTimeoutTime_HU_Mid_X445" SG_ 504 BCmAutoRelockState 0;
BA_ "GenSigTimeoutMsg_IVI" SG_ 504 BCmAutoRelockState 0;
BA_ "GenSigTimeoutTime_IVI" SG_ 504 BCmAutoRelockState 0;
BA_ "GenSigTimeoutTime_HU_Mid_X451" SG_ 504 BCmFMhState 0;
BA_ "GenSigTimeoutTime_HU_High_X451" SG_ 504 BCmFMhState 0;
BA_ "GenSigTimeoutTime_HU_B" SG_ 504 BCmFMhState 0;
BA_ "GenSigTimeoutTime_HU_A" SG_ 504 BCmFMhState 0;
BA_ "GenSigTimeoutMsg_HU_Mid_X451" SG_ 504 BCmFMhState 0;
BA_ "GenSigTimeoutMsg_HU_High_X451" SG_ 504 BCmFMhState 0;
BA_ "GenSigTimeoutMsg_HU_B" SG_ 504 BCmFMhState 0;
BA_ "GenSigTimeoutMsg_HU_A" SG_ 504 BCmFMhState 0;
BA_ "GenSigSendType" SG_ 504 BCmFMhState 1;
BA_ "GenSigTimeoutMsg_HU_High_X445" SG_ 504 BCmFMhState 0;
BA_ "GenSigTimeoutMsg_HU_Mid_X445" SG_ 504 BCmFMhState 0;
BA_ "GenSigTimeoutTime_HU_High_X445" SG_ 504 BCmFMhState 0;
BA_ "GenSigTimeoutTime_HU_Mid_X445" SG_ 504 BCmFMhState 0;
BA_ "GenSigTimeoutMsg_IVI" SG_ 504 BCmFMhState 0;
BA_ "GenSigTimeoutTime_IVI" SG_ 504 BCmFMhState 0;
BA_ "GenSigTimeoutTime_HU_Mid_X451" SG_ 504 BCmUCsState 0;
BA_ "GenSigTimeoutTime_HU_High_X451" SG_ 504 BCmUCsState 0;
BA_ "GenSigTimeoutTime_HU_B" SG_ 504 BCmUCsState 0;
BA_ "GenSigTimeoutTime_HU_A" SG_ 504 BCmUCsState 0;
BA_ "GenSigTimeoutMsg_HU_Mid_X451" SG_ 504 BCmUCsState 0;
BA_ "GenSigTimeoutMsg_HU_High_X451" SG_ 504 BCmUCsState 0;
BA_ "GenSigTimeoutMsg_HU_B" SG_ 504 BCmUCsState 0;
BA_ "GenSigTimeoutMsg_HU_A" SG_ 504 BCmUCsState 0;
BA_ "GenSigSendType" SG_ 504 BCmUCsState 1;
BA_ "GenSigTimeoutMsg_HU_High_X445" SG_ 504 BCmUCsState 0;
BA_ "GenSigTimeoutMsg_HU_Mid_X445" SG_ 504 BCmUCsState 0;
BA_ "GenSigTimeoutTime_HU_High_X445" SG_ 504 BCmUCsState 0;
BA_ "GenSigTimeoutTime_HU_Mid_X445" SG_ 504 BCmUCsState 0;
BA_ "GenSigTimeoutMsg_IVI" SG_ 504 BCmUCsState 0;
BA_ "GenSigTimeoutTime_IVI" SG_ 504 BCmUCsState 0;
BA_ "GenSigTimeoutTime_HU_Mid_X451" SG_ 504 BCmApproachLampSignalVal1 0;
BA_ "GenSigTimeoutTime_HU_High_X451" SG_ 504 BCmApproachLampSignalVal1 0;
BA_ "GenSigTimeoutTime_HU_B" SG_ 504 BCmApproachLampSignalVal1 0;
BA_ "GenSigTimeoutTime_HU_A" SG_ 504 BCmApproachLampSignalVal1 0;
BA_ "GenSigTimeoutMsg_HU_Mid_X451" SG_ 504 BCmApproachLampSignalVal1 0;
BA_ "GenSigTimeoutMsg_HU_High_X451" SG_ 504 BCmApproachLampSignalVal1 0;
BA_ "GenSigTimeoutMsg_HU_B" SG_ 504 BCmApproachLampSignalVal1 0;
BA_ "GenSigTimeoutMsg_HU_A" SG_ 504 BCmApproachLampSignalVal1 0;
BA_ "GenSigStartValue" SG_ 504 BCmApproachLampSignalVal1 3;
BA_ "GenSigSendType" SG_ 504 BCmApproachLampSignalVal1 1;
BA_ "GenSigTimeoutMsg_HU_High_X445" SG_ 504 BCmApproachLampSignalVal1 0;
BA_ "GenSigTimeoutMsg_HU_Mid_X445" SG_ 504 BCmApproachLampSignalVal1 0;
BA_ "GenSigTimeoutTime_HU_High_X445" SG_ 504 BCmApproachLampSignalVal1 0;
BA_ "GenSigTimeoutTime_HU_Mid_X445" SG_ 504 BCmApproachLampSignalVal1 0;
BA_ "GenSigTimeoutMsg_IVI" SG_ 504 BCmApproachLampSignalVal1 0;
BA_ "GenSigTimeoutTime_IVI" SG_ 504 BCmApproachLampSignalVal1 0;
BA_ "GenSigTimeoutTime_HU_Mid_X451" SG_ 504 BCmPKeUnlockActiveSignalVal 0;
BA_ "GenSigTimeoutTime_HU_High_X451" SG_ 504 BCmPKeUnlockActiveSignalVal 0;
BA_ "GenSigTimeoutTime_HU_B" SG_ 504 BCmPKeUnlockActiveSignalVal 0;
BA_ "GenSigTimeoutTime_HU_A" SG_ 504 BCmPKeUnlockActiveSignalVal 0;
BA_ "GenSigTimeoutMsg_HU_Mid_X451" SG_ 504 BCmPKeUnlockActiveSignalVal 0;
BA_ "GenSigTimeoutMsg_HU_High_X451" SG_ 504 BCmPKeUnlockActiveSignalVal 0;
BA_ "GenSigTimeoutMsg_HU_B" SG_ 504 BCmPKeUnlockActiveSignalVal 0;
BA_ "GenSigTimeoutMsg_HU_A" SG_ 504 BCmPKeUnlockActiveSignalVal 0;
BA_ "GenSigSendType" SG_ 504 BCmPKeUnlockActiveSignalVal 1;
BA_ "GenSigTimeoutMsg_HU_High_X445" SG_ 504 BCmPKeUnlockActiveSignalVal 0;
BA_ "GenSigTimeoutMsg_HU_Mid_X445" SG_ 504 BCmPKeUnlockActiveSignalVal 0;
BA_ "GenSigTimeoutTime_HU_High_X445" SG_ 504 BCmPKeUnlockActiveSignalVal 0;
BA_ "GenSigTimeoutTime_HU_Mid_X445" SG_ 504 BCmPKeUnlockActiveSignalVal 0;
BA_ "GenSigTimeoutMsg_IVI" SG_ 504 BCmPKeUnlockActiveSignalVal 0;
BA_ "GenSigTimeoutTime_IVI" SG_ 504 BCmPKeUnlockActiveSignalVal 0;
BA_ "GenSigTimeoutTime_HU_Mid_X451" SG_ 504 BCmRKeUnlockActiveSignalVal 0;
BA_ "GenSigTimeoutTime_HU_High_X451" SG_ 504 BCmRKeUnlockActiveSignalVal 0;
BA_ "GenSigTimeoutTime_HU_B" SG_ 504 BCmRKeUnlockActiveSignalVal 0;
BA_ "GenSigTimeoutTime_HU_A" SG_ 504 BCmRKeUnlockActiveSignalVal 0;
BA_ "GenSigTimeoutMsg_HU_Mid_X451" SG_ 504 BCmRKeUnlockActiveSignalVal 0;
BA_ "GenSigTimeoutMsg_HU_High_X451" SG_ 504 BCmRKeUnlockActiveSignalVal 0;
BA_ "GenSigTimeoutMsg_HU_B" SG_ 504 BCmRKeUnlockActiveSignalVal 0;
BA_ "GenSigTimeoutMsg_HU_A" SG_ 504 BCmRKeUnlockActiveSignalVal 0;
BA_ "GenSigSendType" SG_ 504 BCmRKeUnlockActiveSignalVal 1;
BA_ "GenSigTimeoutMsg_HU_High_X445" SG_ 504 BCmRKeUnlockActiveSignalVal 0;
BA_ "GenSigTimeoutMsg_HU_Mid_X445" SG_ 504 BCmRKeUnlockActiveSignalVal 0;
BA_ "GenSigTimeoutTime_HU_High_X445" SG_ 504 BCmRKeUnlockActiveSignalVal 0;
BA_ "GenSigTimeoutTime_HU_Mid_X445" SG_ 504 BCmRKeUnlockActiveSignalVal 0;
BA_ "GenSigTimeoutMsg_IVI" SG_ 504 BCmRKeUnlockActiveSignalVal 0;
BA_ "GenSigTimeoutTime_IVI" SG_ 504 BCmRKeUnlockActiveSignalVal 0;
BA_ "GenSigTimeoutTime_HU_Mid_X451" SG_ 504 BCmDriveAwayLockingState 0;
BA_ "GenSigTimeoutTime_HU_High_X451" SG_ 504 BCmDriveAwayLockingState 0;
BA_ "GenSigTimeoutTime_HU_B" SG_ 504 BCmDriveAwayLockingState 0;
BA_ "GenSigTimeoutTime_HU_A" SG_ 504 BCmDriveAwayLockingState 0;
BA_ "GenSigTimeoutMsg_HU_Mid_X451" SG_ 504 BCmDriveAwayLockingState 0;
BA_ "GenSigTimeoutMsg_HU_High_X451" SG_ 504 BCmDriveAwayLockingState 0;
BA_ "GenSigTimeoutMsg_HU_B" SG_ 504 BCmDriveAwayLockingState 0;
BA_ "GenSigTimeoutMsg_HU_A" SG_ 504 BCmDriveAwayLockingState 0;
BA_ "GenSigSendType" SG_ 504 BCmDriveAwayLockingState 1;
BA_ "GenSigTimeoutMsg_HU_High_X445" SG_ 504 BCmDriveAwayLockingState 0;
BA_ "GenSigTimeoutMsg_HU_Mid_X445" SG_ 504 BCmDriveAwayLockingState 0;
BA_ "GenSigTimeoutTime_HU_High_X445" SG_ 504 BCmDriveAwayLockingState 0;
BA_ "GenSigTimeoutTime_HU_Mid_X445" SG_ 504 BCmDriveAwayLockingState 0;
BA_ "GenSigTimeoutMsg_IVI" SG_ 504 BCmDriveAwayLockingState 0;
BA_ "GenSigTimeoutTime_IVI" SG_ 504 BCmDriveAwayLockingState 0;
BA_ "GenSigTimeoutTime_HU_Mid_X451" SG_ 504 BCmApproachLampSignalVal2 0;
BA_ "GenSigTimeoutTime_HU_High_X451" SG_ 504 BCmApproachLampSignalVal2 0;
BA_ "GenSigTimeoutTime_HU_B" SG_ 504 BCmApproachLampSignalVal2 0;
BA_ "GenSigTimeoutTime_HU_A" SG_ 504 BCmApproachLampSignalVal2 0;
BA_ "GenSigTimeoutMsg_HU_Mid_X451" SG_ 504 BCmApproachLampSignalVal2 0;
BA_ "GenSigTimeoutMsg_HU_High_X451" SG_ 504 BCmApproachLampSignalVal2 0;
BA_ "GenSigTimeoutMsg_HU_B" SG_ 504 BCmApproachLampSignalVal2 0;
BA_ "GenSigTimeoutMsg_HU_A" SG_ 504 BCmApproachLampSignalVal2 0;
BA_ "GenSigStartValue" SG_ 504 BCmApproachLampSignalVal2 6;
BA_ "GenSigSendType" SG_ 504 BCmApproachLampSignalVal2 1;
BA_ "GenSigTimeoutMsg_HU_High_X445" SG_ 504 BCmApproachLampSignalVal2 0;
BA_ "GenSigTimeoutMsg_HU_Mid_X445" SG_ 504 BCmApproachLampSignalVal2 0;
BA_ "GenSigTimeoutTime_HU_High_X445" SG_ 504 BCmApproachLampSignalVal2 0;
BA_ "GenSigTimeoutTime_HU_Mid_X445" SG_ 504 BCmApproachLampSignalVal2 0;
BA_ "GenSigTimeoutMsg_IVI" SG_ 504 BCmApproachLampSignalVal2 0;
BA_ "GenSigTimeoutTime_IVI" SG_ 504 BCmApproachLampSignalVal2 0;
BA_ "GenSigTimeoutTime_HU_Mid_X451" SG_ 504 AmbLightModeIllumOnHu 0;
BA_ "GenSigTimeoutTime_HU_High_X451" SG_ 504 AmbLightModeIllumOnHu 0;
BA_ "GenSigTimeoutTime_HU_B" SG_ 504 AmbLightModeIllumOnHu 0;
BA_ "GenSigTimeoutTime_HU_A" SG_ 504 AmbLightModeIllumOnHu 0;
BA_ "GenSigTimeoutMsg_HU_Mid_X451" SG_ 504 AmbLightModeIllumOnHu 0;
BA_ "GenSigTimeoutMsg_HU_High_X451" SG_ 504 AmbLightModeIllumOnHu 0;
BA_ "GenSigTimeoutMsg_HU_B" SG_ 504 AmbLightModeIllumOnHu 0;
BA_ "GenSigTimeoutMsg_HU_A" SG_ 504 AmbLightModeIllumOnHu 0;
BA_ "GenSigSendType" SG_ 504 AmbLightModeIllumOnHu 1;
BA_ "GenSigTimeoutMsg_HU_High_X445" SG_ 504 AmbLightModeIllumOnHu 0;
BA_ "GenSigTimeoutMsg_HU_Mid_X445" SG_ 504 AmbLightModeIllumOnHu 0;
BA_ "GenSigTimeoutTime_HU_High_X445" SG_ 504 AmbLightModeIllumOnHu 0;
BA_ "GenSigTimeoutTime_HU_Mid_X445" SG_ 504 AmbLightModeIllumOnHu 0;
BA_ "GenSigTimeoutMsg_IVI" SG_ 504 AmbLightModeIllumOnHu 0;
BA_ "GenSigTimeoutTime_IVI" SG_ 504 AmbLightModeIllumOnHu 0;
BA_ "GenSigTimeoutTime_HU_Mid_X451" SG_ 504 BCmApproachLampState 0;
BA_ "GenSigTimeoutTime_HU_High_X451" SG_ 504 BCmApproachLampState 0;
BA_ "GenSigTimeoutTime_HU_B" SG_ 504 BCmApproachLampState 0;
BA_ "GenSigTimeoutTime_HU_A" SG_ 504 BCmApproachLampState 0;
BA_ "GenSigTimeoutMsg_HU_Mid_X451" SG_ 504 BCmApproachLampState 0;
BA_ "GenSigTimeoutMsg_HU_High_X451" SG_ 504 BCmApproachLampState 0;
BA_ "GenSigTimeoutMsg_HU_B" SG_ 504 BCmApproachLampState 0;
BA_ "GenSigTimeoutMsg_HU_A" SG_ 504 BCmApproachLampState 0;
BA_ "GenSigSendType" SG_ 504 BCmApproachLampState 1;
BA_ "GenSigTimeoutMsg_HU_High_X445" SG_ 504 BCmApproachLampState 0;
BA_ "GenSigTimeoutMsg_HU_Mid_X445" SG_ 504 BCmApproachLampState 0;
BA_ "GenSigTimeoutTime_HU_High_X445" SG_ 504 BCmApproachLampState 0;
BA_ "GenSigTimeoutTime_HU_Mid_X445" SG_ 504 BCmApproachLampState 0;
BA_ "GenSigTimeoutMsg_IVI" SG_ 504 BCmApproachLampState 0;
BA_ "GenSigTimeoutTime_IVI" SG_ 504 BCmApproachLampState 0;
BA_ "GenSigTimeoutTime_HU_Mid_X451" SG_ 504 BCmVehLockHornReqState 0;
BA_ "GenSigTimeoutTime_HU_High_X451" SG_ 504 BCmVehLockHornReqState 0;
BA_ "GenSigTimeoutTime_HU_B" SG_ 504 BCmVehLockHornReqState 0;
BA_ "GenSigTimeoutTime_HU_A" SG_ 504 BCmVehLockHornReqState 0;
BA_ "GenSigTimeoutMsg_HU_Mid_X451" SG_ 504 BCmVehLockHornReqState 0;
BA_ "GenSigTimeoutMsg_HU_High_X451" SG_ 504 BCmVehLockHornReqState 0;
BA_ "GenSigTimeoutMsg_HU_B" SG_ 504 BCmVehLockHornReqState 0;
BA_ "GenSigTimeoutMsg_HU_A" SG_ 504 BCmVehLockHornReqState 0;
BA_ "GenSigSendType" SG_ 504 BCmVehLockHornReqState 1;
BA_ "GenSigTimeoutMsg_HU_High_X445" SG_ 504 BCmVehLockHornReqState 0;
BA_ "GenSigTimeoutMsg_HU_Mid_X445" SG_ 504 BCmVehLockHornReqState 0;
BA_ "GenSigTimeoutTime_HU_High_X445" SG_ 504 BCmVehLockHornReqState 0;
BA_ "GenSigTimeoutTime_HU_Mid_X445" SG_ 504 BCmVehLockHornReqState 0;
BA_ "GenSigTimeoutMsg_IVI" SG_ 504 BCmVehLockHornReqState 0;
BA_ "GenSigTimeoutTime_IVI" SG_ 504 BCmVehLockHornReqState 0;
BA_ "GenSigTimeoutTime_HU_Mid_X451" SG_ 504 BCmApproachLampSignalVal3 0;
BA_ "GenSigTimeoutTime_HU_High_X451" SG_ 504 BCmApproachLampSignalVal3 0;
BA_ "GenSigTimeoutTime_HU_B" SG_ 504 BCmApproachLampSignalVal3 0;
BA_ "GenSigTimeoutTime_HU_A" SG_ 504 BCmApproachLampSignalVal3 0;
BA_ "GenSigTimeoutMsg_HU_Mid_X451" SG_ 504 BCmApproachLampSignalVal3 0;
BA_ "GenSigTimeoutMsg_HU_High_X451" SG_ 504 BCmApproachLampSignalVal3 0;
BA_ "GenSigTimeoutMsg_HU_B" SG_ 504 BCmApproachLampSignalVal3 0;
BA_ "GenSigTimeoutMsg_HU_A" SG_ 504 BCmApproachLampSignalVal3 0;
BA_ "GenSigStartValue" SG_ 504 BCmApproachLampSignalVal3 9;
BA_ "GenSigSendType" SG_ 504 BCmApproachLampSignalVal3 1;
BA_ "GenSigTimeoutMsg_HU_High_X445" SG_ 504 BCmApproachLampSignalVal3 0;
BA_ "GenSigTimeoutMsg_HU_Mid_X445" SG_ 504 BCmApproachLampSignalVal3 0;
BA_ "GenSigTimeoutTime_HU_High_X445" SG_ 504 BCmApproachLampSignalVal3 0;
BA_ "GenSigTimeoutTime_HU_Mid_X445" SG_ 504 BCmApproachLampSignalVal3 0;
BA_ "GenSigTimeoutMsg_IVI" SG_ 504 BCmApproachLampSignalVal3 0;
BA_ "GenSigTimeoutTime_IVI" SG_ 504 BCmApproachLampSignalVal3 0;
BA_ "GenSigTimeoutTime_HU_Mid_X451" SG_ 504 BCmDRLActiveSignalVal 0;
BA_ "GenSigTimeoutTime_HU_High_X451" SG_ 504 BCmDRLActiveSignalVal 0;
BA_ "GenSigTimeoutTime_HU_B" SG_ 504 BCmDRLActiveSignalVal 0;
BA_ "GenSigTimeoutTime_HU_A" SG_ 504 BCmDRLActiveSignalVal 0;
BA_ "GenSigTimeoutMsg_HU_Mid_X451" SG_ 504 BCmDRLActiveSignalVal 0;
BA_ "GenSigTimeoutMsg_HU_High_X451" SG_ 504 BCmDRLActiveSignalVal 0;
BA_ "GenSigTimeoutMsg_HU_B" SG_ 504 BCmDRLActiveSignalVal 0;
BA_ "GenSigTimeoutMsg_HU_A" SG_ 504 BCmDRLActiveSignalVal 0;
BA_ "GenSigSendType" SG_ 504 BCmDRLActiveSignalVal 1;
BA_ "GenSigTimeoutMsg_HU_High_X445" SG_ 504 BCmDRLActiveSignalVal 0;
BA_ "GenSigTimeoutMsg_HU_Mid_X445" SG_ 504 BCmDRLActiveSignalVal 0;
BA_ "GenSigTimeoutTime_HU_High_X445" SG_ 504 BCmDRLActiveSignalVal 0;
BA_ "GenSigTimeoutTime_HU_Mid_X445" SG_ 504 BCmDRLActiveSignalVal 0;
BA_ "GenSigTimeoutMsg_IVI" SG_ 504 BCmDRLActiveSignalVal 0;
BA_ "GenSigTimeoutTime_IVI" SG_ 504 BCmDRLActiveSignalVal 0;
BA_ "GenSigTimeoutTime_HU_Mid_X451" SG_ 504 BCmDRLState 0;
BA_ "GenSigTimeoutTime_HU_High_X451" SG_ 504 BCmDRLState 0;
BA_ "GenSigTimeoutTime_HU_B" SG_ 504 BCmDRLState 0;
BA_ "GenSigTimeoutTime_HU_A" SG_ 504 BCmDRLState 0;
BA_ "GenSigTimeoutMsg_HU_Mid_X451" SG_ 504 BCmDRLState 0;
BA_ "GenSigTimeoutMsg_HU_High_X451" SG_ 504 BCmDRLState 0;
BA_ "GenSigTimeoutMsg_HU_B" SG_ 504 BCmDRLState 0;
BA_ "GenSigTimeoutMsg_HU_A" SG_ 504 BCmDRLState 0;
BA_ "GenSigSendType" SG_ 504 BCmDRLState 1;
BA_ "GenSigTimeoutMsg_HU_High_X445" SG_ 504 BCmDRLState 0;
BA_ "GenSigTimeoutMsg_HU_Mid_X445" SG_ 504 BCmDRLState 0;
BA_ "GenSigTimeoutTime_HU_High_X445" SG_ 504 BCmDRLState 0;
BA_ "GenSigTimeoutTime_HU_Mid_X445" SG_ 504 BCmDRLState 0;
BA_ "GenSigTimeoutMsg_IVI" SG_ 504 BCmDRLState 0;
BA_ "GenSigTimeoutTime_IVI" SG_ 504 BCmDRLState 0;
BA_ "GenSigTimeoutTime_HU_Mid_X451" SG_ 504 BCmMoodLightState 0;
BA_ "GenSigTimeoutTime_HU_High_X451" SG_ 504 BCmMoodLightState 0;
BA_ "GenSigTimeoutTime_HU_B" SG_ 504 BCmMoodLightState 0;
BA_ "GenSigTimeoutTime_HU_A" SG_ 504 BCmMoodLightState 0;
BA_ "GenSigTimeoutMsg_HU_Mid_X451" SG_ 504 BCmMoodLightState 0;
BA_ "GenSigTimeoutMsg_HU_High_X451" SG_ 504 BCmMoodLightState 0;
BA_ "GenSigTimeoutMsg_HU_B" SG_ 504 BCmMoodLightState 0;
BA_ "GenSigTimeoutMsg_HU_A" SG_ 504 BCmMoodLightState 0;
BA_ "GenSigSendType" SG_ 504 BCmMoodLightState 1;
BA_ "GenSigTimeoutMsg_HU_High_X445" SG_ 504 BCmMoodLightState 0;
BA_ "GenSigTimeoutMsg_HU_Mid_X445" SG_ 504 BCmMoodLightState 0;
BA_ "GenSigTimeoutTime_HU_High_X445" SG_ 504 BCmMoodLightState 0;
BA_ "GenSigTimeoutTime_HU_Mid_X445" SG_ 504 BCmMoodLightState 0;
BA_ "GenSigTimeoutMsg_IVI" SG_ 504 BCmMoodLightState 0;
BA_ "GenSigTimeoutTime_IVI" SG_ 504 BCmMoodLightState 0;
BA_ "GenSigTimeoutTime_HU_Mid_X451" SG_ 504 BCmUcsData 0;
BA_ "GenSigTimeoutTime_HU_High_X451" SG_ 504 BCmUcsData 0;
BA_ "GenSigTimeoutTime_HU_B" SG_ 504 BCmUcsData 0;
BA_ "GenSigTimeoutTime_HU_A" SG_ 504 BCmUcsData 0;
BA_ "GenSigTimeoutMsg_HU_Mid_X451" SG_ 504 BCmUcsData 0;
BA_ "GenSigTimeoutMsg_HU_High_X451" SG_ 504 BCmUcsData 0;
BA_ "GenSigTimeoutMsg_HU_B" SG_ 504 BCmUcsData 0;
BA_ "GenSigTimeoutMsg_HU_A" SG_ 504 BCmUcsData 0;
BA_ "GenSigStartValue" SG_ 504 BCmUcsData 2;
BA_ "GenSigSendType" SG_ 504 BCmUcsData 1;
BA_ "GenSigTimeoutMsg_HU_High_X445" SG_ 504 BCmUcsData 0;
BA_ "GenSigTimeoutMsg_HU_Mid_X445" SG_ 504 BCmUcsData 0;
BA_ "GenSigTimeoutTime_HU_High_X445" SG_ 504 BCmUcsData 0;
BA_ "GenSigTimeoutTime_HU_Mid_X445" SG_ 504 BCmUcsData 0;
BA_ "GenSigTimeoutMsg_IVI" SG_ 504 BCmUcsData 0;
BA_ "GenSigTimeoutTime_IVI" SG_ 504 BCmUcsData 0;
BA_ "GenSigTimeoutTime_HU_Mid_X451" SG_ 505 BCmMoodLightAllAreaActiveValue 0;
BA_ "GenSigTimeoutTime_HU_High_X451" SG_ 505 BCmMoodLightAllAreaActiveValue 0;
BA_ "GenSigTimeoutTime_HU_B" SG_ 505 BCmMoodLightAllAreaActiveValue 0;
BA_ "GenSigTimeoutTime_HU_A" SG_ 505 BCmMoodLightAllAreaActiveValue 0;
BA_ "GenSigTimeoutMsg_HU_Mid_X451" SG_ 505 BCmMoodLightAllAreaActiveValue 0;
BA_ "GenSigTimeoutMsg_HU_High_X451" SG_ 505 BCmMoodLightAllAreaActiveValue 0;
BA_ "GenSigTimeoutMsg_HU_B" SG_ 505 BCmMoodLightAllAreaActiveValue 0;
BA_ "GenSigTimeoutMsg_HU_A" SG_ 505 BCmMoodLightAllAreaActiveValue 0;
BA_ "GenSigStartValue" SG_ 505 BCmMoodLightAllAreaActiveValue 1;
BA_ "GenSigSendType" SG_ 505 BCmMoodLightAllAreaActiveValue 1;
BA_ "GenSigTimeoutMsg_HU_High_X445" SG_ 505 BCmMoodLightAllAreaActiveValue 0;
BA_ "GenSigTimeoutMsg_HU_Mid_X445" SG_ 505 BCmMoodLightAllAreaActiveValue 0;
BA_ "GenSigTimeoutTime_HU_High_X445" SG_ 505 BCmMoodLightAllAreaActiveValue 0;
BA_ "GenSigTimeoutTime_HU_Mid_X445" SG_ 505 BCmMoodLightAllAreaActiveValue 0;
BA_ "GenSigTimeoutMsg_IVI" SG_ 505 BCmMoodLightAllAreaActiveValue 0;
BA_ "GenSigTimeoutTime_IVI" SG_ 505 BCmMoodLightAllAreaActiveValue 0;
BA_ "GenSigTimeoutTime_HU_Mid_X451" SG_ 505 BCmMoodLightIllumSelActiveVal 0;
BA_ "GenSigTimeoutTime_HU_High_X451" SG_ 505 BCmMoodLightIllumSelActiveVal 0;
BA_ "GenSigTimeoutTime_HU_B" SG_ 505 BCmMoodLightIllumSelActiveVal 0;
BA_ "GenSigTimeoutTime_HU_A" SG_ 505 BCmMoodLightIllumSelActiveVal 0;
BA_ "GenSigTimeoutMsg_HU_Mid_X451" SG_ 505 BCmMoodLightIllumSelActiveVal 0;
BA_ "GenSigTimeoutMsg_HU_High_X451" SG_ 505 BCmMoodLightIllumSelActiveVal 0;
BA_ "GenSigTimeoutMsg_HU_B" SG_ 505 BCmMoodLightIllumSelActiveVal 0;
BA_ "GenSigTimeoutMsg_HU_A" SG_ 505 BCmMoodLightIllumSelActiveVal 0;
BA_ "GenSigStartValue" SG_ 505 BCmMoodLightIllumSelActiveVal 5;
BA_ "GenSigSendType" SG_ 505 BCmMoodLightIllumSelActiveVal 1;
BA_ "GenSigTimeoutMsg_HU_High_X445" SG_ 505 BCmMoodLightIllumSelActiveVal 0;
BA_ "GenSigTimeoutMsg_HU_Mid_X445" SG_ 505 BCmMoodLightIllumSelActiveVal 0;
BA_ "GenSigTimeoutTime_HU_High_X445" SG_ 505 BCmMoodLightIllumSelActiveVal 0;
BA_ "GenSigTimeoutTime_HU_Mid_X445" SG_ 505 BCmMoodLightIllumSelActiveVal 0;
BA_ "GenSigTimeoutMsg_IVI" SG_ 505 BCmMoodLightIllumSelActiveVal 0;
BA_ "GenSigTimeoutTime_IVI" SG_ 505 BCmMoodLightIllumSelActiveVal 0;
BA_ "GenSigTimeoutTime_HU_Mid_X451" SG_ 505 BCmMoodLightActiveColour 0;
BA_ "GenSigTimeoutTime_HU_High_X451" SG_ 505 BCmMoodLightActiveColour 0;
BA_ "GenSigTimeoutTime_HU_B" SG_ 505 BCmMoodLightActiveColour 0;
BA_ "GenSigTimeoutTime_HU_A" SG_ 505 BCmMoodLightActiveColour 0;
BA_ "GenSigTimeoutMsg_HU_Mid_X451" SG_ 505 BCmMoodLightActiveColour 0;
BA_ "GenSigTimeoutMsg_HU_High_X451" SG_ 505 BCmMoodLightActiveColour 0;
BA_ "GenSigTimeoutMsg_HU_B" SG_ 505 BCmMoodLightActiveColour 0;
BA_ "GenSigTimeoutMsg_HU_A" SG_ 505 BCmMoodLightActiveColour 0;
BA_ "GenSigStartValue" SG_ 505 BCmMoodLightActiveColour 1;
BA_ "GenSigSendType" SG_ 505 BCmMoodLightActiveColour 1;
BA_ "GenSigTimeoutMsg_HU_High_X445" SG_ 505 BCmMoodLightActiveColour 0;
BA_ "GenSigTimeoutMsg_HU_Mid_X445" SG_ 505 BCmMoodLightActiveColour 0;
BA_ "GenSigTimeoutTime_HU_High_X445" SG_ 505 BCmMoodLightActiveColour 0;
BA_ "GenSigTimeoutTime_HU_Mid_X445" SG_ 505 BCmMoodLightActiveColour 0;
BA_ "GenSigTimeoutMsg_IVI" SG_ 505 BCmMoodLightActiveColour 0;
BA_ "GenSigTimeoutTime_IVI" SG_ 505 BCmMoodLightActiveColour 0;
BA_ "GenSigTimeoutTime_HU_Mid_X451" SG_ 505 BCmMoodLightRearAreaActiveValue 0;
BA_ "GenSigTimeoutTime_HU_High_X451" SG_ 505 BCmMoodLightRearAreaActiveValue 0;
BA_ "GenSigTimeoutTime_HU_B" SG_ 505 BCmMoodLightRearAreaActiveValue 0;
BA_ "GenSigTimeoutTime_HU_A" SG_ 505 BCmMoodLightRearAreaActiveValue 0;
BA_ "GenSigTimeoutMsg_HU_Mid_X451" SG_ 505 BCmMoodLightRearAreaActiveValue 0;
BA_ "GenSigTimeoutMsg_HU_High_X451" SG_ 505 BCmMoodLightRearAreaActiveValue 0;
BA_ "GenSigTimeoutMsg_HU_B" SG_ 505 BCmMoodLightRearAreaActiveValue 0;
BA_ "GenSigTimeoutMsg_HU_A" SG_ 505 BCmMoodLightRearAreaActiveValue 0;
BA_ "GenSigStartValue" SG_ 505 BCmMoodLightRearAreaActiveValue 1;
BA_ "GenSigSendType" SG_ 505 BCmMoodLightRearAreaActiveValue 1;
BA_ "GenSigTimeoutMsg_HU_High_X445" SG_ 505 BCmMoodLightRearAreaActiveValue 0;
BA_ "GenSigTimeoutMsg_HU_Mid_X445" SG_ 505 BCmMoodLightRearAreaActiveValue 0;
BA_ "GenSigTimeoutTime_HU_High_X445" SG_ 505 BCmMoodLightRearAreaActiveValue 0;
BA_ "GenSigTimeoutTime_HU_Mid_X445" SG_ 505 BCmMoodLightRearAreaActiveValue 0;
BA_ "GenSigTimeoutMsg_IVI" SG_ 505 BCmMoodLightRearAreaActiveValue 0;
BA_ "GenSigTimeoutTime_IVI" SG_ 505 BCmMoodLightRearAreaActiveValue 0;
BA_ "GenSigTimeoutTime_HU_Mid_X451" SG_ 505 BCmMoodLightFrontRHAreaActiveVal 0;
BA_ "GenSigTimeoutTime_HU_High_X451" SG_ 505 BCmMoodLightFrontRHAreaActiveVal 0;
BA_ "GenSigTimeoutTime_HU_B" SG_ 505 BCmMoodLightFrontRHAreaActiveVal 0;
BA_ "GenSigTimeoutTime_HU_A" SG_ 505 BCmMoodLightFrontRHAreaActiveVal 0;
BA_ "GenSigTimeoutMsg_HU_Mid_X451" SG_ 505 BCmMoodLightFrontRHAreaActiveVal 0;
BA_ "GenSigTimeoutMsg_HU_High_X451" SG_ 505 BCmMoodLightFrontRHAreaActiveVal 0;
BA_ "GenSigTimeoutMsg_HU_B" SG_ 505 BCmMoodLightFrontRHAreaActiveVal 0;
BA_ "GenSigTimeoutMsg_HU_A" SG_ 505 BCmMoodLightFrontRHAreaActiveVal 0;
BA_ "GenSigStartValue" SG_ 505 BCmMoodLightFrontRHAreaActiveVal 1;
BA_ "GenSigSendType" SG_ 505 BCmMoodLightFrontRHAreaActiveVal 1;
BA_ "GenSigTimeoutMsg_HU_High_X445" SG_ 505 BCmMoodLightFrontRHAreaActiveVal 0;
BA_ "GenSigTimeoutMsg_HU_Mid_X445" SG_ 505 BCmMoodLightFrontRHAreaActiveVal 0;
BA_ "GenSigTimeoutTime_HU_High_X445" SG_ 505 BCmMoodLightFrontRHAreaActiveVal 0;
BA_ "GenSigTimeoutTime_HU_Mid_X445" SG_ 505 BCmMoodLightFrontRHAreaActiveVal 0;
BA_ "GenSigTimeoutMsg_IVI" SG_ 505 BCmMoodLightFrontRHAreaActiveVal 0;
BA_ "GenSigTimeoutTime_IVI" SG_ 505 BCmMoodLightFrontRHAreaActiveVal 0;
BA_ "SystemSignalLongSymbol" SG_ 505 BCmMoodLightFrontRHAreaActiveVal "BCmMoodLightFrontRHAreaActiveValue";
BA_ "GenSigTimeoutTime_HU_Mid_X451" SG_ 505 BCmMoodLightFloorConsoleAreaActi 0;
BA_ "GenSigTimeoutTime_HU_High_X451" SG_ 505 BCmMoodLightFloorConsoleAreaActi 0;
BA_ "GenSigTimeoutTime_HU_B" SG_ 505 BCmMoodLightFloorConsoleAreaActi 0;
BA_ "GenSigTimeoutTime_HU_A" SG_ 505 BCmMoodLightFloorConsoleAreaActi 0;
BA_ "GenSigTimeoutMsg_HU_Mid_X451" SG_ 505 BCmMoodLightFloorConsoleAreaActi 0;
BA_ "GenSigTimeoutMsg_HU_High_X451" SG_ 505 BCmMoodLightFloorConsoleAreaActi 0;
BA_ "GenSigTimeoutMsg_HU_B" SG_ 505 BCmMoodLightFloorConsoleAreaActi 0;
BA_ "GenSigTimeoutMsg_HU_A" SG_ 505 BCmMoodLightFloorConsoleAreaActi 0;
BA_ "GenSigStartValue" SG_ 505 BCmMoodLightFloorConsoleAreaActi 1;
BA_ "GenSigSendType" SG_ 505 BCmMoodLightFloorConsoleAreaActi 1;
BA_ "GenSigTimeoutMsg_HU_High_X445" SG_ 505 BCmMoodLightFloorConsoleAreaActi 0;
BA_ "GenSigTimeoutMsg_HU_Mid_X445" SG_ 505 BCmMoodLightFloorConsoleAreaActi 0;
BA_ "GenSigTimeoutTime_HU_High_X445" SG_ 505 BCmMoodLightFloorConsoleAreaActi 0;
BA_ "GenSigTimeoutTime_HU_Mid_X445" SG_ 505 BCmMoodLightFloorConsoleAreaActi 0;
BA_ "GenSigTimeoutMsg_IVI" SG_ 505 BCmMoodLightFloorConsoleAreaActi 0;
BA_ "GenSigTimeoutTime_IVI" SG_ 505 BCmMoodLightFloorConsoleAreaActi 0;
BA_ "SystemSignalLongSymbol" SG_ 505 BCmMoodLightFloorConsoleAreaActi "BCmMoodLightFloorConsoleAreaActiveValue";
BA_ "GenSigTimeoutTime_HU_Mid_X451" SG_ 505 BCmMoodLightData 0;
BA_ "GenSigTimeoutTime_HU_High_X451" SG_ 505 BCmMoodLightData 0;
BA_ "GenSigTimeoutTime_HU_B" SG_ 505 BCmMoodLightData 0;
BA_ "GenSigTimeoutTime_HU_A" SG_ 505 BCmMoodLightData 0;
BA_ "GenSigTimeoutMsg_HU_Mid_X451" SG_ 505 BCmMoodLightData 0;
BA_ "GenSigTimeoutMsg_HU_High_X451" SG_ 505 BCmMoodLightData 0;
BA_ "GenSigTimeoutMsg_HU_B" SG_ 505 BCmMoodLightData 0;
BA_ "GenSigTimeoutMsg_HU_A" SG_ 505 BCmMoodLightData 0;
BA_ "GenSigStartValue" SG_ 505 BCmMoodLightData 2;
BA_ "GenSigSendType" SG_ 505 BCmMoodLightData 1;
BA_ "GenSigTimeoutMsg_HU_High_X445" SG_ 505 BCmMoodLightData 0;
BA_ "GenSigTimeoutMsg_HU_Mid_X445" SG_ 505 BCmMoodLightData 0;
BA_ "GenSigTimeoutTime_HU_High_X445" SG_ 505 BCmMoodLightData 0;
BA_ "GenSigTimeoutTime_HU_Mid_X445" SG_ 505 BCmMoodLightData 0;
BA_ "GenSigTimeoutMsg_IVI" SG_ 505 BCmMoodLightData 0;
BA_ "GenSigTimeoutTime_IVI" SG_ 505 BCmMoodLightData 0;
BA_ "GenSigTimeoutTime_HU_Mid_X451" SG_ 505 BCmMoodLightIllumPossibleLevels 0;
BA_ "GenSigTimeoutTime_HU_High_X451" SG_ 505 BCmMoodLightIllumPossibleLevels 0;
BA_ "GenSigTimeoutTime_HU_B" SG_ 505 BCmMoodLightIllumPossibleLevels 0;
BA_ "GenSigTimeoutTime_HU_A" SG_ 505 BCmMoodLightIllumPossibleLevels 0;
BA_ "GenSigTimeoutMsg_HU_Mid_X451" SG_ 505 BCmMoodLightIllumPossibleLevels 0;
BA_ "GenSigTimeoutMsg_HU_High_X451" SG_ 505 BCmMoodLightIllumPossibleLevels 0;
BA_ "GenSigTimeoutMsg_HU_B" SG_ 505 BCmMoodLightIllumPossibleLevels 0;
BA_ "GenSigTimeoutMsg_HU_A" SG_ 505 BCmMoodLightIllumPossibleLevels 0;
BA_ "GenSigStartValue" SG_ 505 BCmMoodLightIllumPossibleLevels 5;
BA_ "GenSigSendType" SG_ 505 BCmMoodLightIllumPossibleLevels 1;
BA_ "GenSigTimeoutMsg_HU_High_X445" SG_ 505 BCmMoodLightIllumPossibleLevels 0;
BA_ "GenSigTimeoutMsg_HU_Mid_X445" SG_ 505 BCmMoodLightIllumPossibleLevels 0;
BA_ "GenSigTimeoutTime_HU_High_X445" SG_ 505 BCmMoodLightIllumPossibleLevels 0;
BA_ "GenSigTimeoutTime_HU_Mid_X445" SG_ 505 BCmMoodLightIllumPossibleLevels 0;
BA_ "GenSigTimeoutMsg_IVI" SG_ 505 BCmMoodLightIllumPossibleLevels 0;
BA_ "GenSigTimeoutTime_IVI" SG_ 505 BCmMoodLightIllumPossibleLevels 0;
BA_ "GenSigTimeoutTime_HU_Mid_X451" SG_ 505 BCmMoodLightHotMagentaColorSelOn 0;
BA_ "GenSigTimeoutTime_HU_High_X451" SG_ 505 BCmMoodLightHotMagentaColorSelOn 0;
BA_ "GenSigTimeoutTime_HU_B" SG_ 505 BCmMoodLightHotMagentaColorSelOn 0;
BA_ "GenSigTimeoutTime_HU_A" SG_ 505 BCmMoodLightHotMagentaColorSelOn 0;
BA_ "GenSigTimeoutMsg_HU_Mid_X451" SG_ 505 BCmMoodLightHotMagentaColorSelOn 0;
BA_ "GenSigTimeoutMsg_HU_High_X451" SG_ 505 BCmMoodLightHotMagentaColorSelOn 0;
BA_ "GenSigTimeoutMsg_HU_B" SG_ 505 BCmMoodLightHotMagentaColorSelOn 0;
BA_ "GenSigTimeoutMsg_HU_A" SG_ 505 BCmMoodLightHotMagentaColorSelOn 0;
BA_ "GenSigSendType" SG_ 505 BCmMoodLightHotMagentaColorSelOn 1;
BA_ "GenSigTimeoutMsg_HU_High_X445" SG_ 505 BCmMoodLightHotMagentaColorSelOn 0;
BA_ "GenSigTimeoutMsg_HU_Mid_X445" SG_ 505 BCmMoodLightHotMagentaColorSelOn 0;
BA_ "GenSigTimeoutTime_HU_High_X445" SG_ 505 BCmMoodLightHotMagentaColorSelOn 0;
BA_ "GenSigTimeoutTime_HU_Mid_X445" SG_ 505 BCmMoodLightHotMagentaColorSelOn 0;
BA_ "GenSigTimeoutMsg_IVI" SG_ 505 BCmMoodLightHotMagentaColorSelOn 0;
BA_ "GenSigTimeoutTime_IVI" SG_ 505 BCmMoodLightHotMagentaColorSelOn 0;
BA_ "SystemSignalLongSymbol" SG_ 505 BCmMoodLightHotMagentaColorSelOn "BCmMoodLightHotMagentaColorSelOnHU";
BA_ "GenSigTimeoutTime_HU_Mid_X451" SG_ 505 BCmMoodLightGoldYellowColorSelOn 0;
BA_ "GenSigTimeoutTime_HU_High_X451" SG_ 505 BCmMoodLightGoldYellowColorSelOn 0;
BA_ "GenSigTimeoutTime_HU_B" SG_ 505 BCmMoodLightGoldYellowColorSelOn 0;
BA_ "GenSigTimeoutTime_HU_A" SG_ 505 BCmMoodLightGoldYellowColorSelOn 0;
BA_ "GenSigTimeoutMsg_HU_Mid_X451" SG_ 505 BCmMoodLightGoldYellowColorSelOn 0;
BA_ "GenSigTimeoutMsg_HU_High_X451" SG_ 505 BCmMoodLightGoldYellowColorSelOn 0;
BA_ "GenSigTimeoutMsg_HU_B" SG_ 505 BCmMoodLightGoldYellowColorSelOn 0;
BA_ "GenSigTimeoutMsg_HU_A" SG_ 505 BCmMoodLightGoldYellowColorSelOn 0;
BA_ "GenSigSendType" SG_ 505 BCmMoodLightGoldYellowColorSelOn 1;
BA_ "GenSigTimeoutMsg_HU_High_X445" SG_ 505 BCmMoodLightGoldYellowColorSelOn 0;
BA_ "GenSigTimeoutMsg_HU_Mid_X445" SG_ 505 BCmMoodLightGoldYellowColorSelOn 0;
BA_ "GenSigTimeoutTime_HU_High_X445" SG_ 505 BCmMoodLightGoldYellowColorSelOn 0;
BA_ "GenSigTimeoutTime_HU_Mid_X445" SG_ 505 BCmMoodLightGoldYellowColorSelOn 0;
BA_ "GenSigTimeoutMsg_IVI" SG_ 505 BCmMoodLightGoldYellowColorSelOn 0;
BA_ "GenSigTimeoutTime_IVI" SG_ 505 BCmMoodLightGoldYellowColorSelOn 0;
BA_ "SystemSignalLongSymbol" SG_ 505 BCmMoodLightGoldYellowColorSelOn "BCmMoodLightGoldYellowColorSelOnHU";
BA_ "GenSigTimeoutTime_HU_Mid_X451" SG_ 505 BCmMoodLightFrenchLimeColorSelOn 0;
BA_ "GenSigTimeoutTime_HU_High_X451" SG_ 505 BCmMoodLightFrenchLimeColorSelOn 0;
BA_ "GenSigTimeoutTime_HU_B" SG_ 505 BCmMoodLightFrenchLimeColorSelOn 0;
BA_ "GenSigTimeoutTime_HU_A" SG_ 505 BCmMoodLightFrenchLimeColorSelOn 0;
BA_ "GenSigTimeoutMsg_HU_Mid_X451" SG_ 505 BCmMoodLightFrenchLimeColorSelOn 0;
BA_ "GenSigTimeoutMsg_HU_High_X451" SG_ 505 BCmMoodLightFrenchLimeColorSelOn 0;
BA_ "GenSigTimeoutMsg_HU_B" SG_ 505 BCmMoodLightFrenchLimeColorSelOn 0;
BA_ "GenSigTimeoutMsg_HU_A" SG_ 505 BCmMoodLightFrenchLimeColorSelOn 0;
BA_ "GenSigSendType" SG_ 505 BCmMoodLightFrenchLimeColorSelOn 1;
BA_ "GenSigTimeoutMsg_HU_High_X445" SG_ 505 BCmMoodLightFrenchLimeColorSelOn 0;
BA_ "GenSigTimeoutMsg_HU_Mid_X445" SG_ 505 BCmMoodLightFrenchLimeColorSelOn 0;
BA_ "GenSigTimeoutTime_HU_High_X445" SG_ 505 BCmMoodLightFrenchLimeColorSelOn 0;
BA_ "GenSigTimeoutTime_HU_Mid_X445" SG_ 505 BCmMoodLightFrenchLimeColorSelOn 0;
BA_ "GenSigTimeoutMsg_IVI" SG_ 505 BCmMoodLightFrenchLimeColorSelOn 0;
BA_ "GenSigTimeoutTime_IVI" SG_ 505 BCmMoodLightFrenchLimeColorSelOn 0;
BA_ "SystemSignalLongSymbol" SG_ 505 BCmMoodLightFrenchLimeColorSelOn "BCmMoodLightFrenchLimeColorSelOnHU";
BA_ "GenSigTimeoutTime_HU_Mid_X451" SG_ 505 BCmMoodLightFrontLHAreaActiveVal 0;
BA_ "GenSigTimeoutTime_HU_High_X451" SG_ 505 BCmMoodLightFrontLHAreaActiveVal 0;
BA_ "GenSigTimeoutTime_HU_B" SG_ 505 BCmMoodLightFrontLHAreaActiveVal 0;
BA_ "GenSigTimeoutTime_HU_A" SG_ 505 BCmMoodLightFrontLHAreaActiveVal 0;
BA_ "GenSigTimeoutMsg_HU_Mid_X451" SG_ 505 BCmMoodLightFrontLHAreaActiveVal 0;
BA_ "GenSigTimeoutMsg_HU_High_X451" SG_ 505 BCmMoodLightFrontLHAreaActiveVal 0;
BA_ "GenSigTimeoutMsg_HU_B" SG_ 505 BCmMoodLightFrontLHAreaActiveVal 0;
BA_ "GenSigTimeoutMsg_HU_A" SG_ 505 BCmMoodLightFrontLHAreaActiveVal 0;
BA_ "GenSigStartValue" SG_ 505 BCmMoodLightFrontLHAreaActiveVal 1;
BA_ "GenSigSendType" SG_ 505 BCmMoodLightFrontLHAreaActiveVal 1;
BA_ "GenSigTimeoutMsg_HU_High_X445" SG_ 505 BCmMoodLightFrontLHAreaActiveVal 0;
BA_ "GenSigTimeoutMsg_HU_Mid_X445" SG_ 505 BCmMoodLightFrontLHAreaActiveVal 0;
BA_ "GenSigTimeoutTime_HU_High_X445" SG_ 505 BCmMoodLightFrontLHAreaActiveVal 0;
BA_ "GenSigTimeoutTime_HU_Mid_X445" SG_ 505 BCmMoodLightFrontLHAreaActiveVal 0;
BA_ "GenSigTimeoutMsg_IVI" SG_ 505 BCmMoodLightFrontLHAreaActiveVal 0;
BA_ "GenSigTimeoutTime_IVI" SG_ 505 BCmMoodLightFrontLHAreaActiveVal 0;
BA_ "SystemSignalLongSymbol" SG_ 505 BCmMoodLightFrontLHAreaActiveVal "BCmMoodLightFrontLHAreaActiveValue";
BA_ "GenSigTimeoutTime_HU_Mid_X451" SG_ 505 BCmMoodLightPossibleModes 0;
BA_ "GenSigTimeoutTime_HU_High_X451" SG_ 505 BCmMoodLightPossibleModes 0;
BA_ "GenSigTimeoutTime_HU_B" SG_ 505 BCmMoodLightPossibleModes 0;
BA_ "GenSigTimeoutTime_HU_A" SG_ 505 BCmMoodLightPossibleModes 0;
BA_ "GenSigTimeoutMsg_HU_Mid_X451" SG_ 505 BCmMoodLightPossibleModes 0;
BA_ "GenSigTimeoutMsg_HU_High_X451" SG_ 505 BCmMoodLightPossibleModes 0;
BA_ "GenSigTimeoutMsg_HU_B" SG_ 505 BCmMoodLightPossibleModes 0;
BA_ "GenSigTimeoutMsg_HU_A" SG_ 505 BCmMoodLightPossibleModes 0;
BA_ "GenSigStartValue" SG_ 505 BCmMoodLightPossibleModes 2;
BA_ "GenSigSendType" SG_ 505 BCmMoodLightPossibleModes 1;
BA_ "GenSigTimeoutMsg_HU_High_X445" SG_ 505 BCmMoodLightPossibleModes 0;
BA_ "GenSigTimeoutMsg_HU_Mid_X445" SG_ 505 BCmMoodLightPossibleModes 0;
BA_ "GenSigTimeoutTime_HU_High_X445" SG_ 505 BCmMoodLightPossibleModes 0;
BA_ "GenSigTimeoutTime_HU_Mid_X445" SG_ 505 BCmMoodLightPossibleModes 0;
BA_ "GenSigTimeoutMsg_IVI" SG_ 505 BCmMoodLightPossibleModes 0;
BA_ "GenSigTimeoutTime_IVI" SG_ 505 BCmMoodLightPossibleModes 0;
BA_ "GenSigTimeoutTime_HU_Mid_X451" SG_ 505 BCmMoodLightActiveModeValue 0;
BA_ "GenSigTimeoutTime_HU_High_X451" SG_ 505 BCmMoodLightActiveModeValue 0;
BA_ "GenSigTimeoutTime_HU_B" SG_ 505 BCmMoodLightActiveModeValue 0;
BA_ "GenSigTimeoutTime_HU_A" SG_ 505 BCmMoodLightActiveModeValue 0;
BA_ "GenSigTimeoutMsg_HU_Mid_X451" SG_ 505 BCmMoodLightActiveModeValue 0;
BA_ "GenSigTimeoutMsg_HU_High_X451" SG_ 505 BCmMoodLightActiveModeValue 0;
BA_ "GenSigTimeoutMsg_HU_B" SG_ 505 BCmMoodLightActiveModeValue 0;
BA_ "GenSigTimeoutMsg_HU_A" SG_ 505 BCmMoodLightActiveModeValue 0;
BA_ "GenSigSendType" SG_ 505 BCmMoodLightActiveModeValue 1;
BA_ "GenSigTimeoutMsg_HU_High_X445" SG_ 505 BCmMoodLightActiveModeValue 0;
BA_ "GenSigTimeoutMsg_HU_Mid_X445" SG_ 505 BCmMoodLightActiveModeValue 0;
BA_ "GenSigTimeoutTime_HU_High_X445" SG_ 505 BCmMoodLightActiveModeValue 0;
BA_ "GenSigTimeoutTime_HU_Mid_X445" SG_ 505 BCmMoodLightActiveModeValue 0;
BA_ "GenSigTimeoutMsg_IVI" SG_ 505 BCmMoodLightActiveModeValue 0;
BA_ "GenSigTimeoutTime_IVI" SG_ 505 BCmMoodLightActiveModeValue 0;
BA_ "GenSigTimeoutTime_HU_Mid_X451" SG_ 505 BCmMoodLightPolarBrightWhiteColo 0;
BA_ "GenSigTimeoutTime_HU_High_X451" SG_ 505 BCmMoodLightPolarBrightWhiteColo 0;
BA_ "GenSigTimeoutTime_HU_B" SG_ 505 BCmMoodLightPolarBrightWhiteColo 0;
BA_ "GenSigTimeoutTime_HU_A" SG_ 505 BCmMoodLightPolarBrightWhiteColo 0;
BA_ "GenSigTimeoutMsg_HU_Mid_X451" SG_ 505 BCmMoodLightPolarBrightWhiteColo 0;
BA_ "GenSigTimeoutMsg_HU_High_X451" SG_ 505 BCmMoodLightPolarBrightWhiteColo 0;
BA_ "GenSigTimeoutMsg_HU_B" SG_ 505 BCmMoodLightPolarBrightWhiteColo 0;
BA_ "GenSigTimeoutMsg_HU_A" SG_ 505 BCmMoodLightPolarBrightWhiteColo 0;
BA_ "GenSigSendType" SG_ 505 BCmMoodLightPolarBrightWhiteColo 1;
BA_ "GenSigTimeoutMsg_HU_High_X445" SG_ 505 BCmMoodLightPolarBrightWhiteColo 0;
BA_ "GenSigTimeoutMsg_HU_Mid_X445" SG_ 505 BCmMoodLightPolarBrightWhiteColo 0;
BA_ "GenSigTimeoutTime_HU_High_X445" SG_ 505 BCmMoodLightPolarBrightWhiteColo 0;
BA_ "GenSigTimeoutTime_HU_Mid_X445" SG_ 505 BCmMoodLightPolarBrightWhiteColo 0;
BA_ "GenSigTimeoutMsg_IVI" SG_ 505 BCmMoodLightPolarBrightWhiteColo 0;
BA_ "GenSigTimeoutTime_IVI" SG_ 505 BCmMoodLightPolarBrightWhiteColo 0;
BA_ "SystemSignalLongSymbol" SG_ 505 BCmMoodLightPolarBrightWhiteColo "BCmMoodLightPolarBrightWhiteColorSelOnHU";
BA_ "GenSigTimeoutTime_HU_Mid_X451" SG_ 505 BCmMoodLightAeroBlueColorSelOnHU 0;
BA_ "GenSigTimeoutTime_HU_High_X451" SG_ 505 BCmMoodLightAeroBlueColorSelOnHU 0;
BA_ "GenSigTimeoutTime_HU_B" SG_ 505 BCmMoodLightAeroBlueColorSelOnHU 0;
BA_ "GenSigTimeoutTime_HU_A" SG_ 505 BCmMoodLightAeroBlueColorSelOnHU 0;
BA_ "GenSigTimeoutMsg_HU_Mid_X451" SG_ 505 BCmMoodLightAeroBlueColorSelOnHU 0;
BA_ "GenSigTimeoutMsg_HU_High_X451" SG_ 505 BCmMoodLightAeroBlueColorSelOnHU 0;
BA_ "GenSigTimeoutMsg_HU_B" SG_ 505 BCmMoodLightAeroBlueColorSelOnHU 0;
BA_ "GenSigTimeoutMsg_HU_A" SG_ 505 BCmMoodLightAeroBlueColorSelOnHU 0;
BA_ "GenSigSendType" SG_ 505 BCmMoodLightAeroBlueColorSelOnHU 1;
BA_ "GenSigTimeoutMsg_HU_High_X445" SG_ 505 BCmMoodLightAeroBlueColorSelOnHU 0;
BA_ "GenSigTimeoutMsg_HU_Mid_X445" SG_ 505 BCmMoodLightAeroBlueColorSelOnHU 0;
BA_ "GenSigTimeoutTime_HU_High_X445" SG_ 505 BCmMoodLightAeroBlueColorSelOnHU 0;
BA_ "GenSigTimeoutTime_HU_Mid_X445" SG_ 505 BCmMoodLightAeroBlueColorSelOnHU 0;
BA_ "GenSigTimeoutMsg_IVI" SG_ 505 BCmMoodLightAeroBlueColorSelOnHU 0;
BA_ "GenSigTimeoutTime_IVI" SG_ 505 BCmMoodLightAeroBlueColorSelOnHU 0;
BA_ "GenSigTimeoutTime_HU_Mid_X451" SG_ 505 BCmMoodLightPurpleColorSelOnHU 0;
BA_ "GenSigTimeoutTime_HU_High_X451" SG_ 505 BCmMoodLightPurpleColorSelOnHU 0;
BA_ "GenSigTimeoutTime_HU_B" SG_ 505 BCmMoodLightPurpleColorSelOnHU 0;
BA_ "GenSigTimeoutTime_HU_A" SG_ 505 BCmMoodLightPurpleColorSelOnHU 0;
BA_ "GenSigTimeoutMsg_HU_Mid_X451" SG_ 505 BCmMoodLightPurpleColorSelOnHU 0;
BA_ "GenSigTimeoutMsg_HU_High_X451" SG_ 505 BCmMoodLightPurpleColorSelOnHU 0;
BA_ "GenSigTimeoutMsg_HU_B" SG_ 505 BCmMoodLightPurpleColorSelOnHU 0;
BA_ "GenSigTimeoutMsg_HU_A" SG_ 505 BCmMoodLightPurpleColorSelOnHU 0;
BA_ "GenSigSendType" SG_ 505 BCmMoodLightPurpleColorSelOnHU 1;
BA_ "GenSigTimeoutMsg_HU_High_X445" SG_ 505 BCmMoodLightPurpleColorSelOnHU 0;
BA_ "GenSigTimeoutMsg_HU_Mid_X445" SG_ 505 BCmMoodLightPurpleColorSelOnHU 0;
BA_ "GenSigTimeoutTime_HU_High_X445" SG_ 505 BCmMoodLightPurpleColorSelOnHU 0;
BA_ "GenSigTimeoutTime_HU_Mid_X445" SG_ 505 BCmMoodLightPurpleColorSelOnHU 0;
BA_ "GenSigTimeoutMsg_IVI" SG_ 505 BCmMoodLightPurpleColorSelOnHU 0;
BA_ "GenSigTimeoutTime_IVI" SG_ 505 BCmMoodLightPurpleColorSelOnHU 0;
BA_ "GenSigTimeoutTime_HU_Mid_X451" SG_ 505 BCmMoodLightFluorescentGreenColo 0;
BA_ "GenSigTimeoutTime_HU_High_X451" SG_ 505 BCmMoodLightFluorescentGreenColo 0;
BA_ "GenSigTimeoutTime_HU_B" SG_ 505 BCmMoodLightFluorescentGreenColo 0;
BA_ "GenSigTimeoutTime_HU_A" SG_ 505 BCmMoodLightFluorescentGreenColo 0;
BA_ "GenSigTimeoutMsg_HU_Mid_X451" SG_ 505 BCmMoodLightFluorescentGreenColo 0;
BA_ "GenSigTimeoutMsg_HU_High_X451" SG_ 505 BCmMoodLightFluorescentGreenColo 0;
BA_ "GenSigTimeoutMsg_HU_B" SG_ 505 BCmMoodLightFluorescentGreenColo 0;
BA_ "GenSigTimeoutMsg_HU_A" SG_ 505 BCmMoodLightFluorescentGreenColo 0;
BA_ "GenSigSendType" SG_ 505 BCmMoodLightFluorescentGreenColo 1;
BA_ "GenSigTimeoutMsg_HU_High_X445" SG_ 505 BCmMoodLightFluorescentGreenColo 0;
BA_ "GenSigTimeoutMsg_HU_Mid_X445" SG_ 505 BCmMoodLightFluorescentGreenColo 0;
BA_ "GenSigTimeoutTime_HU_High_X445" SG_ 505 BCmMoodLightFluorescentGreenColo 0;
BA_ "GenSigTimeoutTime_HU_Mid_X445" SG_ 505 BCmMoodLightFluorescentGreenColo 0;
BA_ "GenSigTimeoutMsg_IVI" SG_ 505 BCmMoodLightFluorescentGreenColo 0;
BA_ "GenSigTimeoutTime_IVI" SG_ 505 BCmMoodLightFluorescentGreenColo 0;
BA_ "SystemSignalLongSymbol" SG_ 505 BCmMoodLightFluorescentGreenColo "BCmMoodLightFluorescentGreenColorSelOnHU";
BA_ "GenSigTimeoutTime_HU_Mid_X451" SG_ 505 BCmMoodLightCyanBlueColorSelOnHU 0;
BA_ "GenSigTimeoutTime_HU_High_X451" SG_ 505 BCmMoodLightCyanBlueColorSelOnHU 0;
BA_ "GenSigTimeoutTime_HU_B" SG_ 505 BCmMoodLightCyanBlueColorSelOnHU 0;
BA_ "GenSigTimeoutTime_HU_A" SG_ 505 BCmMoodLightCyanBlueColorSelOnHU 0;
BA_ "GenSigTimeoutMsg_HU_Mid_X451" SG_ 505 BCmMoodLightCyanBlueColorSelOnHU 0;
BA_ "GenSigTimeoutMsg_HU_High_X451" SG_ 505 BCmMoodLightCyanBlueColorSelOnHU 0;
BA_ "GenSigTimeoutMsg_HU_B" SG_ 505 BCmMoodLightCyanBlueColorSelOnHU 0;
BA_ "GenSigTimeoutMsg_HU_A" SG_ 505 BCmMoodLightCyanBlueColorSelOnHU 0;
BA_ "GenSigSendType" SG_ 505 BCmMoodLightCyanBlueColorSelOnHU 1;
BA_ "GenSigTimeoutMsg_HU_High_X445" SG_ 505 BCmMoodLightCyanBlueColorSelOnHU 0;
BA_ "GenSigTimeoutMsg_HU_Mid_X445" SG_ 505 BCmMoodLightCyanBlueColorSelOnHU 0;
BA_ "GenSigTimeoutTime_HU_High_X445" SG_ 505 BCmMoodLightCyanBlueColorSelOnHU 0;
BA_ "GenSigTimeoutTime_HU_Mid_X445" SG_ 505 BCmMoodLightCyanBlueColorSelOnHU 0;
BA_ "GenSigTimeoutMsg_IVI" SG_ 505 BCmMoodLightCyanBlueColorSelOnHU 0;
BA_ "GenSigTimeoutTime_IVI" SG_ 505 BCmMoodLightCyanBlueColorSelOnHU 0;
BA_ "GenSigTimeoutTime_HU_Mid_X451" SG_ 505 BCmMoodLightCoolBlueColorSelOnHU 0;
BA_ "GenSigTimeoutTime_HU_High_X451" SG_ 505 BCmMoodLightCoolBlueColorSelOnHU 0;
BA_ "GenSigTimeoutTime_HU_B" SG_ 505 BCmMoodLightCoolBlueColorSelOnHU 0;
BA_ "GenSigTimeoutTime_HU_A" SG_ 505 BCmMoodLightCoolBlueColorSelOnHU 0;
BA_ "GenSigTimeoutMsg_HU_Mid_X451" SG_ 505 BCmMoodLightCoolBlueColorSelOnHU 0;
BA_ "GenSigTimeoutMsg_HU_High_X451" SG_ 505 BCmMoodLightCoolBlueColorSelOnHU 0;
BA_ "GenSigTimeoutMsg_HU_B" SG_ 505 BCmMoodLightCoolBlueColorSelOnHU 0;
BA_ "GenSigTimeoutMsg_HU_A" SG_ 505 BCmMoodLightCoolBlueColorSelOnHU 0;
BA_ "GenSigSendType" SG_ 505 BCmMoodLightCoolBlueColorSelOnHU 1;
BA_ "GenSigTimeoutMsg_HU_High_X445" SG_ 505 BCmMoodLightCoolBlueColorSelOnHU 0;
BA_ "GenSigTimeoutMsg_HU_Mid_X445" SG_ 505 BCmMoodLightCoolBlueColorSelOnHU 0;
BA_ "GenSigTimeoutTime_HU_High_X445" SG_ 505 BCmMoodLightCoolBlueColorSelOnHU 0;
BA_ "GenSigTimeoutTime_HU_Mid_X445" SG_ 505 BCmMoodLightCoolBlueColorSelOnHU 0;
BA_ "GenSigTimeoutMsg_IVI" SG_ 505 BCmMoodLightCoolBlueColorSelOnHU 0;
BA_ "GenSigTimeoutTime_IVI" SG_ 505 BCmMoodLightCoolBlueColorSelOnHU 0;
BA_ "GenSigTimeoutTime_HU_Mid_X451" SG_ 505 BCmMoodLightIvoryOFFWhiteColorSe 0;
BA_ "GenSigTimeoutTime_HU_High_X451" SG_ 505 BCmMoodLightIvoryOFFWhiteColorSe 0;
BA_ "GenSigTimeoutTime_HU_B" SG_ 505 BCmMoodLightIvoryOFFWhiteColorSe 0;
BA_ "GenSigTimeoutTime_HU_A" SG_ 505 BCmMoodLightIvoryOFFWhiteColorSe 0;
BA_ "GenSigTimeoutMsg_HU_Mid_X451" SG_ 505 BCmMoodLightIvoryOFFWhiteColorSe 0;
BA_ "GenSigTimeoutMsg_HU_High_X451" SG_ 505 BCmMoodLightIvoryOFFWhiteColorSe 0;
BA_ "GenSigTimeoutMsg_HU_B" SG_ 505 BCmMoodLightIvoryOFFWhiteColorSe 0;
BA_ "GenSigTimeoutMsg_HU_A" SG_ 505 BCmMoodLightIvoryOFFWhiteColorSe 0;
BA_ "GenSigSendType" SG_ 505 BCmMoodLightIvoryOFFWhiteColorSe 1;
BA_ "GenSigTimeoutMsg_HU_High_X445" SG_ 505 BCmMoodLightIvoryOFFWhiteColorSe 0;
BA_ "GenSigTimeoutMsg_HU_Mid_X445" SG_ 505 BCmMoodLightIvoryOFFWhiteColorSe 0;
BA_ "GenSigTimeoutTime_HU_High_X445" SG_ 505 BCmMoodLightIvoryOFFWhiteColorSe 0;
BA_ "GenSigTimeoutTime_HU_Mid_X445" SG_ 505 BCmMoodLightIvoryOFFWhiteColorSe 0;
BA_ "GenSigTimeoutMsg_IVI" SG_ 505 BCmMoodLightIvoryOFFWhiteColorSe 0;
BA_ "GenSigTimeoutTime_IVI" SG_ 505 BCmMoodLightIvoryOFFWhiteColorSe 0;
BA_ "SystemSignalLongSymbol" SG_ 505 BCmMoodLightIvoryOFFWhiteColorSe "BCmMoodLightIvoryOFFWhiteColorSelOnHU";
BA_ "GenSigTimeoutTime_HU_Mid_X451" SG_ 505 BCmMoodLightIceBlueColorSelOnHU 0;
BA_ "GenSigTimeoutTime_HU_High_X451" SG_ 505 BCmMoodLightIceBlueColorSelOnHU 0;
BA_ "GenSigTimeoutTime_HU_B" SG_ 505 BCmMoodLightIceBlueColorSelOnHU 0;
BA_ "GenSigTimeoutTime_HU_A" SG_ 505 BCmMoodLightIceBlueColorSelOnHU 0;
BA_ "GenSigTimeoutMsg_HU_Mid_X451" SG_ 505 BCmMoodLightIceBlueColorSelOnHU 0;
BA_ "GenSigTimeoutMsg_HU_High_X451" SG_ 505 BCmMoodLightIceBlueColorSelOnHU 0;
BA_ "GenSigTimeoutMsg_HU_B" SG_ 505 BCmMoodLightIceBlueColorSelOnHU 0;
BA_ "GenSigTimeoutMsg_HU_A" SG_ 505 BCmMoodLightIceBlueColorSelOnHU 0;
BA_ "GenSigSendType" SG_ 505 BCmMoodLightIceBlueColorSelOnHU 1;
BA_ "GenSigTimeoutMsg_HU_High_X445" SG_ 505 BCmMoodLightIceBlueColorSelOnHU 0;
BA_ "GenSigTimeoutMsg_HU_Mid_X445" SG_ 505 BCmMoodLightIceBlueColorSelOnHU 0;
BA_ "GenSigTimeoutTime_HU_High_X445" SG_ 505 BCmMoodLightIceBlueColorSelOnHU 0;
BA_ "GenSigTimeoutTime_HU_Mid_X445" SG_ 505 BCmMoodLightIceBlueColorSelOnHU 0;
BA_ "GenSigTimeoutMsg_IVI" SG_ 505 BCmMoodLightIceBlueColorSelOnHU 0;
BA_ "GenSigTimeoutTime_IVI" SG_ 505 BCmMoodLightIceBlueColorSelOnHU 0;
BA_ "GenSigTimeoutTime_HU_Mid_X451" SG_ 505 BCmMoodLightTuscanRedColorSelOnH 0;
BA_ "GenSigTimeoutTime_HU_High_X451" SG_ 505 BCmMoodLightTuscanRedColorSelOnH 0;
BA_ "GenSigTimeoutTime_HU_B" SG_ 505 BCmMoodLightTuscanRedColorSelOnH 0;
BA_ "GenSigTimeoutTime_HU_A" SG_ 505 BCmMoodLightTuscanRedColorSelOnH 0;
BA_ "GenSigTimeoutMsg_HU_Mid_X451" SG_ 505 BCmMoodLightTuscanRedColorSelOnH 0;
BA_ "GenSigTimeoutMsg_HU_High_X451" SG_ 505 BCmMoodLightTuscanRedColorSelOnH 0;
BA_ "GenSigTimeoutMsg_HU_B" SG_ 505 BCmMoodLightTuscanRedColorSelOnH 0;
BA_ "GenSigTimeoutMsg_HU_A" SG_ 505 BCmMoodLightTuscanRedColorSelOnH 0;
BA_ "GenSigSendType" SG_ 505 BCmMoodLightTuscanRedColorSelOnH 1;
BA_ "GenSigTimeoutMsg_HU_High_X445" SG_ 505 BCmMoodLightTuscanRedColorSelOnH 0;
BA_ "GenSigTimeoutMsg_HU_Mid_X445" SG_ 505 BCmMoodLightTuscanRedColorSelOnH 0;
BA_ "GenSigTimeoutTime_HU_High_X445" SG_ 505 BCmMoodLightTuscanRedColorSelOnH 0;
BA_ "GenSigTimeoutTime_HU_Mid_X445" SG_ 505 BCmMoodLightTuscanRedColorSelOnH 0;
BA_ "GenSigTimeoutMsg_IVI" SG_ 505 BCmMoodLightTuscanRedColorSelOnH 0;
BA_ "GenSigTimeoutTime_IVI" SG_ 505 BCmMoodLightTuscanRedColorSelOnH 0;
BA_ "SystemSignalLongSymbol" SG_ 505 BCmMoodLightTuscanRedColorSelOnH "BCmMoodLightTuscanRedColorSelOnHU";
BA_ "GenSigTimeoutTime_HU_Mid_X451" SG_ 505 BCmMoodLightTealGreenColorSelOnH 0;
BA_ "GenSigTimeoutTime_HU_High_X451" SG_ 505 BCmMoodLightTealGreenColorSelOnH 0;
BA_ "GenSigTimeoutTime_HU_B" SG_ 505 BCmMoodLightTealGreenColorSelOnH 0;
BA_ "GenSigTimeoutTime_HU_A" SG_ 505 BCmMoodLightTealGreenColorSelOnH 0;
BA_ "GenSigTimeoutMsg_HU_Mid_X451" SG_ 505 BCmMoodLightTealGreenColorSelOnH 0;
BA_ "GenSigTimeoutMsg_HU_High_X451" SG_ 505 BCmMoodLightTealGreenColorSelOnH 0;
BA_ "GenSigTimeoutMsg_HU_B" SG_ 505 BCmMoodLightTealGreenColorSelOnH 0;
BA_ "GenSigTimeoutMsg_HU_A" SG_ 505 BCmMoodLightTealGreenColorSelOnH 0;
BA_ "GenSigSendType" SG_ 505 BCmMoodLightTealGreenColorSelOnH 1;
BA_ "GenSigTimeoutMsg_HU_High_X445" SG_ 505 BCmMoodLightTealGreenColorSelOnH 0;
BA_ "GenSigTimeoutMsg_HU_Mid_X445" SG_ 505 BCmMoodLightTealGreenColorSelOnH 0;
BA_ "GenSigTimeoutTime_HU_High_X445" SG_ 505 BCmMoodLightTealGreenColorSelOnH 0;
BA_ "GenSigTimeoutTime_HU_Mid_X445" SG_ 505 BCmMoodLightTealGreenColorSelOnH 0;
BA_ "GenSigTimeoutMsg_IVI" SG_ 505 BCmMoodLightTealGreenColorSelOnH 0;
BA_ "GenSigTimeoutTime_IVI" SG_ 505 BCmMoodLightTealGreenColorSelOnH 0;
BA_ "SystemSignalLongSymbol" SG_ 505 BCmMoodLightTealGreenColorSelOnH "BCmMoodLightTealGreenColorSelOnHU";
BA_ "GenSigTimeoutTime_HU_Mid_X451" SG_ 505 BCmMoodLightRubyRedColorSelOnHU 0;
BA_ "GenSigTimeoutTime_HU_High_X451" SG_ 505 BCmMoodLightRubyRedColorSelOnHU 0;
BA_ "GenSigTimeoutTime_HU_B" SG_ 505 BCmMoodLightRubyRedColorSelOnHU 0;
BA_ "GenSigTimeoutTime_HU_A" SG_ 505 BCmMoodLightRubyRedColorSelOnHU 0;
BA_ "GenSigTimeoutMsg_HU_Mid_X451" SG_ 505 BCmMoodLightRubyRedColorSelOnHU 0;
BA_ "GenSigTimeoutMsg_HU_High_X451" SG_ 505 BCmMoodLightRubyRedColorSelOnHU 0;
BA_ "GenSigTimeoutMsg_HU_B" SG_ 505 BCmMoodLightRubyRedColorSelOnHU 0;
BA_ "GenSigTimeoutMsg_HU_A" SG_ 505 BCmMoodLightRubyRedColorSelOnHU 0;
BA_ "GenSigSendType" SG_ 505 BCmMoodLightRubyRedColorSelOnHU 1;
BA_ "GenSigTimeoutMsg_HU_High_X445" SG_ 505 BCmMoodLightRubyRedColorSelOnHU 0;
BA_ "GenSigTimeoutMsg_HU_Mid_X445" SG_ 505 BCmMoodLightRubyRedColorSelOnHU 0;
BA_ "GenSigTimeoutTime_HU_High_X445" SG_ 505 BCmMoodLightRubyRedColorSelOnHU 0;
BA_ "GenSigTimeoutTime_HU_Mid_X445" SG_ 505 BCmMoodLightRubyRedColorSelOnHU 0;
BA_ "GenSigTimeoutMsg_IVI" SG_ 505 BCmMoodLightRubyRedColorSelOnHU 0;
BA_ "GenSigTimeoutTime_IVI" SG_ 505 BCmMoodLightRubyRedColorSelOnHU 0;
BA_ "GenSigTimeoutTime_HU_Mid_X451" SG_ 505 BCmMoodLightOrangeColorSelOnHU 0;
BA_ "GenSigTimeoutTime_HU_High_X451" SG_ 505 BCmMoodLightOrangeColorSelOnHU 0;
BA_ "GenSigTimeoutTime_HU_B" SG_ 505 BCmMoodLightOrangeColorSelOnHU 0;
BA_ "GenSigTimeoutTime_HU_A" SG_ 505 BCmMoodLightOrangeColorSelOnHU 0;
BA_ "GenSigTimeoutMsg_HU_Mid_X451" SG_ 505 BCmMoodLightOrangeColorSelOnHU 0;
BA_ "GenSigTimeoutMsg_HU_High_X451" SG_ 505 BCmMoodLightOrangeColorSelOnHU 0;
BA_ "GenSigTimeoutMsg_HU_B" SG_ 505 BCmMoodLightOrangeColorSelOnHU 0;
BA_ "GenSigTimeoutMsg_HU_A" SG_ 505 BCmMoodLightOrangeColorSelOnHU 0;
BA_ "GenSigSendType" SG_ 505 BCmMoodLightOrangeColorSelOnHU 1;
BA_ "GenSigTimeoutMsg_HU_High_X445" SG_ 505 BCmMoodLightOrangeColorSelOnHU 0;
BA_ "GenSigTimeoutMsg_HU_Mid_X445" SG_ 505 BCmMoodLightOrangeColorSelOnHU 0;
BA_ "GenSigTimeoutTime_HU_High_X445" SG_ 505 BCmMoodLightOrangeColorSelOnHU 0;
BA_ "GenSigTimeoutTime_HU_Mid_X445" SG_ 505 BCmMoodLightOrangeColorSelOnHU 0;
BA_ "GenSigTimeoutMsg_IVI" SG_ 505 BCmMoodLightOrangeColorSelOnHU 0;
BA_ "GenSigTimeoutTime_IVI" SG_ 505 BCmMoodLightOrangeColorSelOnHU 0;
BA_ "GenSigTimeoutTime_HU_Mid_X451" SG_ 505 BCmMoodLightPurpleTaupeColorSelO 0;
BA_ "GenSigTimeoutTime_HU_High_X451" SG_ 505 BCmMoodLightPurpleTaupeColorSelO 0;
BA_ "GenSigTimeoutTime_HU_B" SG_ 505 BCmMoodLightPurpleTaupeColorSelO 0;
BA_ "GenSigTimeoutTime_HU_A" SG_ 505 BCmMoodLightPurpleTaupeColorSelO 0;
BA_ "GenSigTimeoutMsg_HU_Mid_X451" SG_ 505 BCmMoodLightPurpleTaupeColorSelO 0;
BA_ "GenSigTimeoutMsg_HU_High_X451" SG_ 505 BCmMoodLightPurpleTaupeColorSelO 0;
BA_ "GenSigTimeoutMsg_HU_B" SG_ 505 BCmMoodLightPurpleTaupeColorSelO 0;
BA_ "GenSigTimeoutMsg_HU_A" SG_ 505 BCmMoodLightPurpleTaupeColorSelO 0;
BA_ "GenSigSendType" SG_ 505 BCmMoodLightPurpleTaupeColorSelO 1;
BA_ "GenSigTimeoutMsg_HU_High_X445" SG_ 505 BCmMoodLightPurpleTaupeColorSelO 0;
BA_ "GenSigTimeoutMsg_HU_Mid_X445" SG_ 505 BCmMoodLightPurpleTaupeColorSelO 0;
BA_ "GenSigTimeoutTime_HU_High_X445" SG_ 505 BCmMoodLightPurpleTaupeColorSelO 0;
BA_ "GenSigTimeoutTime_HU_Mid_X445" SG_ 505 BCmMoodLightPurpleTaupeColorSelO 0;
BA_ "GenSigTimeoutMsg_IVI" SG_ 505 BCmMoodLightPurpleTaupeColorSelO 0;
BA_ "GenSigTimeoutTime_IVI" SG_ 505 BCmMoodLightPurpleTaupeColorSelO 0;
BA_ "SystemSignalLongSymbol" SG_ 505 BCmMoodLightPurpleTaupeColorSelO "BCmMoodLightPurpleTaupeColorSelOnHU";
BA_ "GenSigTimeoutTime_HU_Mid_X451" SG_ 505 BCmMoodLightLocationSel 0;
BA_ "GenSigTimeoutTime_HU_High_X451" SG_ 505 BCmMoodLightLocationSel 0;
BA_ "GenSigTimeoutTime_HU_B" SG_ 505 BCmMoodLightLocationSel 0;
BA_ "GenSigTimeoutTime_HU_A" SG_ 505 BCmMoodLightLocationSel 0;
BA_ "GenSigTimeoutMsg_HU_Mid_X451" SG_ 505 BCmMoodLightLocationSel 0;
BA_ "GenSigTimeoutMsg_HU_High_X451" SG_ 505 BCmMoodLightLocationSel 0;
BA_ "GenSigTimeoutMsg_HU_B" SG_ 505 BCmMoodLightLocationSel 0;
BA_ "GenSigTimeoutMsg_HU_A" SG_ 505 BCmMoodLightLocationSel 0;
BA_ "GenSigSendType" SG_ 505 BCmMoodLightLocationSel 1;
BA_ "GenSigTimeoutMsg_HU_High_X445" SG_ 505 BCmMoodLightLocationSel 0;
BA_ "GenSigTimeoutMsg_HU_Mid_X445" SG_ 505 BCmMoodLightLocationSel 0;
BA_ "GenSigTimeoutTime_HU_High_X445" SG_ 505 BCmMoodLightLocationSel 0;
BA_ "GenSigTimeoutTime_HU_Mid_X445" SG_ 505 BCmMoodLightLocationSel 0;
BA_ "GenSigTimeoutMsg_IVI" SG_ 505 BCmMoodLightLocationSel 0;
BA_ "GenSigTimeoutTime_IVI" SG_ 505 BCmMoodLightLocationSel 0;
BA_ "GenSigTimeoutTime_HU_Mid_X451" SG_ 505 BCmMoodLightAllAreaSelOnHU 0;
BA_ "GenSigTimeoutTime_HU_High_X451" SG_ 505 BCmMoodLightAllAreaSelOnHU 0;
BA_ "GenSigTimeoutTime_HU_B" SG_ 505 BCmMoodLightAllAreaSelOnHU 0;
BA_ "GenSigTimeoutTime_HU_A" SG_ 505 BCmMoodLightAllAreaSelOnHU 0;
BA_ "GenSigTimeoutMsg_HU_Mid_X451" SG_ 505 BCmMoodLightAllAreaSelOnHU 0;
BA_ "GenSigTimeoutMsg_HU_High_X451" SG_ 505 BCmMoodLightAllAreaSelOnHU 0;
BA_ "GenSigTimeoutMsg_HU_B" SG_ 505 BCmMoodLightAllAreaSelOnHU 0;
BA_ "GenSigTimeoutMsg_HU_A" SG_ 505 BCmMoodLightAllAreaSelOnHU 0;
BA_ "GenSigSendType" SG_ 505 BCmMoodLightAllAreaSelOnHU 1;
BA_ "GenSigTimeoutMsg_HU_High_X445" SG_ 505 BCmMoodLightAllAreaSelOnHU 0;
BA_ "GenSigTimeoutMsg_HU_Mid_X445" SG_ 505 BCmMoodLightAllAreaSelOnHU 0;
BA_ "GenSigTimeoutTime_HU_High_X445" SG_ 505 BCmMoodLightAllAreaSelOnHU 0;
BA_ "GenSigTimeoutTime_HU_Mid_X445" SG_ 505 BCmMoodLightAllAreaSelOnHU 0;
BA_ "GenSigTimeoutMsg_IVI" SG_ 505 BCmMoodLightAllAreaSelOnHU 0;
BA_ "GenSigTimeoutTime_IVI" SG_ 505 BCmMoodLightAllAreaSelOnHU 0;
BA_ "GenSigTimeoutTime_HU_Mid_X451" SG_ 505 BCmMoodLightFrontLHAreaSelOnHU 0;
BA_ "GenSigTimeoutTime_HU_High_X451" SG_ 505 BCmMoodLightFrontLHAreaSelOnHU 0;
BA_ "GenSigTimeoutTime_HU_B" SG_ 505 BCmMoodLightFrontLHAreaSelOnHU 0;
BA_ "GenSigTimeoutTime_HU_A" SG_ 505 BCmMoodLightFrontLHAreaSelOnHU 0;
BA_ "GenSigTimeoutMsg_HU_Mid_X451" SG_ 505 BCmMoodLightFrontLHAreaSelOnHU 0;
BA_ "GenSigTimeoutMsg_HU_High_X451" SG_ 505 BCmMoodLightFrontLHAreaSelOnHU 0;
BA_ "GenSigTimeoutMsg_HU_B" SG_ 505 BCmMoodLightFrontLHAreaSelOnHU 0;
BA_ "GenSigTimeoutMsg_HU_A" SG_ 505 BCmMoodLightFrontLHAreaSelOnHU 0;
BA_ "GenSigSendType" SG_ 505 BCmMoodLightFrontLHAreaSelOnHU 1;
BA_ "GenSigTimeoutMsg_HU_High_X445" SG_ 505 BCmMoodLightFrontLHAreaSelOnHU 0;
BA_ "GenSigTimeoutMsg_HU_Mid_X445" SG_ 505 BCmMoodLightFrontLHAreaSelOnHU 0;
BA_ "GenSigTimeoutTime_HU_High_X445" SG_ 505 BCmMoodLightFrontLHAreaSelOnHU 0;
BA_ "GenSigTimeoutTime_HU_Mid_X445" SG_ 505 BCmMoodLightFrontLHAreaSelOnHU 0;
BA_ "GenSigTimeoutMsg_IVI" SG_ 505 BCmMoodLightFrontLHAreaSelOnHU 0;
BA_ "GenSigTimeoutTime_IVI" SG_ 505 BCmMoodLightFrontLHAreaSelOnHU 0;
BA_ "GenSigTimeoutTime_HU_Mid_X451" SG_ 505 BCmMoodLightRearAreaSelOnHU 0;
BA_ "GenSigTimeoutTime_HU_High_X451" SG_ 505 BCmMoodLightRearAreaSelOnHU 0;
BA_ "GenSigTimeoutTime_HU_B" SG_ 505 BCmMoodLightRearAreaSelOnHU 0;
BA_ "GenSigTimeoutTime_HU_A" SG_ 505 BCmMoodLightRearAreaSelOnHU 0;
BA_ "GenSigTimeoutMsg_HU_Mid_X451" SG_ 505 BCmMoodLightRearAreaSelOnHU 0;
BA_ "GenSigTimeoutMsg_HU_High_X451" SG_ 505 BCmMoodLightRearAreaSelOnHU 0;
BA_ "GenSigTimeoutMsg_HU_B" SG_ 505 BCmMoodLightRearAreaSelOnHU 0;
BA_ "GenSigTimeoutMsg_HU_A" SG_ 505 BCmMoodLightRearAreaSelOnHU 0;
BA_ "GenSigSendType" SG_ 505 BCmMoodLightRearAreaSelOnHU 1;
BA_ "GenSigTimeoutMsg_HU_High_X445" SG_ 505 BCmMoodLightRearAreaSelOnHU 0;
BA_ "GenSigTimeoutMsg_HU_Mid_X445" SG_ 505 BCmMoodLightRearAreaSelOnHU 0;
BA_ "GenSigTimeoutTime_HU_High_X445" SG_ 505 BCmMoodLightRearAreaSelOnHU 0;
BA_ "GenSigTimeoutTime_HU_Mid_X445" SG_ 505 BCmMoodLightRearAreaSelOnHU 0;
BA_ "GenSigTimeoutMsg_IVI" SG_ 505 BCmMoodLightRearAreaSelOnHU 0;
BA_ "GenSigTimeoutTime_IVI" SG_ 505 BCmMoodLightRearAreaSelOnHU 0;
BA_ "GenSigTimeoutTime_HU_Mid_X451" SG_ 505 BCmMoodLightFloorConsoleAreaSelO 0;
BA_ "GenSigTimeoutTime_HU_High_X451" SG_ 505 BCmMoodLightFloorConsoleAreaSelO 0;
BA_ "GenSigTimeoutTime_HU_B" SG_ 505 BCmMoodLightFloorConsoleAreaSelO 0;
BA_ "GenSigTimeoutTime_HU_A" SG_ 505 BCmMoodLightFloorConsoleAreaSelO 0;
BA_ "GenSigTimeoutMsg_HU_Mid_X451" SG_ 505 BCmMoodLightFloorConsoleAreaSelO 0;
BA_ "GenSigTimeoutMsg_HU_High_X451" SG_ 505 BCmMoodLightFloorConsoleAreaSelO 0;
BA_ "GenSigTimeoutMsg_HU_B" SG_ 505 BCmMoodLightFloorConsoleAreaSelO 0;
BA_ "GenSigTimeoutMsg_HU_A" SG_ 505 BCmMoodLightFloorConsoleAreaSelO 0;
BA_ "GenSigSendType" SG_ 505 BCmMoodLightFloorConsoleAreaSelO 1;
BA_ "GenSigTimeoutMsg_HU_High_X445" SG_ 505 BCmMoodLightFloorConsoleAreaSelO 0;
BA_ "GenSigTimeoutMsg_HU_Mid_X445" SG_ 505 BCmMoodLightFloorConsoleAreaSelO 0;
BA_ "GenSigTimeoutTime_HU_High_X445" SG_ 505 BCmMoodLightFloorConsoleAreaSelO 0;
BA_ "GenSigTimeoutTime_HU_Mid_X445" SG_ 505 BCmMoodLightFloorConsoleAreaSelO 0;
BA_ "GenSigTimeoutMsg_IVI" SG_ 505 BCmMoodLightFloorConsoleAreaSelO 0;
BA_ "GenSigTimeoutTime_IVI" SG_ 505 BCmMoodLightFloorConsoleAreaSelO 0;
BA_ "SystemSignalLongSymbol" SG_ 505 BCmMoodLightFloorConsoleAreaSelO "BCmMoodLightFloorConsoleAreaSelOnHU";
BA_ "GenSigTimeoutTime_HU_Mid_X451" SG_ 505 BCmMoodLightState 0;
BA_ "GenSigTimeoutTime_HU_High_X451" SG_ 505 BCmMoodLightState 0;
BA_ "GenSigTimeoutTime_HU_B" SG_ 505 BCmMoodLightState 0;
BA_ "GenSigTimeoutTime_HU_A" SG_ 505 BCmMoodLightState 0;
BA_ "GenSigTimeoutMsg_HU_Mid_X451" SG_ 505 BCmMoodLightState 0;
BA_ "GenSigTimeoutMsg_HU_High_X451" SG_ 505 BCmMoodLightState 0;
BA_ "GenSigTimeoutMsg_HU_B" SG_ 505 BCmMoodLightState 0;
BA_ "GenSigTimeoutMsg_HU_A" SG_ 505 BCmMoodLightState 0;
BA_ "GenSigSendType" SG_ 505 BCmMoodLightState 1;
BA_ "GenSigTimeoutMsg_HU_High_X445" SG_ 505 BCmMoodLightState 0;
BA_ "GenSigTimeoutMsg_HU_Mid_X445" SG_ 505 BCmMoodLightState 0;
BA_ "GenSigTimeoutTime_HU_High_X445" SG_ 505 BCmMoodLightState 0;
BA_ "GenSigTimeoutTime_HU_Mid_X445" SG_ 505 BCmMoodLightState 0;
BA_ "GenSigTimeoutMsg_IVI" SG_ 505 BCmMoodLightState 0;
BA_ "GenSigTimeoutTime_IVI" SG_ 505 BCmMoodLightState 0;
BA_ "GenSigTimeoutTime_HU_Mid_X451" SG_ 505 BCmMoodLightFrontRHAreaSelOnHU 0;
BA_ "GenSigTimeoutTime_HU_High_X451" SG_ 505 BCmMoodLightFrontRHAreaSelOnHU 0;
BA_ "GenSigTimeoutTime_HU_B" SG_ 505 BCmMoodLightFrontRHAreaSelOnHU 0;
BA_ "GenSigTimeoutTime_HU_A" SG_ 505 BCmMoodLightFrontRHAreaSelOnHU 0;
BA_ "GenSigTimeoutMsg_HU_Mid_X451" SG_ 505 BCmMoodLightFrontRHAreaSelOnHU 0;
BA_ "GenSigTimeoutMsg_HU_High_X451" SG_ 505 BCmMoodLightFrontRHAreaSelOnHU 0;
BA_ "GenSigTimeoutMsg_HU_B" SG_ 505 BCmMoodLightFrontRHAreaSelOnHU 0;
BA_ "GenSigTimeoutMsg_HU_A" SG_ 505 BCmMoodLightFrontRHAreaSelOnHU 0;
BA_ "GenSigSendType" SG_ 505 BCmMoodLightFrontRHAreaSelOnHU 1;
BA_ "GenSigTimeoutMsg_HU_High_X445" SG_ 505 BCmMoodLightFrontRHAreaSelOnHU 0;
BA_ "GenSigTimeoutMsg_HU_Mid_X445" SG_ 505 BCmMoodLightFrontRHAreaSelOnHU 0;
BA_ "GenSigTimeoutTime_HU_High_X445" SG_ 505 BCmMoodLightFrontRHAreaSelOnHU 0;
BA_ "GenSigTimeoutTime_HU_Mid_X445" SG_ 505 BCmMoodLightFrontRHAreaSelOnHU 0;
BA_ "GenSigTimeoutMsg_IVI" SG_ 505 BCmMoodLightFrontRHAreaSelOnHU 0;
BA_ "GenSigTimeoutTime_IVI" SG_ 505 BCmMoodLightFrontRHAreaSelOnHU 0;
VAL_ 475 HuIcAlertFeatureTypeAck 3 "Reserved" 2 "Reserved" 1 "Voice & Text" 0 "Text Only" ;
VAL_ 475 HuIcAlertFeaturePresenceAck 1 "Present" 0 "Not Present" ;
VAL_ 476 HuIcVoiceAlertFeaturePresence 1 "Present" 0 "Not Present" ;
VAL_ 476 HuIcVoiceAlertSelectionState 1 "Enabled" 0 "Disabled" ;
VAL_ 476 HuIcTextAlertSelectionState 1 "Enabled" 0 "Disabled" ;
VAL_ 477 IcHuVoiceAlertSelectionState 1 "Enabled" 0 "Disabled" ;
VAL_ 477 IcHuAlertFeatureType 3 "Reserved" 2 "Reserved" 1 "Voice & Text" 0 "Text Only" ;
VAL_ 477 IcHuAlertFeaturePresence 1 "Present" 0 "Not Present" ;
VAL_ 478 IcHuVoiceAlertFeaturePresenceAck 1 "Present" 0 "Not Present" ;
VAL_ 478 IcHuVoiceAlertSelectionStateAck 1 "Enabled" 0 "Disabled" ;
VAL_ 478 IcHuTextAlertSelectionStateAck 1 "Enabled" 0 "Disabled" ;
VAL_ 479 IcHuDriveproConfigAck 3 "Reserved" 2 "Reserved" 1 "DrivePro Present" 0 "DrivePro Not Present" ;
VAL_ 479 IcHuDriveProConfigAckEventStatus 1 "Config Ack Event" 0 "No Event" ;
VAL_ 479 IcHuTripAReset 1 "Yes" 0 "No" ;
VAL_ 479 IcHuTripAResetAck 1 "Yes" 0 "No" ;
VAL_ 479 IcHuTripBReset 1 "Yes" 0 "No" ;
VAL_ 479 IcHuTripBResetAck 1 "Yes" 0 "No" ;
VAL_ 479 IcHuResetAllAck 1 "Yes" 0 "No" ;
VAL_ 479 IcHuTripResetAckEventStatus 1 "ResetAck Event" 0 "No Event" ;
VAL_ 479 IcHuTripResetEventStatus 1 "Reset Event" 0 "No Event" ;
VAL_ 479 IcHuOverallTripResetAck 1 "Yes" 0 "No" ;
VAL_ 479 IcHuOverallTripReset 1 "Yes" 0 "No" ;
VAL_ 479 IcHuResetAll 1 "Yes" 0 "No" ;
VAL_ 480 UIDAuthState 3 "Key is outside" 2 "Key is inside" 1 "Reserved for future use." 0 "Authentication not success" ;
VAL_ 484 UnLockTailgageCommand 1 "Execute Tailgate Unlock" 0 "No Unlock" ;
VAL_ 484 UnLockAllDoorCommand 1 "Execute all door unlock" 0 "No Unlock" ;
VAL_ 484 UnLockDrDoorCommandStatus 3 "Signal is not available" 2 "Reserved" 1 "Reserved" 0 "Signal is plausible" ;
VAL_ 484 UnLockDrDoorCommand 1 "Execute Driver Door Unlock" 0 "No UnLock" ;
VAL_ 484 VehicleLockCommandStatus 3 "Signal is not available" 2 "Reserved" 1 "Reserved" 0 "Plausible-Information is correct and according to specification" ;
VAL_ 484 VehicleLockCommand 1 "Execute Lock" 0 "No lock" ;
VAL_ 484 ForcePanicCommand 1 "ON" 0 "OFF" ;
VAL_ 484 ApproachLighCommandStatus 3 "Signal is not available" 2 "Reserved" 1 "Reserved" 0 "Signal is Plausible" ;
VAL_ 484 ApproachLighCommand 1 "ON" 0 "OFF" ;
VAL_ 484 UnLockTailgageCommandStatus 3 "Signal is not available" 2 "Reserved" 1 "Reserved" 0 "Signal is plausible" ;
VAL_ 484 UnLockAllDoorCommandStatus 3 "Signal is not available" 2 "Reserved" 1 "Reserved" 0 "Signal is plausible" ;
VAL_ 484 WindowUpCommandStatus 3 "Singal is not available" 2 "Reserved" 1 "Reserved" 0 "Signal is plausible" ;
VAL_ 484 WindowUpCommand 1 "Execute Window Close" 0 "No Windows Close" ;
VAL_ 484 WindowDownCommandStatus 3 "Singal is not available" 2 "Reserved" 1 "Reserved" 0 "Signal is plausible" ;
VAL_ 484 WindowDownCommand 1 "Execute Window Down" 0 "No Window Down" ;
VAL_ 484 ForcePanicCommandStatus 3 "Signal is not available" 2 "Reserved" 1 "Reserved" 0 "Signal is plausible" ;
VAL_ 484 VehicleSeekCommandStatus 3 "Signal is not available" 2 "Reserved" 1 "Reserved" 0 "Signal is Plausible" ;
VAL_ 484 VehicleSeekCommand 1 "ON" 0 "OFF" ;
VAL_ 485 CoDriverDHsSwPressState 3 "Reserved for future use" 2 "Stuck" 1 "Pressed" 0 "Not Pressed" ;
VAL_ 485 CoDriverDHsSwPressStateStatus 3 "Signal Not Available" 2 "Reserved for future use" 1 "Reserved for future use" 0 "Signal value is plausible" ;
VAL_ 485 DriverDHsSwPressState 3 "Reserved for future use" 2 "Stuck" 1 "Pressed" 0 "Not Pressed" ;
VAL_ 485 DriverDHsSwPressStateStatus 3 "Signal Not Available" 2 "Reserved for future use" 1 "Reserved for future use" 0 "Signal value is plausible" ;
VAL_ 485 RearRhDHsSwPressState 3 "Reserved for future use" 2 "Stuck" 1 "Pressed" 0 "Not Pressed" ;
VAL_ 485 RearRhDHsSwPressStateStatus 3 "Signal Not Available" 2 "Reserved for future use" 1 "Reserved for future use" 0 "Signal value is plausible" ;
VAL_ 485 RearLhDHsSwPressState 3 "Reserved for future use" 2 "Stuck" 1 "Pressed" 0 "Not Pressed" ;
VAL_ 485 RearLhDHsSwPressStateStatus 3 "Signal Not Available" 2 "Reserved for future use" 1 "Reserved for future use" 0 "Signal value is plausible" ;
VAL_ 485 RfLockUnlockPEPs 7 "Reserved for future use" 6 "Reserved for future use" 5 "Reserved for future use" 4 "Reserved for future use" 3 "RF Tailgate Unlock" 2 "RF Lock" 1 "RF Unlock" 0 "No RF Lock or Unlock Command" ;
VAL_ 485 RfLockUnlockPEPsStatus 3 "Signal Not Available" 2 "Reserved for future use" 1 "Reserved for future use" 0 "Signal value is plausible" ;
VAL_ 485 TailgateSwPressState 3 "Reserved for future use" 2 "Stuck" 1 "Pressed" 0 "Not Pressed" ;
VAL_ 485 TailgateSwPressStateStatus 3 "Signal Not Available" 2 "Reserved for future use" 1 "Reserved for future use" 0 "Signal value is plausible" ;
VAL_ 485 UIdLocationPEPs 7 "Reserved for future use" 6 "Reserved for future use" 5 "Inside the Vehicle In Trunk Area" 4 "Inside the Vehicle Except Trunk Area" 3 "Outside In Tailgate Vicinity" 2 "Outside In Co-Driver Side Vicinity" 1 "Outside In Driver Side Vicinity" 0 "UID Not Detected" ;
VAL_ 485 UIdLocationPEPsStatus 3 "Signal Not Available" 2 "Reserved for future use" 1 "Reserved for future use" 0 "Signal value is plausible" ;
VAL_ 497 HuCcmExpressCoolSwitchReq 1 "Express Cool  ON" 0 "Express Cool  OFF" ;
VAL_ 497 HuCCmFanSpdReq 15 "Reserved" 14 "Reserved" 13 "Reserved" 12 "Reserved" 11 "Reserved" 10 "Reserved" 9 "Reserved" 8 "Reserved" 7 "Speed 7" 6 "Speed 6" 5 "Speed 5" 4 "Speed 4" 3 "Speed 3" 2 "Speed 2" 1 "Speed 1" 0 "Speed0(only for FATC dual)/unused (ETC and FATC)" ;
VAL_ 497 HuCCmDistribReq 7 "Reserved" 6 "Reserved" 5 "DefrostMode Status" 4 "LegDefrostMode Status" 3 "LegMode Status" 2 "Chest-LegMode Status" 1 "ChestModeStatus" 0 "Reserved" ;
VAL_ 497 HuCCmDualModeReq 1 "Dual Mode ON" 0 "Dual Mode OFF" ;
VAL_ 497 HuCCmTempReqPass 31 "HI" 30 "Reserved" 29 "30 Deg C" 28 "29.5 Deg C" 27 "29 Deg C" 26 "28.5 Deg C" 25 "28 Deg C" 24 "27.5 Deg C" 23 "27 Deg C" 22 "26.5 Deg C" 21 "26 Deg C" 20 "25.5 Deg C" 19 "25 Deg C" 18 "24.5 Deg C" 17 "24 Deg C" 16 "23.5 Deg C" 15 "23 Deg C" 14 "22.5 Deg C" 13 "22 Deg C" 12 "21.5 Deg C" 11 "21 Deg C" 10 "20.5 Deg C" 9 "20 Deg C" 8 "19.5 Deg C" 7 "19 Deg C" 6 "18.5 Deg C" 5 "18 Deg C" 4 "17.5 Deg C" 3 "17 Deg C" 2 "16.5 Deg C" 1 "16 Deg C" 0 "LO" ;
VAL_ 497 HuCCmFreshAirRecircReq 3 "Reserved" 2 "Fresh Air ON" 1 "Recirculation with AQS (applicable for dual zone FATC)" 0 "Recirculation ON" ;
VAL_ 497 HuCCmAutoReq 1 "Auto ON" 0 "Auto OFF" ;
VAL_ 497 HuCCmTempReq 31 "HI" 30 "Reserved" 29 "30 Deg C" 28 "29.5 Deg C" 27 "29 Deg C" 26 "28.5 Deg C" 25 "28 Deg C" 24 "27.5 Deg C" 23 "27 Deg C" 22 "26.5 Deg C" 21 "26 Deg C" 20 "25.5 Deg C" 19 "25 Deg C" 18 "24.5 Deg C" 17 "24 Deg C" 16 "23.5 Deg C" 15 "23 Deg C" 14 "22.5 Deg C" 13 "22 Deg C" 12 "21.5 Deg C" 11 "21 Deg C" 10 "20.5 Deg C" 9 "20 Deg C" 8 "19.5 Deg C" 7 "19 Deg C" 6 "18.5 Deg C" 5 "18 Deg C" 4 "17.5 Deg C" 3 "17 Deg C" 2 "16.5 Deg C" 1 "16 Deg C" 0 "LO" ;
VAL_ 497 HuCCmEconModeReq 1 "Economy ON" 0 "Economy OFF" ;
VAL_ 497 HuCCmMaxDefrstReq 1 "Max defrost ON" 0 "Max defrost OFF" ;
VAL_ 497 HuCCmRearDefogReq 1 "Rear defog is ON" 0 "Rear defog is OFF" ;
VAL_ 497 HuCCmTempReqDrvr 31 "HI" 30 "Reserved" 29 "30 Deg C" 28 "29.5 Deg C" 27 "29 Deg C" 26 "28.5 Deg C" 25 "28 Deg C" 24 "27.5 Deg C" 23 "27 Deg C" 22 "26.5 Deg C" 21 "26 Deg C" 20 "25.5 Deg C" 19 "25 Deg C" 18 "24.5 Deg C" 17 "24 Deg C" 16 "23.5 Deg C" 15 "23 Deg C" 14 "22.5 Deg C" 13 "22 Deg C" 12 "21.5 Deg C" 11 "21 Deg C" 10 "20.5 Deg C" 9 "20 Deg C" 8 "19.5 Deg C" 7 "19 Deg C" 6 "18.5 Deg C" 5 "18 Deg C" 4 "17.5 Deg C" 3 "17 Deg C" 2 "16.5 Deg C" 1 "16 Deg C" 0 "LO" ;
VAL_ 497 HuCCmAirConCompReq 1 "AC is ON" 0 "AC is OFF" ;
VAL_ 497 HuCCmHVAcOFFReq 1 "Control panel ON" 0 "Control panel OFF" ;
VAL_ 497 HuCCmQueryFlag 1 "Query" 0 "No Query" ;
VAL_ 497 HuCCmUserInterventionStatusFlag 31 "Reserved" 30 "Reserved" 29 "Reserved" 28 "Reserved" 27 "Reserved" 26 "Reserved" 25 "Reserved" 24 "Reserved" 23 "Reserved" 22 "Reserved" 21 "Reserved" 20 "Reserved" 19 "Reserved" 18 "Rear Blower Flag" 17 "Reserved" 16 "Reserved" 15 "Reserved" 14 "Express Cool Flag" 13 "Rear defog Flag" 12 "Temperature Wheel  flag" 11 "Dual button flag" 10 "Fan speed wheel flag" 9 "Temperature Wheel driver flag" 8 "Temperature Wheel Passenger flag" 7 "Distribution button flag" 6 "Recirculation button flag" 5 "Maxdefrost button flag" 4 "Off button flag" 3 "Auto button flag" 2 "Econ button flag" 1 "AC Button flag" 0 "HuCCmUserInterventionStatusFlagClear" ;
VAL_ 499 CCmHuFanSpdAck 1 "Updated" 0 "Not Updated" ;
VAL_ 499 CCmHuDistribSwitchAck 1 "Updated" 0 "Not Updated" ;
VAL_ 499 CCmHuMaxDefrstSwitchAck 1 "Updated" 0 "Not Updated" ;
VAL_ 499 CCmHuEconModeSwitchAck 1 "Updated" 0 "Not Updated" ;
VAL_ 499 CCmHuAutoSwitchAck 1 "Updated" 0 "Not Updated" ;
VAL_ 499 CCmHuRearDefogSwitchAck 1 "Updated" 0 "Not Updated" ;
VAL_ 499 CCmHuAirConCompSwitchAck 1 "Updated" 0 "Not Updated" ;
VAL_ 499 CCmHuErrAck 1 "Updated" 0 "Not updated" ;
VAL_ 499 CCmHuTempWhlAck 1 "Updated" 0 "Not Updated" ;
VAL_ 499 CCmHuFreshAirRecircSwitchAck 1 "Updated" 0 "Not Updated" ;
VAL_ 499 CCmHuDualModeSwitchAck 1 "Updated" 0 "Not Updated" ;
VAL_ 499 CCmHuTempWhlPassAck 1 "Updated" 0 "Not Updated" ;
VAL_ 499 CCmHuTempWhlDrvrAck 1 "Updated" 0 "Not Updated" ;
VAL_ 500 CCmHuSwitchStatusStuckWarn 31 "Reserved
" 30 "Reserved
" 29 "Reserved" 28 "Reserved" 27 "Reserved
" 26 "Reserved" 25 "Reserved" 24 "Reserved" 23 "Reserved" 22 "Reserved
" 21 "Reserved" 20 "Reserved" 19 "Reserved" 18 "Reserved" 17 "Reserved" 16 "Reserved
" 15 "Reserved" 14 "Reserved" 13 "Reserved" 12 "Reserved" 11 "Reserved" 10 "Reserved" 9 "Rear defog stuck" 8 "Distribution button stuck" 7 "Recirculation button stuck" 6 "Maxdefrost button stuck" 5 "Dual button stuck" 4 "Off button stuck" 3 "Auto button stuck
" 2 "Econ button stuck" 1 "AC Button stuck" 0 "CCmHuSwitchStatusStuckWarnClear" ;
VAL_ 500 CCmHuQueryFlag 1 "Query" 0 "No Query" ;
VAL_ 500 CCmHuFanControlDuringVR 3 "Reserved" 2 "Available" 1 "Not Available" 0 "Reserved" ;
VAL_ 504 BCmAutoRelockActiveSignalVal 1 "Active value for Auto Relock feature is Enabled " 0 "Active value for Auto Relock feature is Disabled " ;
VAL_ 504 BCmFMhActiveSignalVal 3 "Reserved" 2 "Active value is BCmFMhSignalVal3" 1 "Active value is BCmFMhSignalVal2" 0 "Active value is BCmFMhSignalVal1" ;
VAL_ 504 BCmFMhSignalVal1 31 "Reserved" 30 "Reserved" 29 "Reserved" 28 "Reserved" 27 "Reserved" 26 "Reserved" 25 "Reserved" 24 "Possible value selected is 240" 23 "Possible value selected is 230" 22 "Possible value selected is 220" 21 "Possible value selected is 210" 20 "Possible value selected is 200" 19 "Possible value selected is 190" 18 "Possible value selected is 180" 17 "Possible value selected is 170" 16 "Possible value selected is 160" 15 "Possible value selected is 150" 14 "Possible value selected is 140" 13 "Possible value selected is 130" 12 "Possible value selected is 120" 11 "Possible value selected is 110" 10 "Possible value selected is 100" 9 "Possible value selected is 90" 8 "Possible value selected is 80" 7 "Possible value selected is 70" 6 "Possible value selected is 60" 5 "Possible value selected is 50" 4 "Possible value selected is 40" 3 "Possible value selected is 30" 2 "Possible value selected is 20" 1 "Possible value selected is 10" 0 "Possible value selected is 0" ;
VAL_ 504 BCmVehLockHornReqActiveSignalVal 1 "Active value for vehicle Lock Horn Request feature is ON" 0 "Active value for vehicle Lock Horn Request feature is OFF" ;
VAL_ 504 BCmApproachLampActiveSignalVal 3 "Reserved" 2 "Active value is BCmApproachLampSignalVal3" 1 "Active value is BCmApproachLampSignalVal2" 0 "Active value is BCmApproachLampSignalVal1" ;
VAL_ 504 BCmFMhSignalVal2 31 "Reserved" 30 "Reserved" 29 "Reserved" 28 "Reserved" 27 "Reserved" 26 "Reserved" 25 "Reserved" 24 "Possible value selected is 240" 23 "Possible value selected is 230" 22 "Possible value selected is 220" 21 "Possible value selected is 210" 20 "Possible value selected is 200" 19 "Possible value selected is 190" 18 "Possible value selected is 180" 17 "Possible value selected is 170" 16 "Possible value selected is 160" 15 "Possible value selected is 150" 14 "Possible value selected is 140" 13 "Possible value selected is 130" 12 "Possible value selected is 120" 11 "Possible value selected is 110" 10 "Possible value selected is 100" 9 "Possible value selected is 90" 8 "Possible value selected is 80" 7 "Possible value selected is 70" 6 "Possible value selected is 60" 5 "Possible value selected is 50" 4 "Possible value selected is 40" 3 "Possible value selected is 30" 2 "Possible value selected is 20" 1 "Possible value selected is 10" 0 "Possible value selected is 0" ;
VAL_ 504 BCmDriveAwayLockingActiveSignalV 1 "Active value for Drive Away Locking feature is Enabled" 0 "Active value for Drive Away Locking feature is Disabled" ;
VAL_ 504 BCmRKeUnlockState 1 "Vehicle unlock feature with RKE is enabled in BCM" 0 "Vehicle unlock feature with RKE is disabled in BCM" ;
VAL_ 504 BCmPKeUnlockState 1 "Vehicle unlock feature with PKE is enabled in BCM" 0 "Vehicle unlock feature with PKE is disabled in BCM" ;
VAL_ 504 BCmFMhSignalVal3 31 "Reserved" 30 "Reserved" 29 "Reserved" 28 "Reserved" 27 "Reserved" 26 "Reserved" 25 "Reserved" 24 "Possible value selected is 240" 23 "Possible value selected is 230" 22 "Possible value selected is 220" 21 "Possible value selected is 210" 20 "Possible value selected is 200" 19 "Possible value selected is 190" 18 "Possible value selected is 180" 17 "Possible value selected is 170" 16 "Possible value selected is 160" 15 "Possible value selected is 150" 14 "Possible value selected is 140" 13 "Possible value selected is 130" 12 "Possible value selected is 120" 11 "Possible value selected is 110" 10 "Possible value selected is 100" 9 "Possible value selected is 90" 8 "Possible value selected is 80" 7 "Possible value selected is 70" 6 "Possible value selected is 60" 5 "Possible value selected is 50" 4 "Possible value selected is 40" 3 "Possible value selected is 30" 2 "Possible value selected is 20" 1 "Possible value selected is 10" 0 "Possible value selected is 0" ;
VAL_ 504 BCmAutoRelockState 1 "Auto Relock feature is enabled in BCM" 0 "Auto Relock feature is disabled in BCM" ;
VAL_ 504 BCmFMhState 1 "FMH feature is enabled in BCM" 0 "FMH feature is disabled in BCM" ;
VAL_ 504 BCmUCsState 1 "UCS State Enabled" 0 "UCS State Disabled" ;
VAL_ 504 BCmApproachLampSignalVal1 31 "Reserved" 30 "Reserved" 29 "Reserved" 28 "Reserved" 27 "Reserved" 26 "Reserved" 25 "Reserved" 24 "Possible value selected is 240" 23 "Possible value selected is 230" 22 "Possible value selected is 220" 21 "Possible value selected is 210" 20 "Possible value selected is 200" 19 "Possible value selected is 190" 18 "Possible value selected is 180" 17 "Possible value selected is 170" 16 "Possible value selected is 160" 15 "Possible value selected is 150" 14 "Possible value selected is 140" 13 "Possible value selected is 130" 12 "Possible value selected is 120" 11 "Possible value selected is 110" 10 "Possible value selected is 100" 9 "Possible value selected is 90" 8 "Possible value selected is 80" 7 "Possible value selected is 70" 6 "Possible value selected is 60" 5 "Possible value selected is 50" 4 "Possible value selected is 40" 3 "Possible value selected is 30" 2 "Possible value selected is 20" 1 "Possible value selected is 10" 0 "Possible value selected is 0" ;
VAL_ 504 BCmPKeUnlockActiveSignalVal 1 "Active value for vehicle Unlock with PKE feature is Double Stage Unlock " 0 "Active value for vehicle Unlock with PKE feature is Single Stage Unlock" ;
VAL_ 504 BCmRKeUnlockActiveSignalVal 1 "Active value for vehicle Unlock with RKE feature is Double Stage Unlock" 0 "Active value for vehicle Unlock with RKE feature is Single Stage Unlock" ;
VAL_ 504 BCmDriveAwayLockingState 1 "Drive Away Locking feature is enabled in BCM" 0 "Drive Away Locking feature is disabled in BCM" ;
VAL_ 504 BCmApproachLampSignalVal2 31 "Reserved" 30 "Reserved" 29 "Reserved" 28 "Reserved" 27 "Reserved" 26 "Reserved" 25 "Reserved" 24 "Possible value selected is 240" 23 "Possible value selected is 230" 22 "Possible value selected is 220" 21 "Possible value selected is 210" 20 "Possible value selected is 200" 19 "Possible value selected is 190" 18 "Possible value selected is 180" 17 "Possible value selected is 170" 16 "Possible value selected is 160" 15 "Possible value selected is 150" 14 "Possible value selected is 140" 13 "Possible value selected is 130" 12 "Possible value selected is 120" 11 "Possible value selected is 110" 10 "Possible value selected is 100" 9 "Possible value selected is 90" 8 "Possible value selected is 80" 7 "Possible value selected is 70" 6 "Possible value selected is 60" 5 "Possible value selected is 50" 4 "Possible value selected is 40" 3 "Possible value selected is 30" 2 "Possible value selected is 20" 1 "Possible value selected is 10" 0 "Possible value selected is 0" ;
VAL_ 504 AmbLightModeIllumOnHu 1 "Mode and Illumination Display is Enabled" 0 "Mode and Illumination Display is Disabled" ;
VAL_ 504 BCmApproachLampState 1 "Approach Lamp feature is enabled in BCM" 0 "Approach Lamp feature is disabled in BCM" ;
VAL_ 504 BCmVehLockHornReqState 1 "Horn request feature on vehicle lock is enabled in BCM" 0 "Horn request feature on vehicle lock is disabled in BCM" ;
VAL_ 504 BCmApproachLampSignalVal3 31 "Reserved" 30 "Reserved" 29 "Reserved" 28 "Reserved" 27 "Reserved" 26 "Reserved" 25 "Reserved" 24 "Possible value selected is 240" 23 "Possible value selected is 230" 22 "Possible value selected is 220" 21 "Possible value selected is 210" 20 "Possible value selected is 200" 19 "Possible value selected is 190" 18 "Possible value selected is 180" 17 "Possible value selected is 170" 16 "Possible value selected is 160" 15 "Possible value selected is 150" 14 "Possible value selected is 140" 13 "Possible value selected is 130" 12 "Possible value selected is 120" 11 "Possible value selected is 110" 10 "Possible value selected is 100" 9 "Possible value selected is 90" 8 "Possible value selected is 80" 7 "Possible value selected is 70" 6 "Possible value selected is 60" 5 "Possible value selected is 50" 4 "Possible value selected is 40" 3 "Possible value selected is 30" 2 "Possible value selected is 20" 1 "Possible value selected is 10" 0 "Possible value selected is 0" ;
VAL_ 504 BCmDRLActiveSignalVal 1 "Active value for DRL feature is Enabled" 0 "Active value for DRL feature is Disabled " ;
VAL_ 504 BCmDRLState 1 "DRL feature is enabled in BCM" 0 "DRL feature is disabled in BCM" ;
VAL_ 504 BCmMoodLightState 1 "Mood lighting selection on HU is Enabled" 0 "Mood lighting selection on HU is Disabled" ;
VAL_ 504 BCmUcsData 3 "Reserved" 2 "BCM sends UCS data to HU" 1 "BCM Acknowledges the UCS data" 0 "Reserved" ;
VAL_ 505 BCmMoodLightAllAreaActiveValue 1 "ON" 0 "OFF" ;
VAL_ 505 BCmMoodLightIllumSelActiveVal 7 "Reserved" 6 "Reserved" 5 "Level 5 Intensity" 4 "Level 4 Intensity" 3 "Level 3 Intensity" 2 "Level 2 Intensity" 1 "Level 1 Intensity" 0 "Reserved" ;
VAL_ 505 BCmMoodLightActiveColour 15 "Cyan Blue" 14 "Teal Green" 13 "French Lime" 12 "Gold Yellow" 11 "Tuscan Red" 10 "Aero Blue" 9 "Hot Magenta" 8 "Purple Taupe" 7 "Ruby (Red)" 6 "Fluorescent Green" 5 "Orange" 4 "Purple" 3 "Ivory (Off White)" 2 "Polar(Bright White)" 1 "Cool Blue" 0 "Ice Blue" ;
VAL_ 505 BCmMoodLightRearAreaActiveValue 1 "ON" 0 "OFF" ;
VAL_ 505 BCmMoodLightFrontRHAreaActiveVal 1 "ON" 0 "OFF" ;
VAL_ 505 BCmMoodLightFloorConsoleAreaActi 1 "ON" 0 "OFF" ;
VAL_ 505 BCmMoodLightData 3 "Reserved" 2 "BCM sends Mood light data to HU" 1 "BCM Acknowledges the Mood light data sent by HU" 0 "Reserved" ;
VAL_ 505 BCmMoodLightIllumPossibleLevels 7 "Reserved" 6 "Reserved" 5 "Intensity5" 4 "Intensity4" 3 "Intensity3" 2 "Intensity2" 1 "Intensity1" 0 "Reserved" ;
VAL_ 505 BCmMoodLightHotMagentaColorSelOn 1 "Present" 0 "Not Present" ;
VAL_ 505 BCmMoodLightGoldYellowColorSelOn 1 "Present" 0 "Not Present" ;
VAL_ 505 BCmMoodLightFrenchLimeColorSelOn 1 "Present" 0 "Not Present" ;
VAL_ 505 BCmMoodLightFrontLHAreaActiveVal 1 "ON" 0 "OFF" ;
VAL_ 505 BCmMoodLightPossibleModes 3 "AUTO, OFF, ON" 2 "OFF, ON" 1 "No Mode selection" 0 "Reserved" ;
VAL_ 505 BCmMoodLightActiveModeValue 3 "Reserved" 2 "ON" 1 "OFF" 0 "AUTO" ;
VAL_ 505 BCmMoodLightPolarBrightWhiteColo 1 "Present" 0 "Not Present" ;
VAL_ 505 BCmMoodLightAeroBlueColorSelOnHU 1 "Present" 0 "Not Present" ;
VAL_ 505 BCmMoodLightPurpleColorSelOnHU 1 "Present" 0 "Not Present" ;
VAL_ 505 BCmMoodLightFluorescentGreenColo 1 "Present" 0 "Not Present" ;
VAL_ 505 BCmMoodLightCyanBlueColorSelOnHU 1 "Present" 0 "Not Present" ;
VAL_ 505 BCmMoodLightCoolBlueColorSelOnHU 1 "Present" 0 "Not Present" ;
VAL_ 505 BCmMoodLightIvoryOFFWhiteColorSe 1 "Present" 0 "Not Present" ;
VAL_ 505 BCmMoodLightIceBlueColorSelOnHU 1 "Present" 0 "Not Present" ;
VAL_ 505 BCmMoodLightTuscanRedColorSelOnH 1 "Present" 0 "Not Present" ;
VAL_ 505 BCmMoodLightTealGreenColorSelOnH 1 "Present" 0 "Not Present" ;
VAL_ 505 BCmMoodLightRubyRedColorSelOnHU 1 "Present" 0 "Not Present" ;
VAL_ 505 BCmMoodLightOrangeColorSelOnHU 1 "Present" 0 "Not Present" ;
VAL_ 505 BCmMoodLightPurpleTaupeColorSelO 1 "Present" 0 "Not Present" ;
VAL_ 505 BCmMoodLightLocationSel 1 "Mood lighting location selection on HU is Enabled" 0 "Mood lighting location selection on HU is Disabled" ;
VAL_ 505 BCmMoodLightAllAreaSelOnHU 1 "Present" 0 "Not Present" ;
VAL_ 505 BCmMoodLightFrontLHAreaSelOnHU 1 "Present" 0 "Not Present" ;
VAL_ 505 BCmMoodLightRearAreaSelOnHU 1 "Present" 0 "Not Present" ;
VAL_ 505 BCmMoodLightFloorConsoleAreaSelO 1 "Present" 0 "Not Present" ;
VAL_ 505 BCmMoodLightState 1 "Mood lighting selection on HU is Enabled" 0 "Mood lighting selection on HU is Disabled" ;
VAL_ 505 BCmMoodLightFrontRHAreaSelOnHU 1 "Present" 0 "Not Present" ;
